VERSION ""

NS_ :

BS_:

BU_: IDC Delete_FDCA Delete_APA Delete_CMRR_FL Delete_CMRR_FR CMRR_RL CMRR_RR MRR CGW

BO_ 659 APA_6: 64 IDC
 SG_ APASlot_1_source : 2|3@0+ (1,0) [0|3] "" CGW
 SG_ APASlot__1_Direction : 4|2@0+ (1,0) [0|2] "" CGW
 SG_ APASlot_2_source : 7|3@0+ (1,0) [0|3] "" CGW
 SG_ APASlot_3_source : 10|3@0+ (1,0) [0|3] "" CGW
 SG_ APASlot__2_Direction : 12|2@0+ (1,0) [0|2] "" CGW
 SG_ APASlot_4_source : 15|3@0+ (1,0) [0|3] "" CGW
 SG_ APASlot_5_source : 18|3@0+ (1,0) [0|3] "" CGW
 SG_ APASlot__3_Direction : 20|2@0+ (1,0) [0|2] "" CGW
 SG_ APASlot_6_source : 23|3@0+ (1,0) [0|3] "" CGW
 SG_ APASlot_7_source : 26|3@0+ (1,0) [0|3] "" CGW
 SG_ APASlot__4_Direction : 28|2@0+ (1,0) [0|2] "" CGW
 SG_ APASlot_8_source : 31|3@0+ (1,0) [0|3] "" CGW
 SG_ APASlot_9_source : 34|3@0+ (1,0) [0|3] "" CGW
 SG_ APASlot__5_Direction : 36|2@0+ (1,0) [0|2] "" CGW
 SG_ APASlot_10_source : 39|3@0+ (1,0) [0|3] "" CGW
 SG_ APASlot_11_source : 42|3@0+ (1,0) [0|3] "" CGW
 SG_ APASlot__6_Direction : 44|2@0+ (1,0) [0|2] "" CGW
 SG_ APASlot_12_source : 47|3@0+ (1,0) [0|3] "" CGW
 SG_ APASlot__7_Direction : 49|2@0+ (1,0) [0|2] "" CGW
 SG_ APASlot__8_Direction : 51|2@0+ (1,0) [0|2] "" CGW
 SG_ APASlot__9_Direction : 53|2@0+ (1,0) [0|2] "" CGW
 SG_ APASlot__10_Direction : 55|2@0+ (1,0) [0|2] "" CGW
 SG_ APASlot__11_Direction : 57|2@0+ (1,0) [0|2] "" CGW
 SG_ APASlot__12_Direction : 59|2@0+ (1,0) [0|2] "" CGW
 SG_ APASlot__13_Direction : 61|2@0+ (1,0) [0|2] "" CGW
 SG_ APASlot__14_Direction : 63|2@0+ (1,0) [0|2] "" CGW
 SG_ APASlot__1_Type : 65|2@0+ (1,0) [0|3] "" CGW
 SG_ APASlot__2_Type : 67|2@0+ (1,0) [0|3] "" CGW
 SG_ APASlot__3_Type : 69|2@0+ (1,0) [0|3] "" CGW
 SG_ APASlot__4_Type : 71|2@0+ (1,0) [0|3] "" CGW
 SG_ APASlot__5_Type : 73|2@0+ (1,0) [0|3] "" CGW
 SG_ APASlot__6_Type : 75|2@0+ (1,0) [0|3] "" CGW
 SG_ APASlot__7_Type : 77|2@0+ (1,0) [0|3] "" CGW
 SG_ APASlot__8_Type : 79|2@0+ (1,0) [0|3] "" CGW
 SG_ APASlot__9_Type : 81|2@0+ (1,0) [0|3] "" CGW
 SG_ APASlot__10_Type : 83|2@0+ (1,0) [0|3] "" CGW
 SG_ APASlot__11_Type : 85|2@0+ (1,0) [0|3] "" CGW
 SG_ APASlot__12_Type : 87|2@0+ (1,0) [0|3] "" CGW
 SG_ SlotTarg_ID : 95|8@0+ (1,0) [1|255] "" CGW
 SG_ Slot1_ID : 103|8@0+ (1,0) [1|255] "" CGW
 SG_ Slot2_ID : 111|8@0+ (1,0) [1|255] "" CGW
 SG_ Slot3_ID : 119|8@0+ (1,0) [1|255] "" CGW
 SG_ Slot4_ID : 127|8@0+ (1,0) [1|255] "" CGW
 SG_ Slot5_ID : 135|8@0+ (1,0) [1|255] "" CGW
 SG_ Slot6_ID : 143|8@0+ (1,0) [1|255] "" CGW
 SG_ Slot7_ID : 151|8@0+ (1,0) [1|255] "" CGW
 SG_ Slot8_ID : 159|8@0+ (1,0) [1|255] "" CGW
 SG_ Slot9_ID : 167|8@0+ (1,0) [1|255] "" CGW
 SG_ Slot10_ID : 175|8@0+ (1,0) [1|255] "" CGW
 SG_ Slot11_ID : 183|8@0+ (1,0) [1|255] "" CGW
 SG_ Slot12_ID : 191|8@0+ (1,0) [1|255] "" CGW
 SG_ SlotTargACoorX : 199|8@0+ (12,-2000) [-2000|1060] "cm" CGW
 SG_ SlotTargACoorY : 207|8@0+ (16,-2000) [-2000|2080] "cm" CGW
 SG_ SlotTargBCoorX : 215|8@0+ (12,-2000) [-2000|1060] "cm" CGW
 SG_ SlotTargBCoorY : 223|8@0+ (16,-2000) [-2000|2080] "cm" CGW
 SG_ SlotTargCCoorX : 231|8@0+ (12,-2000) [-2000|1060] "cm" CGW
 SG_ SlotTargCCoorY : 239|8@0+ (16,-2000) [-2000|2080] "cm" CGW
 SG_ SlotTargDCoorX : 247|8@0+ (12,-2000) [-2000|1060] "cm" CGW
 SG_ SlotTargDCoorY : 255|8@0+ (16,-2000) [-2000|2080] "cm" CGW
 SG_ Slot1ACoorX : 263|8@0+ (12,-2000) [-2000|1060] "cm" CGW
 SG_ Slot1ACoorY : 271|8@0+ (16,-2000) [-2000|2080] "cm" CGW
 SG_ Slot1BCoorX : 279|8@0+ (12,-2000) [-2000|1060] "cm" CGW
 SG_ Slot1BCoorY : 287|8@0+ (16,-2000) [-2000|2080] "cm" CGW
 SG_ Slot1CCoorX : 295|8@0+ (12,-2000) [-2000|1060] "cm" CGW
 SG_ Slot1CCoorY : 303|8@0+ (16,-2000) [-2000|2080] "cm" CGW
 SG_ Slot1DCoorX : 311|8@0+ (12,-2000) [-2000|1060] "cm" CGW
 SG_ Slot1DCoorY : 319|8@0+ (16,-2000) [-2000|2080] "cm" CGW
 SG_ Slot2ACoorX : 327|8@0+ (12,-2000) [-2000|1060] "cm" CGW
 SG_ Slot2ACoorY : 335|8@0+ (16,-2000) [-2000|2080] "cm" CGW
 SG_ Slot2BCoorX : 343|8@0+ (12,-2000) [-2000|1060] "cm" CGW
 SG_ Slot2BCoorY : 351|8@0+ (16,-2000) [-2000|2080] "cm" CGW
 SG_ Slot2CCoorX : 359|8@0+ (12,-2000) [-2000|1060] "cm" CGW
 SG_ Slot2CCoorY : 367|8@0+ (16,-2000) [-2000|2080] "cm" CGW
 SG_ Slot2DCoorX : 375|8@0+ (12,-2000) [-2000|1060] "cm" CGW
 SG_ Slot2DCoorY : 383|8@0+ (16,-2000) [-2000|2080] "cm" CGW
 SG_ Slot3ACoorX : 391|8@0+ (12,-2000) [-2000|1060] "cm" CGW
 SG_ Slot3ACoorY : 399|8@0+ (16,-2000) [-2000|2080] "cm" CGW
 SG_ Slot3BCoorX : 407|8@0+ (12,-2000) [-2000|1060] "cm" CGW
 SG_ Slot3BCoorY : 415|8@0+ (16,-2000) [-2000|2080] "cm" CGW
 SG_ Slot3CCoorX : 423|8@0+ (12,-2000) [-2000|1060] "cm" CGW
 SG_ Slot3CCoorY : 431|8@0+ (16,-2000) [-2000|2080] "cm" CGW
 SG_ Slot3DCoorX : 439|8@0+ (12,-2000) [-2000|1060] "cm" CGW
 SG_ Slot3DCoorY : 447|8@0+ (16,-2000) [-2000|2080] "cm" CGW
 SG_ Slot4ACoorX : 455|8@0+ (12,-2000) [-2000|1060] "cm" CGW
 SG_ Slot4ACoorY : 463|8@0+ (16,-2000) [-2000|2080] "cm" CGW
 SG_ Slot4BCoorX : 471|8@0+ (12,-2000) [-2000|1060] "cm" CGW
 SG_ Slot4BCoorY : 479|8@0+ (16,-2000) [-2000|2080] "cm" CGW
 SG_ Slot4CCoorX : 487|8@0+ (12,-2000) [-2000|1060] "cm" CGW
 SG_ Slot4CCoorY : 495|8@0+ (16,-2000) [-2000|2080] "cm" CGW
 SG_ Slot4DCoorX : 503|8@0+ (12,-2000) [-2000|1060] "cm" CGW
 SG_ Slot4DCoorY : 511|8@0+ (16,-2000) [-2000|2080] "cm" CGW

BO_ 660 APA_7: 64 IDC
 SG_ Slot5ACoorX : 7|8@0+ (12,-2000) [-2000|1060] "cm" CGW
 SG_ Slot5ACoorY : 15|8@0+ (16,-2000) [-2000|2080] "cm" CGW
 SG_ Slot5BCoorX : 23|8@0+ (12,-2000) [-2000|1060] "cm" CGW
 SG_ Slot5BCoorY : 31|8@0+ (16,-2000) [-2000|2080] "cm" CGW
 SG_ Slot5CCoorX : 39|8@0+ (12,-2000) [-2000|1060] "cm" CGW
 SG_ Slot5CCoorY : 47|8@0+ (16,-2000) [-2000|2080] "cm" CGW
 SG_ Slot5DCoorX : 55|8@0+ (12,-2000) [-2000|1060] "cm" CGW
 SG_ Slot5DCoorY : 63|8@0+ (16,-2000) [-2000|2080] "cm" CGW
 SG_ Slot6ACoorX : 71|8@0+ (12,-2000) [-2000|1060] "cm" CGW
 SG_ Slot6ACoorY : 79|8@0+ (16,-2000) [-2000|2080] "cm" CGW
 SG_ Slot6BCoorX : 87|8@0+ (12,-2000) [-2000|1060] "cm" CGW
 SG_ Slot6BCoorY : 95|8@0+ (16,-2000) [-2000|2080] "cm" CGW
 SG_ Slot6CCoorX : 103|8@0+ (12,-2000) [-2000|1060] "cm" CGW
 SG_ Slot6CCoorY : 111|8@0+ (16,-2000) [-2000|2080] "cm" CGW
 SG_ Slot6DCoorX : 119|8@0+ (12,-2000) [-2000|1060] "cm" CGW
 SG_ Slot6DCoorY : 127|8@0+ (16,-2000) [-2000|2080] "cm" CGW
 SG_ Slot7ACoorX : 135|8@0+ (12,-2000) [-2000|1060] "cm" CGW
 SG_ Slot7ACoorY : 143|8@0+ (16,-2000) [-2000|2080] "cm" CGW
 SG_ Slot7BCoorX : 151|8@0+ (12,-2000) [-2000|1060] "cm" CGW
 SG_ Slot7BCoorY : 159|8@0+ (16,-2000) [-2000|2080] "cm" CGW
 SG_ Slot7CCoorX : 167|8@0+ (12,-2000) [-2000|1060] "cm" CGW
 SG_ Slot7CCoorY : 175|8@0+ (16,-2000) [-2000|2080] "cm" CGW
 SG_ Slot7DCoorX : 183|8@0+ (12,-2000) [-2000|1060] "cm" CGW
 SG_ Slot7DCoorY : 191|8@0+ (16,-2000) [-2000|2080] "cm" CGW
 SG_ Slot8ACoorX : 199|8@0+ (12,-2000) [-2000|1060] "cm" CGW
 SG_ Slot8ACoorY : 207|8@0+ (16,-2000) [-2000|2080] "cm" CGW
 SG_ Slot8BCoorX : 215|8@0+ (12,-2000) [-2000|1060] "cm" CGW
 SG_ Slot8BCoorY : 223|8@0+ (16,-2000) [-2000|2080] "cm" CGW
 SG_ Slot8CCoorX : 231|8@0+ (12,-2000) [-2000|1060] "cm" CGW
 SG_ Slot8CCoorY : 239|8@0+ (16,-2000) [-2000|2080] "cm" CGW
 SG_ Slot8DCoorX : 247|8@0+ (12,-2000) [-2000|1060] "cm" CGW
 SG_ Slot8DCoorY : 255|8@0+ (16,-2000) [-2000|2080] "cm" CGW
 SG_ Slot9ACoorX : 263|8@0+ (12,-2000) [-2000|1060] "cm" CGW
 SG_ Slot9ACoorY : 271|8@0+ (16,-2000) [-2000|2080] "cm" CGW
 SG_ Slot9BCoorX : 279|8@0+ (12,-2000) [-2000|1060] "cm" CGW
 SG_ Slot9BCoorY : 287|8@0+ (16,-2000) [-2000|2080] "cm" CGW
 SG_ Slot9CCoorX : 295|8@0+ (12,-2000) [-2000|1060] "cm" CGW
 SG_ Slot9CCoorY : 303|8@0+ (16,-2000) [-2000|2080] "cm" CGW
 SG_ Slot9DCoorX : 311|8@0+ (12,-2000) [-2000|1060] "cm" CGW
 SG_ Slot9DCoorY : 319|8@0+ (16,-2000) [-2000|2080] "cm" CGW
 SG_ Slot10ACoorX : 327|8@0+ (12,-2000) [-2000|1060] "cm" CGW
 SG_ Slot10ACoorY : 335|8@0+ (16,-2000) [-2000|2080] "cm" CGW
 SG_ Slot10BCoorX : 343|8@0+ (12,-2000) [-2000|1060] "cm" CGW
 SG_ Slot10BCoorY : 351|8@0+ (16,-2000) [-2000|2080] "cm" CGW
 SG_ Slot10CCoorX : 359|8@0+ (12,-2000) [-2000|1060] "cm" CGW
 SG_ Slot10CCoorY : 367|8@0+ (16,-2000) [-2000|2080] "cm" CGW
 SG_ Slot10DCoorX : 375|8@0+ (12,-2000) [-2000|1060] "cm" CGW
 SG_ Slot10DCoorY : 383|8@0+ (16,-2000) [-2000|2080] "cm" CGW
 SG_ Slot11ACoorX : 391|8@0+ (12,-2000) [-2000|1060] "cm" CGW
 SG_ Slot11ACoorY : 399|8@0+ (16,-2000) [-2000|2080] "cm" CGW
 SG_ Slot11BCoorX : 407|8@0+ (12,-2000) [-2000|1060] "cm" CGW
 SG_ Slot11BCoorY : 415|8@0+ (16,-2000) [-2000|2080] "cm" CGW
 SG_ Slot11CCoorX : 423|8@0+ (12,-2000) [-2000|1060] "cm" CGW
 SG_ Slot11CCoorY : 431|8@0+ (16,-2000) [-2000|2080] "cm" CGW
 SG_ Slot11DCoorX : 439|8@0+ (12,-2000) [-2000|1060] "cm" CGW
 SG_ Slot11DCoorY : 447|8@0+ (16,-2000) [-2000|2080] "cm" CGW
 SG_ Slot12ACoorX : 455|8@0+ (12,-2000) [-2000|1060] "cm" CGW
 SG_ Slot12ACoorY : 463|8@0+ (16,-2000) [-2000|2080] "cm" CGW
 SG_ Slot12BCoorX : 471|8@0+ (12,-2000) [-2000|1060] "cm" CGW
 SG_ Slot12BCoorY : 479|8@0+ (16,-2000) [-2000|2080] "cm" CGW
 SG_ Slot12CCoorX : 487|8@0+ (12,-2000) [-2000|1060] "cm" CGW
 SG_ Slot12CCoorY : 495|8@0+ (16,-2000) [-2000|2080] "cm" CGW
 SG_ Slot12DCoorX : 503|8@0+ (12,-2000) [-2000|1060] "cm" CGW
 SG_ Slot12DCoorY : 511|8@0+ (16,-2000) [-2000|2080] "cm" CGW

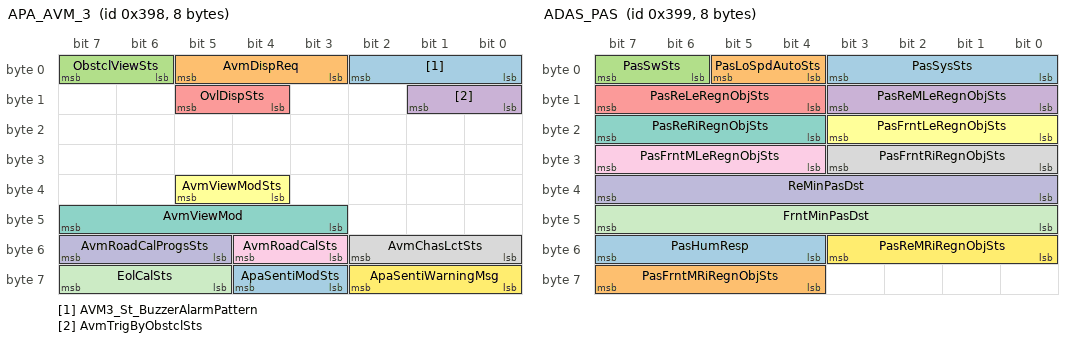
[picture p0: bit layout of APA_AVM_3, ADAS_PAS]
BO_ 920 APA_AVM_3: 8 IDC
 SG_ AVM3_St_BuzzerAlarmPattern : 2|3@0+ (1,0) [0|7] "" CGW
 SG_ AvmDispReq : 5|3@0+ (1,0) [0|7] "" CGW
 SG_ ObstclViewSts : 7|2@0+ (1,0) [0|3] "" CGW
 SG_ AvmTrigByObstclSts : 9|2@0+ (1,0) [0|3] "" CGW
 SG_ OvlDispSts : 13|2@0+ (1,0) [0|3] "" CGW
 SG_ AvmViewModSts : 37|2@0+ (1,0) [0|3] "" CGW
 SG_ AvmViewMod : 47|5@0+ (1,0) [0|31] "" CGW
 SG_ AvmChasLctSts : 50|3@0+ (1,0) [0|7] "" CGW
 SG_ AvmRoadCalSts : 52|2@0+ (1,0) [0|3] "" CGW
 SG_ AvmRoadCalProgsSts : 55|3@0+ (1,0) [0|7] "" CGW
 SG_ EolCalSts : 63|3@0+ (1,0) [0|7] "" CGW
 SG_ ApaSentiWarningMsg : 58|3@0+ (1,0) [0|7] "" CGW
 SG_ ApaSentiModSts : 60|2@0+ (1,0) [0|3] "" CGW

BO_ 921 ADAS_PAS: 8 IDC
 SG_ PasSysSts : 3|4@0+ (1,0) [0|7] "" CGW
 SG_ PasLoSpdAutoSts : 5|2@0+ (1,0) [0|3] "" CGW
 SG_ PasSwSts : 7|2@0+ (1,0) [0|3] "" CGW
 SG_ PasReMLeRegnObjSts : 11|4@0+ (1,0) [0|15] "" CGW
 SG_ PasReLeRegnObjSts : 15|4@0+ (1,0) [0|15] "" CGW
 SG_ PasFrntLeRegnObjSts : 19|4@0+ (1,0) [0|15] "" CGW
 SG_ PasReRiRegnObjSts : 23|4@0+ (1,0) [0|15] "" CGW
 SG_ PasFrntRiRegnObjSts : 27|4@0+ (1,0) [0|15] "" CGW
 SG_ PasFrntMLeRegnObjSts : 31|4@0+ (1,0) [0|15] "" CGW
 SG_ ReMinPasDst : 39|8@0+ (1,0) [0|255] "cm" CGW
 SG_ FrntMinPasDst : 47|8@0+ (1,0) [0|255] "cm" CGW
 SG_ PasReMRiRegnObjSts : 51|4@0+ (1,0) [0|15] "" CGW
 SG_ PasHumResp : 55|4@0+ (1,0) [0|15] "" CGW
 SG_ PasFrntMRiRegnObjSts : 63|4@0+ (1,0) [0|15] "" CGW

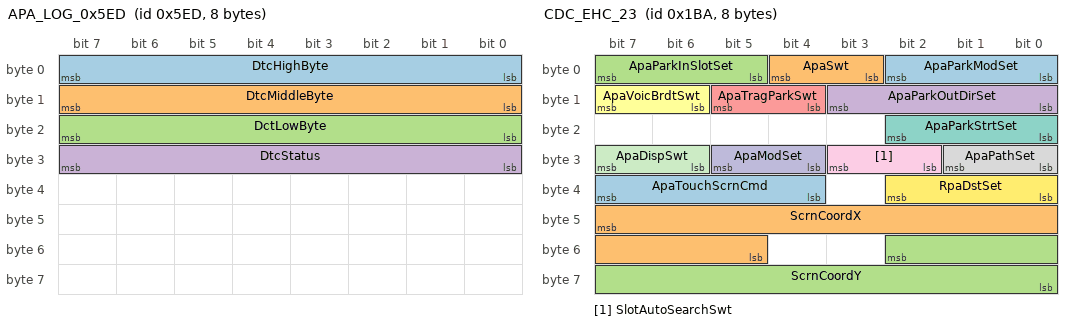
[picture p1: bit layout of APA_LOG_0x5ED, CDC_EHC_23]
BO_ 1517 APA_LOG_0x5ED: 8 IDC
 SG_ DtcHighByte : 7|8@0+ (1,0) [0|255] "" CGW
 SG_ DtcMiddleByte : 15|8@0+ (1,0) [0|255] "" Vector__XXX
 SG_ DctLowByte : 23|8@0+ (1,0) [0|255] "" Vector__XXX
 SG_ DtcStatus : 31|8@0+ (1,0) [0|255] "" Vector__XXX

BO_ 442 CDC_EHC_23: 8 CGW
 SG_ ApaParkModSet : 2|3@0+ (1,0) [0|7] "" IDC,Delete_APA
 SG_ ApaSwt : 4|2@0+ (1,0) [0|3] "" IDC,Delete_APA
 SG_ ApaParkInSlotSet : 7|3@0+ (1,0) [0|7] "" IDC,Delete_APA
 SG_ ApaParkOutDirSet : 11|4@0+ (1,0) [0|15] "" IDC,Delete_APA
 SG_ ApaTragParkSwt : 13|2@0+ (1,0) [0|3] "" IDC,Delete_APA
 SG_ ApaVoicBrdtSwt : 15|2@0+ (1,0) [0|3] "" IDC,Delete_APA
 SG_ ApaParkStrtSet : 18|3@0+ (1,0) [0|7] "" IDC,Delete_APA
 SG_ ApaPathSet : 25|2@0+ (1,0) [0|3] "" IDC,Delete_APA
 SG_ SlotAutoSearchSwt : 27|2@0+ (1,0) [0|3] "" IDC,Delete_APA
 SG_ ApaModSet : 29|2@0+ (1,0) [0|3] "" IDC,Delete_APA
 SG_ ApaDispSwt : 31|2@0+ (1,0) [0|3] "" IDC,Delete_APA
 SG_ RpaDstSet : 34|3@0+ (1,0) [0|7] "" IDC,Delete_APA
 SG_ ApaTouchScrnCmd : 39|4@0+ (1,0) [0|15] "" IDC,Delete_APA
 SG_ ScrnCoordX : 47|11@0+ (1,0) [0|1919] "" IDC,Delete_APA
 SG_ ScrnCoordY : 50|11@0+ (1,0) [0|1079] "" IDC,Delete_APA

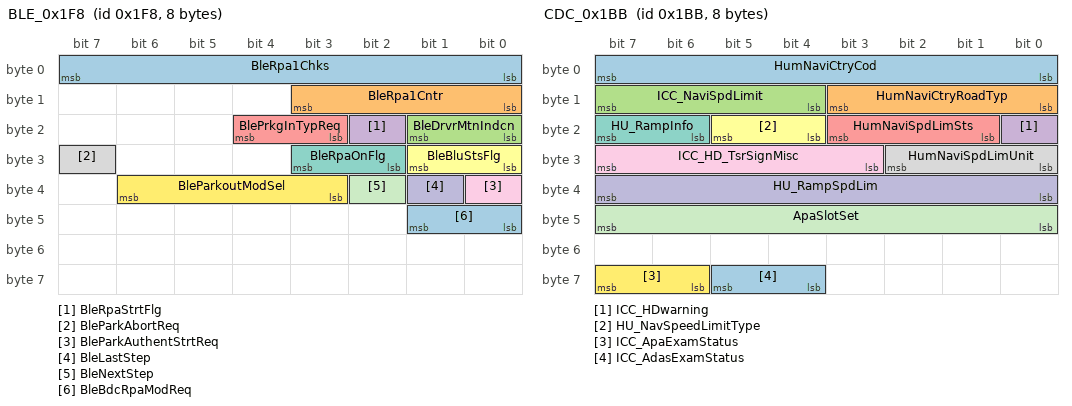
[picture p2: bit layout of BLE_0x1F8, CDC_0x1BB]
BO_ 504 BLE_0x1F8: 8 CGW
 SG_ BleRpa1Chks : 7|8@0+ (1,0) [0|255] "" IDC,Delete_APA
 SG_ BleRpa1Cntr : 11|4@0+ (1,0) [0|14] "" IDC,Delete_APA
 SG_ BleDrvrMtnIndcn : 17|2@0+ (1,0) [0|3] "" IDC,Delete_APA
 SG_ BleRpaStrtFlg : 18|1@0+ (1,0) [0|1] "" IDC,Delete_APA
 SG_ BlePrkgInTypReq : 20|2@0+ (1,0) [0|3] "" IDC,Delete_APA
 SG_ BleBluStsFlg : 25|2@0+ (1,0) [0|3] "" IDC,Delete_APA
 SG_ BleRpaOnFlg : 27|2@0+ (1,0) [0|3] "" IDC,Delete_APA
 SG_ BleParkAbortReq : 31|1@0+ (1,0) [0|1] "" IDC,Delete_APA
 SG_ BleParkAuthentStrtReq : 32|1@0+ (1,0) [0|1] "" IDC,Delete_APA
 SG_ BleLastStep : 33|1@0+ (1,0) [0|1] "" IDC,Delete_APA
 SG_ BleNextStep : 34|1@0+ (1,0) [0|1] "" IDC,Delete_APA
 SG_ BleParkoutModSel : 38|4@0+ (1,0) [0|15] "" IDC,Delete_APA
 SG_ BleBdcRpaModReq : 41|2@0+ (1,0) [0|3] "" IDC,Delete_APA

BO_ 822 BLE_0x336: 8 CGW
 SG_ BleStrtEng : 1|1@0+ (1,0) [0|1] "" IDC,Delete_APA
 SG_ BleBtSts : 60|2@0+ (1,0) [0|3] "" IDC,Delete_APA

BO_ 823 BLE_0x337: 8 CGW
 SG_ BleSysSts : 7|1@0+ (1,0) [0|1] "" IDC,Delete_APA

BO_ 443 CDC_0x1BB: 8 CGW
 SG_ HumNaviCtryCod : 7|8@0+ (1,0) [0|255] "" IDC,Delete_FDCA
 SG_ HumNaviCtryRoadTyp : 11|4@0+ (1,0) [0|15] "" IDC,Delete_FDCA
 SG_ ICC_NaviSpdLimit : 15|4@0+ (1,0) [0|15] "KPH" IDC,Delete_FDCA
 SG_ ICC_HDwarning : 16|1@0+ (1,0) [0|1] "" IDC,Delete_FDCA
 SG_ HumNaviSpdLimSts : 19|3@0+ (1,0) [0|7] "" IDC,Delete_FDCA
 SG_ HU_NavSpeedLimitType : 21|2@0+ (1,0) [0|3] "" IDC,Delete_FDCA
 SG_ HU_RampInfo : 23|2@0+ (1,0) [0|3] "" IDC,Delete_FDCA
 SG_ HumNaviSpdLimUnit : 26|3@0+ (1,0) [0|7] "" IDC,Delete_FDCA
 SG_ ICC_HD_TsrSignMisc : 31|5@0+ (1,0) [0|31] "" IDC,Delete_FDCA
 SG_ HU_RampSpdLim : 39|8@0+ (1,0) [0|255] "" IDC,Delete_FDCA
 SG_ ApaSlotSet : 47|8@0+ (1,0) [0|255] "" IDC,Delete_FDCA,Delete_APA
 SG_ ICC_ApaExamStatus : 63|2@0+ (1,0) [0|3] "" IDC
 SG_ ICC_AdasExamStatus : 61|2@0+ (1,0) [0|3] "" IDC

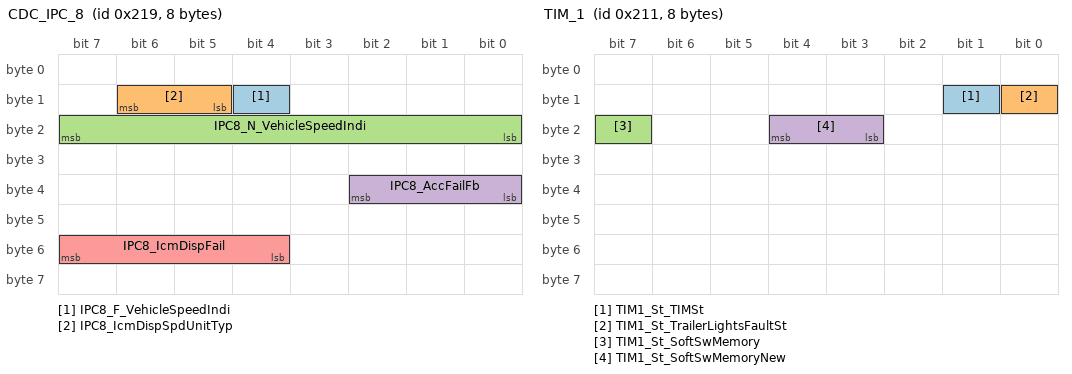
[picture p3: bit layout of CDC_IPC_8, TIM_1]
BO_ 537 CDC_IPC_8: 8 CGW
 SG_ IPC8_F_VehicleSpeedIndi : 12|1@0+ (1,0) [0|1] "" IDC
 SG_ IPC8_IcmDispSpdUnitTyp : 14|2@0+ (1,0) [0|3] "" IDC,Delete_FDCA
 SG_ IPC8_N_VehicleSpeedIndi : 23|8@0+ (1,0) [0|255] "km/h" IDC,Delete_APA
 SG_ IPC8_AccFailFb : 34|3@0+ (1,0) [0|7] "" IDC,Delete_FDCA
 SG_ IPC8_IcmDispFail : 55|4@0+ (1,0) [0|15] "" IDC,Delete_FDCA

BO_ 858 BDC_BCM_12: 8 CGW
 SG_ BCM12_St_VehicleMode : 23|3@0+ (1,0) [0|7] "" IDC,Delete_FDCA,Delete_APA

BO_ 529 TIM_1: 8 CGW
 SG_ TIM1_St_TIMSt : 9|1@0+ (1,0) [0|1] "" IDC,Delete_FDCA,Delete_APA,Delete_CMRR_FL,Delete_CMRR_FR,CMRR_RL,CMRR_RR,MRR
 SG_ TIM1_St_TrailerLightsFaultSt : 8|1@0+ (1,0) [0|1] "" IDC,Delete_FDCA,Delete_APA,Delete_CMRR_FL,Delete_CMRR_FR,CMRR_RL,CMRR_RR,MRR
 SG_ TIM1_St_SoftSwMemory : 23|1@0+ (1,0) [0|1] "" IDC,Delete_FDCA,Delete_APA,Delete_CMRR_FL,Delete_CMRR_FR,CMRR_RL,CMRR_RR,MRR
 SG_ TIM1_St_SoftSwMemoryNew : 20|2@0+ (1,0) [0|3] "" IDC,CMRR_RL,CMRR_RR,MRR

BO_ 225 CDC_EHC_24: 8 CGW
 SG_ EHC12_St_AVMSaleCalibration : 18|2@0+ (1,0) [0|3] "" IDC,Delete_APA
 SG_ EHC24_ParkingPlaceConfirm : 19|1@0+ (1,0) [0|1] "" IDC,Delete_APA
 SG_ AvmViewSet : 31|5@0+ (1,0) [0|31] "" IDC,Delete_APA
 SG_ AvmViewModSet : 33|2@0+ (1,0) [0|3] "" IDC,Delete_APA
 SG_ OvlyDispSwt : 35|2@0+ (1,0) [0|3] "" IDC,Delete_APA
 SG_ ObstclViewSwt : 37|2@0+ (1,0) [0|3] "" IDC,Delete_APA
 SG_ AvmTrigByObstclSwt : 47|2@0+ (1,0) [0|3] "" IDC,Delete_APA
 SG_ AvmSwt : 45|2@0+ (1,0) [0|3] "" IDC,Delete_APA
 SG_ PasSwt : 43|2@0+ (1,0) [0|3] "" IDC,Delete_APA
 SG_ EHC24_ExitButton : 41|1@0+ (1,0) [0|1] "" IDC,Delete_APA
 SG_ EHC12_Set_RestoreSetting : 40|1@0+ (1,0) [0|1] "" IDC,Delete_APA
 SG_ AvmVehLctSet : 50|3@0+ (1,0) [0|7] "" IDC,Delete_APA
 SG_ EHC24_AVM_WormMode_Set : 51|1@0+ (1,0) [0|1] "" IDC,Delete_APA
 SG_ EHCV24_AVM_RockMode_Set : 52|1@0+ (1,0) [0|1] "" IDC,Delete_APA
 SG_ AvmChasLctSet : 55|3@0+ (1,0) [0|7] "" IDC,Delete_APA
 SG_ AvmRoadCalSwt : 58|2@0+ (1,0) [0|3] "" IDC,Delete_APA
 SG_ EHC12_St_SoftwareUpdate : 59|1@0+ (1,0) [0|1] "" IDC,Delete_APA
 SG_ EHC12_St_AVMRoadCalibration : 61|2@0+ (1,0) [0|3] "" IDC,Delete_APA
 SG_ EHC12_St_AVMFactoryCalibration : 63|2@0+ (1,0) [0|3] "" IDC,Delete_APA

BO_ 237 CDC_EHC_22: 8 CGW
 SG_ EHC22_NOA_ALCRequest_confirm : 7|2@0+ (1,0) [0|3] "" IDC,Delete_FDCA
 SG_ EHC22_NOA_ALC_TYPE : 5|2@0+ (1,0) [0|3] "" IDC,Delete_FDCA
 SG_ EHC22_NOA_ALC_soundnotification : 3|2@0+ (1,0) [0|3] "" IDC,Delete_FDCA
 SG_ EHC22_HWA_EnbSw : 1|2@0+ (1,0) [0|3] "" IDC,Delete_FDCA
 SG_ EHC22_TJA_ICA_EnbSw : 15|2@0+ (1,0) [0|3] "" IDC,Delete_FDCA
 SG_ EHC22_IntelligentCornering_EnbSw : 13|2@0+ (1,0) [0|3] "" IDC,Delete_FDCA
 SG_ EHC22_ESS_EnbSw : 11|2@0+ (1,0) [0|3] "" IDC,Delete_FDCA
 SG_ EHC22_LKA_EnbSw : 9|2@0+ (1,0) [0|3] "" IDC,Delete_FDCA
 SG_ EHC22_LDW_EnbSw : 23|2@0+ (1,0) [0|3] "" IDC,Delete_FDCA
 SG_ EHC22_BSD_LCA_EnbSw : 21|2@0+ (1,0) [0|3] "" IDC,Delete_FDCA,Delete_CMRR_FL,Delete_CMRR_FR,CMRR_RL,CMRR_RR,MRR
 SG_ EHC22_DOW_EnbSw : 19|2@0+ (1,0) [0|3] "" IDC,Delete_FDCA,Delete_CMRR_FL,Delete_CMRR_FR,CMRR_RL,CMRR_RR,MRR
 SG_ EHC22_ELK_EnbSw : 17|2@0+ (1,0) [0|3] "" IDC,Delete_FDCA
 SG_ EHC22_AVM_EnbSw : 31|2@0+ (1,0) [0|3] "" IDC,Delete_FDCA
 SG_ EHC22_HMA_EnbSw : 29|2@0+ (1,0) [0|3] "" IDC,Delete_FDCA
 SG_ EHC22_BAV_EnbSw : 27|2@0+ (1,0) [0|3] "" IDC,Delete_FDCA
 SG_ EHC22_LCK_EnbSw : 25|2@0+ (1,0) [0|3] "" IDC,Delete_FDCA
 SG_ EHC22_ASLSw : 33|2@0+ (1,0) [0|3] "" IDC,Delete_FDCA
 SG_ EHC22_Set_FcwSwt : 35|2@0+ (1,0) [0|3] "" IDC,Delete_FDCA
 SG_ EHC22_Set_FCTA : 37|2@0+ (1,0) [0|1] "" IDC,Delete_FDCA,Delete_CMRR_FL,Delete_CMRR_FR,CMRR_RL,CMRR_RR,MRR
 SG_ EHC22_Set_FCTB : 39|2@0+ (1,0) [0|1] "" IDC,Delete_FDCA,Delete_CMRR_FL,Delete_CMRR_FR,CMRR_RL,CMRR_RR,MRR
 SG_ EHC22_Set_LDWLKALCKSen : 41|2@0+ (1,0) [0|3] "" IDC,Delete_FDCA
 SG_ EHC22_Sw_LDWLKALCK : 43|2@0+ (1,0) [0|3] "" IDC,Delete_FDCA
 SG_ EHC22_St_LDWLKALCKSet : 46|3@0+ (1,0) [0|7] "" IDC,Delete_FDCA
 SG_ EHC22_NOAFct_EnbSw : 50|2@0+ (1,0) [0|3] "" IDC,Delete_FDCA
 SG_ EHC22_SDA_EnbSw : 53|2@0+ (1,0) [0|3] "" IDC,Delete_FDCA
 SG_ EHC22_Set_JA : 55|2@0+ (1,0) [0|3] "" IDC,Delete_FDCA,Delete_CMRR_FL,Delete_CMRR_FR,CMRR_RL,CMRR_RR,MRR
 SG_ EHC22_CDCShowoffset : 57|2@0+ (1,0) [0|3] "" IDC,Delete_FDCA
 SG_ EHC22_Set_ELKSen : 59|2@0+ (1,0) [0|3] "" IDC,Delete_FDCA

BO_ 661 APA_8: 64 IDC
 SG_ HPA_ObjLatDst1 : 7|8@0+ (0.1,-12.75) [-12.75|12.75] "m" CGW
 SG_ HPA_ObjLgtDst1 : 15|8@0+ (0.2,-25.5) [-25.5|25.5] "m" CGW
 SG_ HPA_ObjTyp1 : 23|4@0+ (1,0) [0|15] "" CGW
 SG_ HPA_ObjMovmtDir1 : 19|2@0+ (1,0) [0|3] "" CGW
 SG_ HPA_ObjPosnAgl1 : 17|10@0+ (0.01,-3.14) [-3.14|3.14] "rad" CGW
 SG_ HPA_ObjLatDst2 : 39|8@0+ (0.1,-12.75) [-12.75|12.75] "m" CGW
 SG_ HPA_ObjLgtDst2 : 47|8@0+ (0.2,-25.5) [-25.5|25.5] "m" CGW
 SG_ HPA_ObjTyp2 : 55|4@0+ (1,0) [0|15] "" CGW
 SG_ HPA_ObjMovmtDir2 : 51|2@0+ (1,0) [0|3] "" CGW
 SG_ HPA_ObjPosnAgl2 : 49|10@0+ (0.01,-3.14) [-3.14|3.14] "rad" CGW
 SG_ HPA_ObjLatDst3 : 71|8@0+ (0.1,-12.75) [-12.75|12.75] "m" CGW
 SG_ HPA_ObjLgtDst3 : 79|8@0+ (0.2,-25.5) [-25.5|25.5] "m" CGW
 SG_ HPA_ObjTyp3 : 87|4@0+ (1,0) [0|15] "" CGW
 SG_ HPA_ObjMovmtDir3 : 83|2@0+ (1,0) [0|3] "" CGW
 SG_ HPA_ObjPosnAgl3 : 81|10@0+ (0.01,-3.14) [-3.14|3.14] "rad" CGW
 SG_ HPA_ObjLatDst4 : 103|8@0+ (0.1,-12.75) [-12.75|12.75] "m" CGW
 SG_ HPA_ObjLgtDst4 : 111|8@0+ (0.2,-25.5) [-25.5|25.5] "m" CGW
 SG_ HPA_ObjTyp4 : 119|4@0+ (1,0) [0|15] "" CGW
 SG_ HPA_ObjMovmtDir4 : 115|2@0+ (1,0) [0|3] "" CGW
 SG_ HPA_ObjPosnAgl4 : 113|10@0+ (0.01,-3.14) [-3.14|3.14] "rad" CGW
 SG_ HPA_ObjLatDst5 : 135|8@0+ (0.1,-12.75) [-12.75|12.75] "m" CGW
 SG_ HPA_ObjLgtDst5 : 143|8@0+ (0.2,-25.5) [-25.5|25.5] "m" CGW
 SG_ HPA_ObjTyp5 : 151|4@0+ (1,0) [0|15] "" CGW
 SG_ HPA_ObjMovmtDir5 : 147|2@0+ (1,0) [0|3] "" CGW
 SG_ HPA_ObjPosnAgl5 : 145|10@0+ (0.01,-3.14) [-3.14|3.14] "rad" CGW
 SG_ HPA_ObjLatDst6 : 167|8@0+ (0.1,-12.75) [-12.75|12.75] "m" CGW
 SG_ HPA_ObjLgtDst6 : 175|8@0+ (0.2,-25.5) [-25.5|25.5] "m" CGW
 SG_ HPA_ObjTyp6 : 183|4@0+ (1,0) [0|15] "" CGW
 SG_ HPA_ObjMovmtDir6 : 179|2@0+ (1,0) [0|3] "" CGW
 SG_ HPA_ObjPosnAgl6 : 177|10@0+ (0.01,-3.14) [-3.14|3.14] "rad" CGW
 SG_ HPA_ObjLatDst7 : 199|8@0+ (0.1,-12.75) [-12.75|12.75] "m" CGW
 SG_ HPA_ObjLgtDst7 : 207|8@0+ (0.2,-25.5) [-25.5|25.5] "m" CGW
 SG_ HPA_ObjTyp7 : 215|4@0+ (1,0) [0|15] "" CGW
 SG_ HPA_ObjMovmtDir7 : 211|2@0+ (1,0) [0|3] "" CGW
 SG_ HPA_ObjPosnAgl7 : 209|10@0+ (0.01,-3.14) [-3.14|3.14] "rad" CGW
 SG_ HPA_ObjLatDst8 : 231|8@0+ (0.1,-12.75) [-12.75|12.75] "m" CGW
 SG_ HPA_ObjLgtDst8 : 239|8@0+ (0.2,-25.5) [-25.5|25.5] "m" CGW
 SG_ HPA_ObjTyp8 : 247|4@0+ (1,0) [0|15] "" CGW
 SG_ HPA_ObjMovmtDir8 : 243|2@0+ (1,0) [0|3] "" CGW
 SG_ HPA_ObjPosnAgl8 : 241|10@0+ (0.01,-3.14) [-3.14|3.14] "rad" CGW
 SG_ HPA_ObjLatDst9 : 263|8@0+ (0.1,-12.75) [-12.75|12.75] "m" CGW
 SG_ HPA_ObjLgtDst9 : 271|8@0+ (0.2,-25.5) [-25.5|25.5] "m" CGW
 SG_ HPA_ObjTyp9 : 279|4@0+ (1,0) [0|15] "" CGW
 SG_ HPA_ObjMovmtDir9 : 275|2@0+ (1,0) [0|3] "" CGW
 SG_ HPA_ObjPosnAgl9 : 273|10@0+ (0.01,-3.14) [-3.14|3.14] "rad" CGW
 SG_ HPA_ObjLatDst10 : 295|8@0+ (0.1,-12.75) [-12.75|12.75] "m" CGW
 SG_ HPA_ObjLgtDst10 : 303|8@0+ (0.2,-25.5) [-25.5|25.5] "m" CGW
 SG_ HPA_ObjTyp10 : 311|4@0+ (1,0) [0|15] "" CGW
 SG_ HPA_ObjMovmtDir10 : 307|2@0+ (1,0) [0|3] "" CGW
 SG_ HPA_ObjPosnAgl10 : 305|10@0+ (0.01,-3.14) [-3.14|3.14] "rad" CGW
 SG_ HPA_ObjLatDst11 : 327|8@0+ (0.1,-12.75) [-12.75|12.75] "m" CGW
 SG_ HPA_ObjLgtDst11 : 335|8@0+ (0.2,-25.5) [-25.5|25.5] "m" CGW
 SG_ HPA_ObjTyp11 : 343|4@0+ (1,0) [0|15] "" CGW
 SG_ HPA_ObjMovmtDir11 : 339|2@0+ (1,0) [0|3] "" CGW
 SG_ HPA_ObjPosnAgl11 : 337|10@0+ (0.01,-3.14) [-3.14|3.14] "rad" CGW
 SG_ HPA_ObjLatDst12 : 359|8@0+ (0.1,-12.75) [-12.75|12.75] "m" CGW
 SG_ HPA_ObjLgtDst12 : 367|8@0+ (0.2,-25.5) [-25.5|25.5] "m" CGW
 SG_ HPA_ObjTyp12 : 375|4@0+ (1,0) [0|15] "" CGW
 SG_ HPA_ObjMovmtDir12 : 371|2@0+ (1,0) [0|3] "" CGW
 SG_ HPA_ObjPosnAgl12 : 369|10@0+ (0.01,-3.14) [-3.14|3.14] "rad" CGW
 SG_ PasMinObjSts : 391|8@0+ (1,0) [0|255] "cm" CGW
 SG_ ApaSlot1_Sts : 394|3@0+ (1,0) [0|7] "" CGW
 SG_ ApaSlot2_Sts : 399|3@0+ (1,0) [0|7] "" CGW
 SG_ ApaSlot3_Sts : 402|3@0+ (1,0) [0|7] "" CGW
 SG_ ApaSlot4_Sts : 407|3@0+ (1,0) [0|7] "" CGW
 SG_ ApaSlot5_Sts : 410|3@0+ (1,0) [0|7] "" CGW
 SG_ ApaSlot6_Sts : 415|3@0+ (1,0) [0|7] "" CGW
 SG_ ApaSlot7_Sts : 418|3@0+ (1,0) [0|7] "" CGW
 SG_ ApaSlot8_Sts : 423|3@0+ (1,0) [0|7] "" CGW
 SG_ ApaSlot9_Sts : 426|3@0+ (1,0) [0|7] "" CGW
 SG_ ApaSlot10_Sts : 431|3@0+ (1,0) [0|7] "" CGW
 SG_ ApaSlot11_Sts : 434|3@0+ (1,0) [0|7] "" CGW
 SG_ ApaSlot12_Sts : 439|3@0+ (1,0) [0|7] "" CGW

BO_ 1408 BDC_CAPE_2: 8 CGW
 SG_ CAPE2_St_KeyIN : 15|8@0+ (1,0) [0|255] "" IDC,Delete_APA

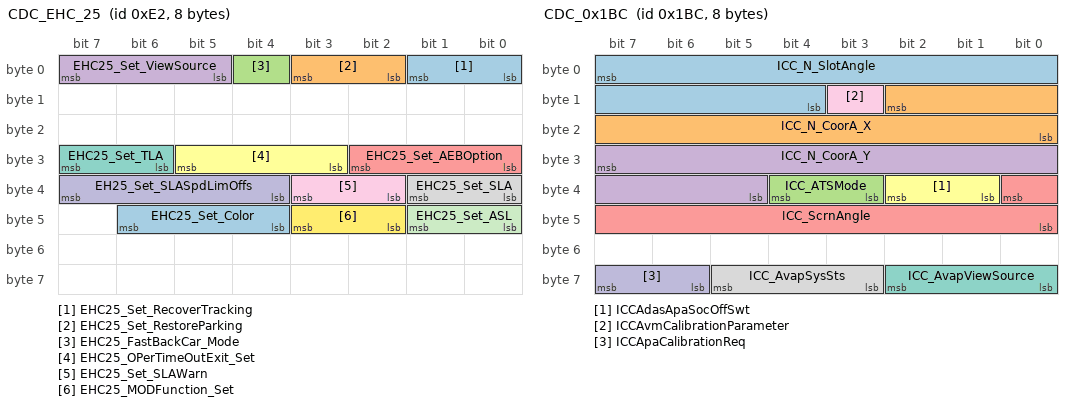
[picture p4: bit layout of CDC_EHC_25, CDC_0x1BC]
BO_ 226 CDC_EHC_25: 8 CGW
 SG_ EHC25_Set_RecoverTracking : 1|2@0+ (1,0) [0|3] "" IDC,Delete_APA
 SG_ EHC25_Set_RestoreParking : 3|2@0+ (1,0) [0|3] "" IDC,Delete_APA
 SG_ EHC25_FastBackCar_Mode : 4|1@0+ (1,0) [0|1] "bit" IDC,Delete_APA
 SG_ EHC25_Set_ViewSource : 7|3@0+ (1,0) [0|3] "" IDC,Delete_APA
 SG_ EHC25_Set_AEBOption : 26|3@0+ (1,0) [0|7] "" IDC,Delete_FDCA
 SG_ EHC25_OPerTimeOutExit_Set : 29|3@0+ (1,0) [0|7] "" IDC,Delete_APA
 SG_ EHC25_Set_TLA : 31|2@0+ (1,0) [0|3] "" IDC,Delete_FDCA
 SG_ EHC25_Set_SLA : 33|2@0+ (1,0) [0|3] "" IDC,Delete_FDCA
 SG_ EHC25_Set_SLAWarn : 35|2@0+ (1,0) [0|3] "" IDC,Delete_FDCA
 SG_ EH25_Set_SLASpdLimOffs : 39|4@0+ (1,0) [0|7] "KPH" IDC,Delete_FDCA
 SG_ EHC25_Set_ASL : 41|2@0+ (1,0) [0|3] "" IDC,Delete_FDCA
 SG_ EHC25_MODFunction_Set : 43|2@0+ (1,0) [0|3] "" IDC,Delete_APA
 SG_ EHC25_Set_Color : 46|3@0+ (1,0) [0|7] "" IDC,Delete_APA

BO_ 444 CDC_0x1BC: 8 CGW
 SG_ ICC_N_SlotAngle : 7|12@0+ (0.1,-180) [-180|180] "degree" IDC,Delete_APA
 SG_ ICC_N_CoorA_X : 10|11@0+ (1,0) [0|1920] "pixel" IDC,Delete_APA
 SG_ ICC_ATSMode : 36|2@0+ (1,0) [0|3] "" IDC,Delete_APA
 SG_ ICC_N_CoorA_Y : 31|11@0+ (1,0) [0|1080] "pixel" IDC,Delete_APA
 SG_ ICC_ScrnAngle : 32|9@0+ (1,0) [0|511] "" IDC,Delete_APA
 SG_ ICCAdasApaSocOffSwt : 34|2@0+ (1,0) [0|3] "" IDC
 SG_ ICC_AvapViewSource : 58|3@0+ (1,0) [0|7] "" IDC
 SG_ ICC_AvapSysSts : 61|3@0+ (1,0) [0|7] "" IDC
 SG_ ICCAvmCalibrationParameter : 11|1@0+ (1,0) [0|1] "" IDC
 SG_ ICCApaCalibrationReq : 63|2@0+ (1,0) [0|3] "" IDC

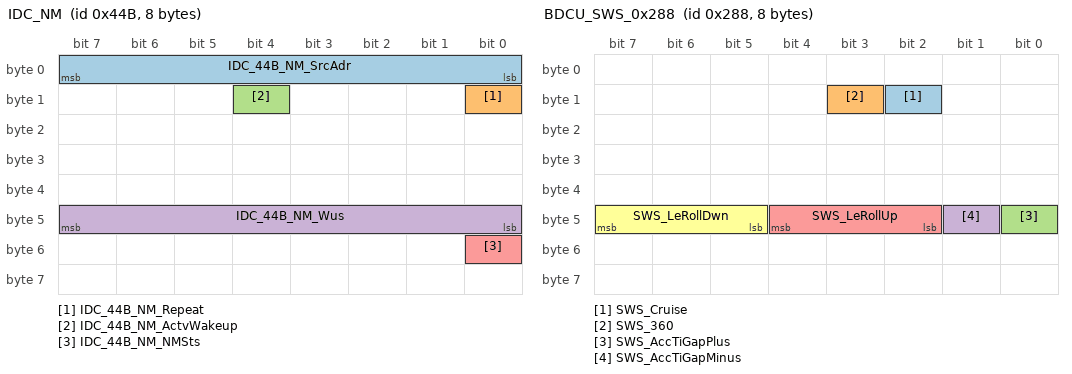
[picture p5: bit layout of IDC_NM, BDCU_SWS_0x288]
BO_ 1099 IDC_NM: 8 IDC
 SG_ IDC_44B_NM_SrcAdr : 7|8@0+ (1,0) [0|127] "" Vector__XXX
 SG_ IDC_44B_NM_Repeat : 8|1@0+ (1,0) [0|1] "" Vector__XXX
 SG_ IDC_44B_NM_ActvWakeup : 12|1@0+ (1,0) [0|1] "" Vector__XXX
 SG_ IDC_44B_NM_Wus : 47|8@0+ (1,0) [0|255] "" Vector__XXX
 SG_ IDC_44B_NM_NMSts : 48|1@0+ (1,0) [0|1] "" Vector__XXX

BO_ 1804 DLC_IDC_Req: 64 CGW

BO_ 1932 IDC_DLC_Res: 64 IDC

BO_ 648 BDCU_SWS_0x288: 8 CGW
 SG_ SWS_Cruise : 10|1@0+ (1,0) [0|1] "" IDC
 SG_ SWS_360 : 11|1@0+ (1,0) [0|1] "" IDC
 SG_ SWS_AccTiGapPlus : 40|1@0+ (1,0) [0|1] "" IDC
 SG_ SWS_AccTiGapMinus : 41|1@0+ (1,0) [0|1] "" IDC
 SG_ SWS_LeRollUp : 44|3@0+ (1,0) [0|7] "" IDC
 SG_ SWS_LeRollDwn : 47|3@0+ (1,0) [0|7] "" IDC

BO_ 309 ADC_APA_0x135: 24 IDC
 SG_ ADC_APA1Chks : 7|8@0+ (1,0) [0|255] "" CGW
 SG_ ADC_APA1Cntr : 11|4@0+ (1,0) [0|14] "" CGW
 SG_ APA_FuncMode : 18|3@0+ (1,0) [0|7] "" CGW
 SG_ APA_TqReqFlg : 19|1@0+ (1,0) [0|1] "" CGW
 SG_ APA_LgtMtnCtrReq : 21|2@0+ (1,0) [0|3] "" CGW
 SG_ APA_TqReqVld : 22|1@0+ (1,0) [0|1] "" CGW
 SG_ APA_RdyReqVld : 23|1@0+ (1,0) [0|1] "" CGW
 SG_ APA_TqReq : 31|16@0+ (1,-32768) [-32768|32767] "Nm" CGW
 SG_ APA_RdyReq : 41|2@0+ (1,0) [0|3] "" CGW
 SG_ APA_GearCtrlEnable : 43|2@0+ (1,0) [0|3] "" CGW
 SG_ APA_TarGearReq : 46|3@0+ (1,0) [0|7] "" CGW
 SG_ APA_TarGearReqVld : 47|1@0+ (1,0) [0|1] "" CGW
 SG_ APA_AxReqEnable : 54|1@0+ (1,0) [0|1] "" CGW
 SG_ APA_AxReqVld : 55|1@0+ (1,0) [0|1] "" CGW
 SG_ APA_AxReq : 53|14@0+ (0.001,-10) [-10|6] "m/s2" CGW
 SG_ ADC_APA2Chks : 71|8@0+ (1,0) [0|255] "" CGW
 SG_ ADC_APA2Cntr : 75|4@0+ (1,0) [0|14] "" CGW
 SG_ APA_SysFailSts : 80|1@0+ (1,0) [0|1] "" CGW
 SG_ APA_DrvOffReq : 81|1@0+ (1,0) [0|1] "" CGW
 SG_ APA_VehStandstillReq : 82|1@0+ (1,0) [0|1] "" CGW
 SG_ APA_CtrlEPBAux : 83|1@0+ (1,0) [0|1] "" CGW
 SG_ APA_ControlEPB : 85|2@0+ (1,0) [0|3] "" CGW
 SG_ APA_MEBTarAReq : 86|1@0+ (1,0) [0|1] "" CGW
 SG_ APA_MEBTarAVld : 87|1@0+ (1,0) [0|1] "" CGW
 SG_ APA_MEBTarA : 95|16@0+ (0.0004882,-16) [-16|15.994187] "m/s2" CGW
 SG_ APA_PreFillReq : 104|1@0+ (1,0) [0|1] "" CGW
 SG_ APA_FuncMode_EPS : 107|3@0+ (1,0) [0|7] "" CGW
 SG_ APA_BrkReqType : 109|2@0+ (1,0) [0|3] "" CGW
 SG_ APA_StrWhlAgReqActv : 111|2@0+ (1,0) [0|3] "" CGW
 SG_ APA_DstToStop : 119|16@0+ (1,0) [0|65535] "cm" CGW
 SG_ ADC_APA3Chks : 135|8@0+ (1,0) [0|255] "" CGW
 SG_ ADC_APA3Cntr : 139|4@0+ (1,0) [0|14] "" CGW
 SG_ APA_StrWhlAgReq : 151|16@0+ (0.0625,-780) [-780|780] "" CGW
 SG_ APA_StrWhlAgReqVld : 161|2@0+ (1,0) [0|3] "" CGW
 SG_ APA_ControlEPBVld : 162|1@0+ (1,0) [0|1] "" CGW

BO_ 310 ADC_ADAS_0x136: 32 IDC
 SG_ ADC_ADAS1Chks : 7|8@0+ (1,0) [0|255] "" CGW
 SG_ ADC_ADAS1Cntr : 11|4@0+ (1,0) [0|14] "" CGW
 SG_ ADAS_LgtMtnCtrReq : 17|2@0+ (1,0) [0|3] "" CGW
 SG_ ADAS_LgtReqMode : 19|2@0+ (1,0) [0|3] "" CGW
 SG_ ADAS_TarTqReqEna : 20|1@0+ (1,0) [0|1] "" CGW
 SG_ ADAS_TarTqReqVld : 21|1@0+ (1,0) [0|1] "" CGW
 SG_ ADAS_AMAPRequest : 22|1@0+ (1,0) [0|1] "" CGW
 SG_ ADAS_AMAPRequestvld : 23|1@0+ (1,0) [0|1] "" CGW
 SG_ ADAS_TarTqReq : 31|16@0+ (1,-32768) [-32768|32767] "Nm" CGW
 SG_ ADAS_GearCtrEnable : 41|2@0+ (1,0) [0|3] "" CGW
 SG_ ADAS_TarGearReqVld : 42|1@0+ (1,0) [0|1] "" CGW
 SG_ ADAS_SysFailSts : 43|1@0+ (1,0) [0|1] "" CGW
 SG_ ADAS_TarGearReq : 46|3@0+ (1,0) [0|7] "" CGW
 SG_ ADAS_TarAxReqEna : 47|1@0+ (1,0) [0|1] "" CGW
 SG_ ADAS_TarAxReqVld : 54|1@0+ (1,0) [0|1] "" CGW
 SG_ ADAS_DrvOffReq : 55|1@0+ (1,0) [0|1] "" CGW
 SG_ ADAS_TarAxReq : 53|14@0+ (0.001,-10) [-10|6] "m/s2" CGW
 SG_ ADC_ADAS2Chks : 71|8@0+ (1,0) [0|255] "" CGW
 SG_ ADC_ADAS2Cntr : 75|4@0+ (1,0) [0|14] "" CGW
 SG_ ADAS_DecelToStopReq : 87|1@0+ (1,0) [0|1] "" CGW
 SG_ ADAS_TarAxUpperjerkLim : 86|7@0+ (0.1,0) [0|12.7] "m/s3" CGW
 SG_ ADAS_TarAxLowerjerkLim : 94|7@0+ (0.1,-12.7) [-12.7|0] "m/s3" CGW
 SG_ ADAS_Req_Prefill : 95|1@0+ (1,0) [0|1] "" CGW
 SG_ ADAS_Req_ABA : 96|1@0+ (1,0) [0|1] "" CGW
 SG_ ADAS_Lvl_ABA : 98|2@0+ (1,0) [0|3] "" CGW
 SG_ ADAS_Req_AWB : 99|1@0+ (1,0) [0|1] "" CGW
 SG_ ADAS_Lvl_AWB : 102|3@0+ (1,0) [0|7] "" CGW
 SG_ ADAS_TarAReq_AEB : 103|1@0+ (1,0) [0|1] "" CGW
 SG_ ADAS_Decel_AEB : 111|16@0+ (0.0004882,-16) [-16|15.994187] "m/s2" CGW
 SG_ ADAS_DecelTyp_AEB : 123|4@0+ (1,0) [0|15] "" CGW
 SG_ ADAS_DecelVld_AEB : 124|1@0+ (1,0) [0|1] "" CGW
 SG_ ADAS_Req_EPB : 126|2@0+ (1,0) [0|3] "" CGW
 SG_ ADAS_LatMtnCtrlSts : 127|1@0+ (1,0) [0|1] "" CGW
 SG_ ADC_ADAS3Chks : 135|8@0+ (1,0) [0|255] "" CGW
 SG_ ADC_ADAS3Cntr : 139|4@0+ (1,0) [0|14] "" CGW
 SG_ ADAS_LatFuncMode : 145|2@0+ (1,0) [0|3] "" CGW
 SG_ ADAS_PinionAgReqVld : 147|2@0+ (1,0) [0|3] "" CGW
 SG_ ADAS_PinionAgReq : 159|16@0+ (0.0625,-780) [-780|780] "°" CGW
 SG_ ADAS_SteerAgDrvk : 174|7@0+ (0.015,0) [0|0.015] "比例" CGW
 SG_ ADAS_ExtMaxRPCTrq : 178|11@0+ (0.01,-10.24) [-10.24|10.23] "Nm" CGW
 SG_ ADC_ADAS4Chks : 199|8@0+ (1,0) [0|255] "" CGW
 SG_ ADC_ADAS4Cntr : 203|4@0+ (1,0) [0|14] "" CGW
 SG_ ADAS_ExtMinRPCTrq : 210|11@0+ (0.01,-10.24) [-10.24|10.23] "Nm" CGW
 SG_ ADAS_Req_EPBVld : 211|1@0+ (1,0) [0|1] "" CGW
 SG_ ADS_DrvTarTq_J6 : 247|16@0+ (1,-32768) [-32768|32767] "Nm" CGW
 SG_ ADS_SteerAgCtrlEnaReq_J6 : 15|2@0+ (1,0) [0|3] "" CGW

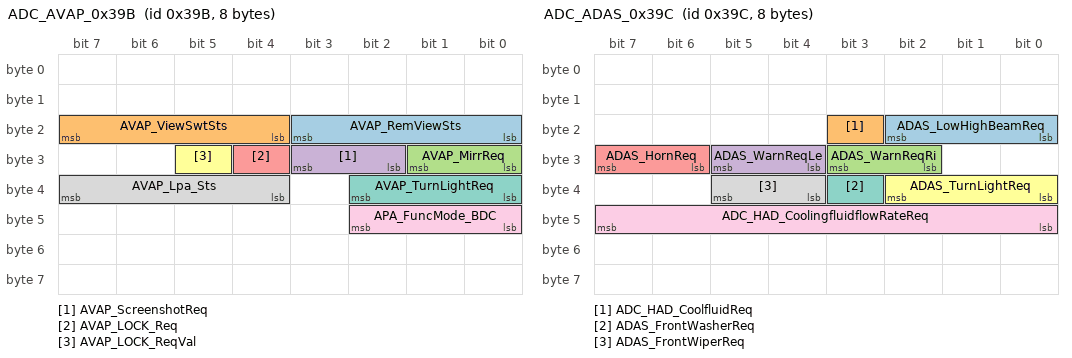
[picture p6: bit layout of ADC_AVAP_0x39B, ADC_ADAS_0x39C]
BO_ 923 ADC_AVAP_0x39B: 8 IDC
 SG_ AVAP_RemViewSts : 19|4@0+ (1,0) [0|15] "" CGW
 SG_ AVAP_ViewSwtSts : 23|4@0+ (1,0) [0|15] "" CGW
 SG_ AVAP_MirrReq : 25|2@0+ (1,0) [0|3] "" CGW
 SG_ AVAP_ScreenshotReq : 27|2@0+ (1,0) [0|3] "" CGW
 SG_ AVAP_LOCK_Req : 28|1@0+ (1,0) [0|1] "" CGW
 SG_ AVAP_LOCK_ReqVal : 29|1@0+ (1,0) [0|1] "" CGW
 SG_ AVAP_TurnLightReq : 34|3@0+ (1,0) [0|7] "" CGW
 SG_ AVAP_Lpa_Sts : 39|4@0+ (1,0) [0|15] "" CGW
 SG_ APA_FuncMode_BDC : 42|3@0+ (1,0) [0|7] "" CGW

BO_ 924 ADC_ADAS_0x39C: 8 IDC
 SG_ ADAS_LowHighBeamReq : 18|3@0+ (1,0) [0|7] "" CGW
 SG_ ADC_HAD_CoolfluidReq : 19|1@0+ (1,0) [0|1] "" CGW
 SG_ ADAS_WarnReqRi : 27|2@0+ (1,0) [0|3] "" CGW
 SG_ ADAS_WarnReqLe : 29|2@0+ (1,0) [0|3] "" CGW
 SG_ ADAS_HornReq : 31|2@0+ (1,0) [0|1] "" CGW
 SG_ ADAS_TurnLightReq : 34|3@0+ (1,0) [0|7] "" CGW
 SG_ ADAS_FrontWasherReq : 35|1@0+ (1,0) [0|1] "" CGW
 SG_ ADAS_FrontWiperReq : 37|2@0+ (1,0) [0|3] "" CGW
 SG_ ADC_HAD_CoolingfluidflowRateReq : 47|8@0+ (1,0) [0|15] "" CGW

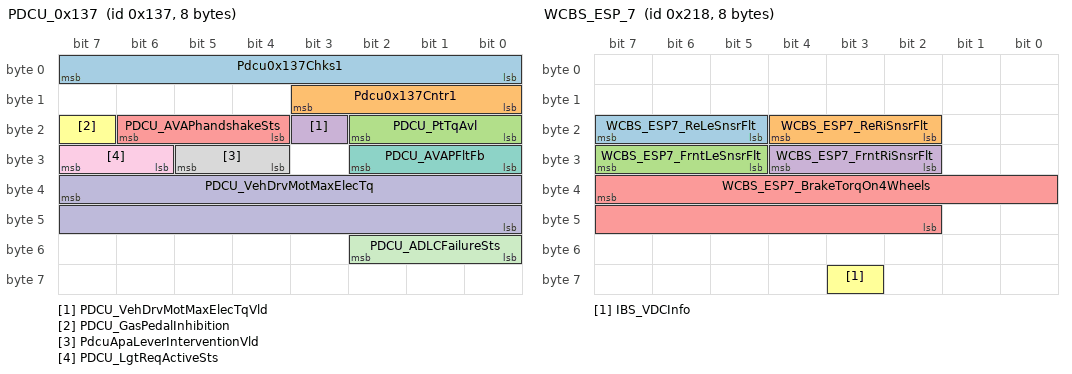
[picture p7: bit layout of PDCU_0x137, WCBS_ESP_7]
BO_ 311 PDCU_0x137: 8 CGW
 SG_ Pdcu0x137Chks1 : 7|8@0+ (1,0) [0|255] "" IDC
 SG_ Pdcu0x137Cntr1 : 11|4@0+ (1,0) [0|14] "" IDC
 SG_ PDCU_PtTqAvl : 18|3@0+ (1,0) [0|7] "" IDC
 SG_ PDCU_VehDrvMotMaxElecTqVld : 19|1@0+ (1,0) [0|1] "" IDC
 SG_ PDCU_AVAPhandshakeSts : 22|3@0+ (1,0) [0|7] "" IDC
 SG_ PDCU_GasPedalInhibition : 23|1@0+ (1,0) [0|1] "" IDC
 SG_ PDCU_AVAPFltFb : 26|3@0+ (1,0) [0|7] "" IDC
 SG_ PdcuApaLeverInterventionVld : 29|2@0+ (1,0) [0|3] "" IDC
 SG_ PDCU_LgtReqActiveSts : 31|2@0+ (1,0) [0|3] "" IDC
 SG_ PDCU_VehDrvMotMaxElecTq : 39|16@0+ (1,-32768) [-32768|32767] "Nm" IDC
 SG_ PDCU_ADLCFailureSts : 50|3@0+ (1,0) [0|7] "" IDC

BO_ 833 WCBS_EV: 8 CGW
 SG_ WCBS_N_EBRTrqACT : 55|13@0+ (1,0) [0|6000] "Nm" IDC

BO_ 536 WCBS_ESP_7: 8 CGW
 SG_ WCBS_ESP7_ReLeSnsrFlt : 23|3@0+ (1,0) [0|7] "" IDC
 SG_ WCBS_ESP7_ReRiSnsrFlt : 20|3@0+ (1,0) [0|7] "" IDC
 SG_ WCBS_ESP7_FrntLeSnsrFlt : 31|3@0+ (1,0) [0|7] "" IDC
 SG_ WCBS_ESP7_FrntRiSnsrFlt : 28|3@0+ (1,0) [0|7] "" IDC
 SG_ WCBS_ESP7_BrakeTorqOn4Wheels : 39|14@0+ (2,0) [0|15000] "Nm" IDC
 SG_ IBS_VDCInfo : 59|1@0+ (1,0) [0|1] "" IDC

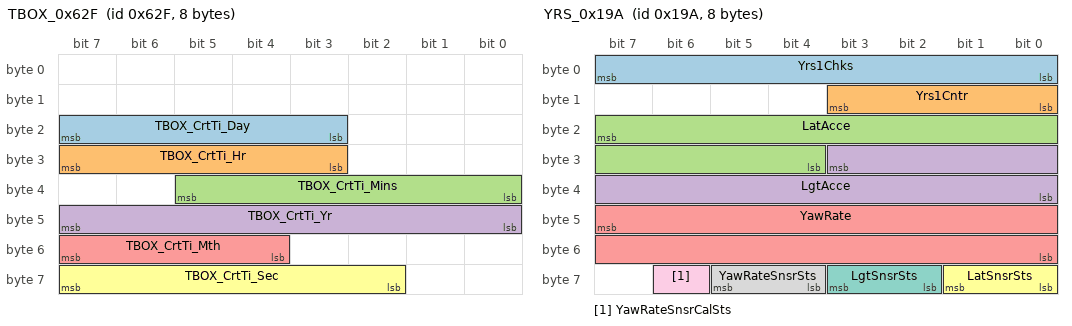
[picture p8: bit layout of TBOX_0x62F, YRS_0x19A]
BO_ 1583 TBOX_0x62F: 8 CGW
 SG_ TBOX_CrtTi_Day : 23|5@0+ (1,1) [1|31] "day" IDC
 SG_ TBOX_CrtTi_Hr : 31|5@0+ (1,0) [0|23] "hour" IDC
 SG_ TBOX_CrtTi_Mins : 37|6@0+ (1,0) [0|59] "mintue" IDC
 SG_ TBOX_CrtTi_Yr : 47|8@0+ (1,2015) [2015|2270] "year" IDC
 SG_ TBOX_CrtTi_Mth : 55|4@0+ (1,1) [1|12] "month" IDC
 SG_ TBOX_CrtTi_Sec : 63|6@0+ (1,0) [0|59] "second" IDC

BO_ 315 EPS_0x13B: 16 CGW
 SG_ EPS_SteerTorqueByADASReq : 23|11@0+ (0.01,-10.24) [-10.24|10.23] "Nm" IDC
 SG_ EPS_SteerTorqueVldByADASReq : 15|1@0+ (1,0) [0|1] "" IDC
 SG_ EPS_SteerSnsrSts : 14|1@0+ (1,0) [0|1] "" IDC
 SG_ EPS_DrvrSteerTqDir : 13|1@0+ (1,0) [0|1] "" IDC
 SG_ EPS_SteerDrvrOvrd_J6 : 12|1@0+ (1,0) [0|1] "" IDC

BO_ 410 YRS_0x19A: 8 CGW
 SG_ Yrs1Chks : 7|8@0+ (1,0) [0|255] "" IDC
 SG_ Yrs1Cntr : 11|4@0+ (1,0) [0|14] "" IDC
 SG_ LatAcce : 23|12@0+ (0.001,-2) [-2|2] "g" IDC
 SG_ LgtAcce : 27|12@0+ (0.001,-2) [-2|2] "g" IDC
 SG_ YawRate : 47|16@0+ (0.01,-180) [-180|180] "°/s" IDC
 SG_ LatSnsrSts : 57|2@0+ (1,0) [0|3] "" IDC
 SG_ LgtSnsrSts : 59|2@0+ (1,0) [0|3] "" IDC
 SG_ YawRateSnsrSts : 61|2@0+ (1,0) [0|3] "" IDC
 SG_ YawRateSnsrCalSts : 62|1@0+ (1,0) [0|1] "" IDC

BO_ 908 IDC_0x38C: 64 IDC
 SG_ IDC0x38C1Chks : 7|8@0+ (1,0) [0|255] "" CGW
 SG_ IDC0x38C1Cntr : 11|4@0+ (1,0) [0|14] "" CGW
 SG_ LeftFrontUssSts : 17|2@0+ (1,0) [0|3] "" CGW
 SG_ FrontLeftUssSts : 19|2@0+ (1,0) [0|3] "" CGW
 SG_ FrontLeftCenterUssSts : 21|2@0+ (1,0) [0|3] "" CGW
 SG_ FrontRightCenterUssSts : 23|2@0+ (1,0) [0|3] "" CGW
 SG_ FrontRightUssSts : 25|2@0+ (1,0) [0|3] "" CGW
 SG_ RightFrontUssSts : 27|2@0+ (1,0) [0|3] "" CGW
 SG_ LeftBackUssSts : 29|2@0+ (1,0) [0|3] "" CGW
 SG_ BackLeftUssSts : 31|2@0+ (1,0) [0|3] "" CGW
 SG_ BackLeftCenterUssSts : 33|2@0+ (1,0) [0|3] "" CGW
 SG_ BackRightCenterUssSts : 35|2@0+ (1,0) [0|3] "" CGW
 SG_ BackRightUssSts : 37|2@0+ (1,0) [0|3] "" CGW
 SG_ RightBacktUssSts : 39|2@0+ (1,0) [0|3] "" CGW
 SG_ IDC0x38C2Chks : 71|8@0+ (1,0) [0|255] "" CGW
 SG_ IDC0x38C2Cntr : 75|4@0+ (1,0) [0|14] "" CGW
 SG_ PAS_FL_Distance : 87|3@0+ (1,0) [0|7] "" CGW
 SG_ PAS_FML_Distance : 84|3@0+ (1,0) [0|7] "" CGW
 SG_ PAS_FMR_Distance : 81|3@0+ (1,0) [0|7] "" CGW
 SG_ PAS_FR_Distance : 94|3@0+ (1,0) [0|7] "" CGW
 SG_ SDW_LSF1_Distance : 91|3@0+ (1,0) [0|7] "" CGW
 SG_ SDW_LSF2_Distance : 88|3@0+ (1,0) [0|7] "" CGW
 SG_ SDW_LSR2_Distance : 101|3@0+ (1,0) [0|7] "" CGW
 SG_ SDW_LSR1_Distance : 98|3@0+ (1,0) [0|7] "" CGW
 SG_ SDW_RSF1_Distance : 111|3@0+ (1,0) [0|7] "" CGW
 SG_ SDW_RSF2_Distance : 108|3@0+ (1,0) [0|7] "" CGW
 SG_ SDW_RSR2_Distance : 105|3@0+ (1,0) [0|7] "" CGW
 SG_ SDW_RSR1_Distance : 118|3@0+ (1,0) [0|7] "" CGW
 SG_ PAS_RL_Distance : 115|3@0+ (1,0) [0|7] "" CGW
 SG_ PAS_RML_Distance : 112|3@0+ (1,0) [0|7] "" CGW
 SG_ PAS_RMR_Distance : 125|3@0+ (1,0) [0|7] "" CGW
 SG_ PAS_RR_Distance : 122|3@0+ (1,0) [0|7] "" CGW
 SG_ IDC0x38C3Chks : 135|8@0+ (1,0) [0|255] "" CGW
 SG_ IDC0x38C3Cntr : 139|4@0+ (1,0) [0|14] "" CGW
 SG_ ApaCalibrationParameter : 143|1@0+ (1,0) [0|1] "" CGW
 SG_ ApaFactoryCalibrationSts : 151|2@0+ (1,0) [0|3] "" CGW
 SG_ ApaFactoryCalibFailureRsn : 159|8@0+ (1,0) [0|255] "" CGW
 SG_ ApaAfterSalesCalibrationSts : 142|2@0+ (1,0) [0|3] "" CGW
 SG_ ApaAfterSalesCalibStsProgress : 175|7@0+ (1,0) [0|100] "%" CGW
 SG_ ApaAfterSalesCalibFailureRsn : 167|8@0+ (1,0) [0|255] "" CGW

BO_TX_BU_ 659 : IDC,Delete_APA;

BO_TX_BU_ 660 : IDC,Delete_APA;

BO_TX_BU_ 920 : IDC,Delete_APA;

BO_TX_BU_ 921 : IDC,Delete_APA;

BO_TX_BU_ 1517 : IDC,Delete_APA;

BO_TX_BU_ 661 : IDC,Delete_APA;
CM_ BO_ 659 "与车机交互有关";
CM_ BO_ 920 "AVM相关，转到TCANFD是1000ms";
CM_ BO_ 921 "与车机交互有关";
CM_ BO_ 442 "转到TCANFD是1000ms";
CM_ BO_ 822 "蓝牙控制及远程启动";
CM_ BO_ 823 "蓝牙车辆模式及系统状态";
CM_ BO_ 225 "借用41,转到TCANFD是1000ms";
CM_ BO_ 237 "采用41";
CM_ BO_ 1099 "AUTOSAR NM（CAN2.0格式）";
CM_ BO_ 1804 "矩阵中诊断报文的DLC仅用于适配DBC文件的生成，ECU实际开发采用的DLC长度应满足UDS技术要求";
CM_ BO_ 1932 "矩阵中诊断报文的DLC仅用于适配DBC文件的生成，ECU实际开发采用的DLC长度应满足UDS技术要求";
CM_ BO_ 648 "B60VS-F03新增ID";
CM_ BO_ 309 "B81VS的J6B借用B41VS的J6M";
CM_ BO_ 310 "B81VS的J6B借用B41VS的J6M";
CM_ BO_ 923 "B81VS的J6B借用B41VS的J6M";
CM_ BO_ 924 "B81VS的J6B借用B41VS的J6M";
CM_ BO_ 311 "B81VS的J6B借用B41VS的J6M";
CM_ BO_ 536 "内含5个F03的华为智驾信号";
CM_ BO_ 315 "B81VS新增ID";
CM_ BO_ 410 "B60VS-F03新增ID";
CM_ BO_ 908 "B81VS新增ID，J6B-APA";
CM_ SG_ 659 APASlot_1_source "车位来源";
CM_ SG_ 659 APASlot__1_Direction "车位方向";
CM_ SG_ 659 APASlot_2_source "车位来源";
CM_ SG_ 659 APASlot_3_source "车位来源";
CM_ SG_ 659 APASlot__2_Direction "车位方向";
CM_ SG_ 659 APASlot_4_source "车位来源";
CM_ SG_ 659 APASlot_5_source "车位来源";
CM_ SG_ 659 APASlot__3_Direction "车位方向";
CM_ SG_ 659 APASlot_6_source "车位来源";
CM_ SG_ 659 APASlot_7_source "车位来源";
CM_ SG_ 659 APASlot__4_Direction "车位方向";
CM_ SG_ 659 APASlot_8_source "车位来源";
CM_ SG_ 659 APASlot_9_source "车位来源";
CM_ SG_ 659 APASlot__5_Direction "车位方向";
CM_ SG_ 659 APASlot_10_source "车位来源";
CM_ SG_ 659 APASlot_11_source "车位来源";
CM_ SG_ 659 APASlot__6_Direction "车位方向";
CM_ SG_ 659 APASlot_12_source "车位来源";
CM_ SG_ 659 APASlot__7_Direction "车位方向";
CM_ SG_ 659 APASlot__8_Direction "车位方向";
CM_ SG_ 659 APASlot__9_Direction "车位方向";
CM_ SG_ 659 APASlot__10_Direction "车位方向";
CM_ SG_ 659 APASlot__11_Direction "车位方向";
CM_ SG_ 659 APASlot__12_Direction "车位方向";
CM_ SG_ 659 APASlot__13_Direction "车位方向";
CM_ SG_ 659 APASlot__14_Direction "车位方向";
CM_ SG_ 659 APASlot__1_Type "车位类型";
CM_ SG_ 659 APASlot__2_Type "车位类型";
CM_ SG_ 659 APASlot__3_Type "车位类型";
CM_ SG_ 659 APASlot__4_Type "车位类型";
CM_ SG_ 659 APASlot__5_Type "车位类型";
CM_ SG_ 659 APASlot__6_Type "车位类型";
CM_ SG_ 659 APASlot__7_Type "车位类型";
CM_ SG_ 659 APASlot__8_Type "车位类型";
CM_ SG_ 659 APASlot__9_Type "车位类型";
CM_ SG_ 659 APASlot__10_Type "车位类型";
CM_ SG_ 659 APASlot__11_Type "车位类型";
CM_ SG_ 659 APASlot__12_Type "车位类型";
CM_ SG_ 659 SlotTarg_ID "目标车位ID（1-255）";
CM_ SG_ 659 Slot1_ID "车位1的车位ID（1-255）";
CM_ SG_ 659 Slot2_ID "车位2的车位ID（1-255）";
CM_ SG_ 659 Slot3_ID "车位3的车位ID（1-255）";
CM_ SG_ 659 Slot4_ID "车位4的车位ID（1-255）";
CM_ SG_ 659 Slot5_ID "车位5的车位ID（1-255）";
CM_ SG_ 659 Slot6_ID "车位6的车位ID（1-255）";
CM_ SG_ 659 Slot7_ID "车位7的车位ID（1-255）";
CM_ SG_ 659 Slot8_ID "车位8的车位ID（1-255）";
CM_ SG_ 659 Slot9_ID "车位9的车位ID（1-255）";
CM_ SG_ 659 Slot10_ID "车位10的车位ID（1-255）";
CM_ SG_ 659 Slot11_ID "车位11的车位ID（1-255）";
CM_ SG_ 659 Slot12_ID "车位12的车位ID（1-255）";
CM_ SG_ 920 AVM3_St_BuzzerAlarmPattern "蜂鸣器报警方式";
CM_ SG_ 920 AvmDispReq "Indicate the current display requirement of AVM";
CM_ SG_ 920 ObstclViewSts "Obstacle view set request signal.障碍物显示开关的反馈状态。";
CM_ SG_ 920 AvmTrigByObstclSts "'AVM trigger by PAS Obstacle' set request signal雷达障碍物触发全景显示的设置状态反馈";
CM_ SG_ 920 OvlDispSts "Indicate the status of overlay。";
CM_ SG_ 920 AvmViewModSts "The AVM 2D/3D view sts。";
CM_ SG_ 920 AvmViewMod "The view state of AVM mode.通过车机坐标识别。";
CM_ SG_ 920 AvmChasLctSts "AVM 底盘透明设置Lucent反馈";
CM_ SG_ 920 AvmRoadCalSts "全景道路标定信号Avm Road Calibration Switch反馈状态";
CM_ SG_ 920 AvmRoadCalProgsSts "全景道路标定过程反馈Avm Road Calibration progress status";
CM_ SG_ 920 EolCalSts "Indicate the status of calibration.";
CM_ SG_ 920 ApaSentiWarningMsg "APA哨兵监控状态";
CM_ SG_ 920 ApaSentiModSts "APA哨兵模式状态";
CM_ SG_ 921 PasSysSts "Parking Assistantce  System Status控制器系统状态，包含主控制器，前雷达传感器，后雷达传感器，若存在主控制器与传感器同时故障的情况，均发0x1：Pas System Error";
CM_ SG_ 921 PasLoSpdAutoSts "Reserved. PAS low speed auto off/on SW status";
CM_ SG_ 921 PasSwSts "Indicate the PAS SW status";
CM_ SG_ 921 PasReMLeRegnObjSts "Parking Assistantce Rear Middle Left Region Object Status";
CM_ SG_ 921 PasReLeRegnObjSts "Parking Assistantce Rear Left Region Object Status";
CM_ SG_ 921 PasFrntLeRegnObjSts "Parking Assistantce Front Left Region Object Status";
CM_ SG_ 921 PasReRiRegnObjSts "Parking Assistantce Rear Right Region Object Status";
CM_ SG_ 921 PasFrntRiRegnObjSts "Parking Assistantce Front Right Region Object Status";
CM_ SG_ 921 PasFrntMLeRegnObjSts "Parking Assistantce Front Middle Left Region Object Status";
CM_ SG_ 921 ReMinPasDst "The mimimum distance measured between all rear sensors. Could be use for ICM Tone stimulation";
CM_ SG_ 921 FrntMinPasDst " The mimimum distance measured between all front sensors. Could be used for ICM Tone stimulation";
CM_ SG_ 921 PasReMRiRegnObjSts "Parking Assistantce Rear Middle Right Region Object Status";
CM_ SG_ 921 PasHumResp "The response of pas from HUM setting about front radar.";
CM_ SG_ 921 PasFrntMRiRegnObjSts "Reserved. Parking Assistantce Front Middle Right Region Object Status";
CM_ SG_ 1517 DtcHighByte "DTC高字节";
CM_ SG_ 1517 DtcMiddleByte "DTC中字节";
CM_ SG_ 1517 DctLowByte "DTC低字节";
CM_ SG_ 1517 DtcStatus "DTC状态";
CM_ SG_ 661 HPA_ObjLatDst1 "障碍物1的横向距离";
CM_ SG_ 661 HPA_ObjLgtDst1 "障碍物1的纵向距离";
CM_ SG_ 661 HPA_ObjTyp1 "记忆泊车中障碍物车辆类型";
CM_ SG_ 661 HPA_ObjMovmtDir1 "障碍物1方向";
CM_ SG_ 661 HPA_ObjPosnAgl1 "障碍物1的角度";
CM_ SG_ 661 HPA_ObjLatDst2 "障碍物2的横向距离";
CM_ SG_ 661 HPA_ObjLgtDst2 "障碍物2的纵向距离";
CM_ SG_ 661 HPA_ObjTyp2 "记忆泊车中障碍物车辆类型";
CM_ SG_ 661 HPA_ObjMovmtDir2 "障碍物2方向";
CM_ SG_ 661 HPA_ObjPosnAgl2 "障碍物2的角度";
CM_ SG_ 661 HPA_ObjLatDst3 "障碍物3的横向距离";
CM_ SG_ 661 HPA_ObjLgtDst3 "障碍物3的纵向距离";
CM_ SG_ 661 HPA_ObjTyp3 "记忆泊车中障碍物车辆类型";
CM_ SG_ 661 HPA_ObjMovmtDir3 "障碍物3方向";
CM_ SG_ 661 HPA_ObjPosnAgl3 "障碍物3的角度";
CM_ SG_ 661 HPA_ObjLatDst4 "障碍物4的横向距离";
CM_ SG_ 661 HPA_ObjLgtDst4 "障碍物4的纵向距离";
CM_ SG_ 661 HPA_ObjTyp4 "记忆泊车中障碍物车辆类型";
CM_ SG_ 661 HPA_ObjMovmtDir4 "障碍物4方向";
CM_ SG_ 661 HPA_ObjPosnAgl4 "障碍物4的角度";
CM_ SG_ 661 HPA_ObjLatDst5 "障碍物5的横向距离";
CM_ SG_ 661 HPA_ObjLgtDst5 "障碍物5的纵向距离";
CM_ SG_ 661 HPA_ObjTyp5 "记忆泊车中障碍物车辆类型";
CM_ SG_ 661 HPA_ObjMovmtDir5 "障碍物5方向";
CM_ SG_ 661 HPA_ObjPosnAgl5 "障碍物5的角度";
CM_ SG_ 661 HPA_ObjLatDst6 "障碍物6的横向距离";
CM_ SG_ 661 HPA_ObjLgtDst6 "障碍物6的纵向距离";
CM_ SG_ 661 HPA_ObjTyp6 "记忆泊车中障碍物车辆类型";
CM_ SG_ 661 HPA_ObjMovmtDir6 "障碍物6方向";
CM_ SG_ 661 HPA_ObjPosnAgl6 "障碍物6的角度";
CM_ SG_ 661 HPA_ObjLatDst7 "障碍物7的横向距离";
CM_ SG_ 661 HPA_ObjLgtDst7 "障碍物7的纵向距离";
CM_ SG_ 661 HPA_ObjTyp7 "记忆泊车中障碍物车辆类型";
CM_ SG_ 661 HPA_ObjMovmtDir7 "障碍物7方向";
CM_ SG_ 661 HPA_ObjPosnAgl7 "障碍物7的角度";
CM_ SG_ 661 HPA_ObjLatDst8 "障碍物8的横向距离";
CM_ SG_ 661 HPA_ObjLgtDst8 "障碍物8的纵向距离";
CM_ SG_ 661 HPA_ObjTyp8 "记忆泊车中障碍物车辆类型";
CM_ SG_ 661 HPA_ObjMovmtDir8 "障碍物8方向";
CM_ SG_ 661 HPA_ObjPosnAgl8 "障碍物8的角度";
CM_ SG_ 661 HPA_ObjLatDst9 "障碍物9的横向距离";
CM_ SG_ 661 HPA_ObjLgtDst9 "障碍物9的纵向距离";
CM_ SG_ 661 HPA_ObjTyp9 "记忆泊车中障碍物车辆类型";
CM_ SG_ 661 HPA_ObjMovmtDir9 "障碍物9方向";
CM_ SG_ 661 HPA_ObjPosnAgl9 "障碍物9的角度";
CM_ SG_ 661 HPA_ObjLatDst10 "障碍物10的横向距离";
CM_ SG_ 661 HPA_ObjLgtDst10 "障碍物10的纵向距离";
CM_ SG_ 661 HPA_ObjTyp10 "记忆泊车中障碍物车辆类型";
CM_ SG_ 661 HPA_ObjMovmtDir10 "障碍物10方向";
CM_ SG_ 661 HPA_ObjPosnAgl10 "障碍物10的角度";
CM_ SG_ 661 HPA_ObjLatDst11 "障碍物11的横向距离";
CM_ SG_ 661 HPA_ObjLgtDst11 "障碍物11的纵向距离";
CM_ SG_ 661 HPA_ObjTyp11 "记忆泊车中障碍物车辆类型";
CM_ SG_ 661 HPA_ObjMovmtDir11 "障碍物11方向";
CM_ SG_ 661 HPA_ObjPosnAgl11 "障碍物11的角度";
CM_ SG_ 661 HPA_ObjLatDst12 "障碍物12的横向距离";
CM_ SG_ 661 HPA_ObjLgtDst12 "障碍物12的纵向距离";
CM_ SG_ 661 HPA_ObjTyp12 "记忆泊车中障碍物车辆类型";
CM_ SG_ 661 HPA_ObjMovmtDir12 "障碍物12方向";
CM_ SG_ 661 HPA_ObjPosnAgl12 "障碍物12的角度";
CM_ SG_ 661 PasMinObjSts "障碍物距离显示";
CM_ SG_ 661 ApaSlot1_Sts "车位1可用状态";
CM_ SG_ 661 ApaSlot2_Sts "车位2可用状态";
CM_ SG_ 661 ApaSlot3_Sts "车位3可用状态";
CM_ SG_ 661 ApaSlot4_Sts "车位4可用状态";
CM_ SG_ 661 ApaSlot5_Sts "车位5可用状态";
CM_ SG_ 661 ApaSlot6_Sts "车位6可用状态";
CM_ SG_ 661 ApaSlot7_Sts "车位7可用状态";
CM_ SG_ 661 ApaSlot8_Sts "车位8可用状态";
CM_ SG_ 661 ApaSlot9_Sts "车位9可用状态";
CM_ SG_ 661 ApaSlot10_Sts "车位10可用状态";
CM_ SG_ 661 ApaSlot11_Sts "车位11可用状态";
CM_ SG_ 661 ApaSlot12_Sts "车位12可用状态";
CM_ SG_ 1099 IDC_44B_NM_SrcAdr "IDC NM Source ADDRESS";
CM_ SG_ 1099 IDC_44B_NM_Repeat "IDC NM Repeat";
CM_ SG_ 1099 IDC_44B_NM_ActvWakeup "IDC NM Active Wakeup";
CM_ SG_ 1099 IDC_44B_NM_Wus "Wake Up Source";
CM_ SG_ 1099 IDC_44B_NM_NMSts "Nework Management State";
CM_ SG_ 309 ADC_APA1Chks "CRC checksum. DataID and the following 7 bytes are included in CRC checksum calculation. Refer to E2E Spec.（Profile：1A；DataID：0x00E8）";
CM_ SG_ 309 ADC_APA1Cntr "Rolling counter. Refer to E2E Spec..";
CM_ SG_ 309 APA_FuncMode "APA工作模式";
CM_ SG_ 309 APA_TqReqFlg "APA扭矩请求标志位";
CM_ SG_ 309 APA_LgtMtnCtrReq "APA工作状态";
CM_ SG_ 309 APA_TqReqVld "APA扭矩请求有效位";
CM_ SG_ 309 APA_RdyReqVld "泊车Ready相关请求有效位";
CM_ SG_ 309 APA_TqReq "APA扭矩请求(轮端扭矩)";
CM_ SG_ 309 APA_RdyReq "泊车Ready相关请求";
CM_ SG_ 309 APA_GearCtrlEnable "目标档位请求使能信号";
CM_ SG_ 309 APA_TarGearReq "目标档位";
CM_ SG_ 309 APA_TarGearReqVld "目标档位请求有效";
CM_ SG_ 309 APA_AxReqEnable "APA请求的减速度值（-） 使能";
CM_ SG_ 309 APA_AxReqVld "APA请求的减速度值（-） 是否有效";
CM_ SG_ 309 APA_AxReq "APA请求的减速度（-）";
CM_ SG_ 309 ADC_APA2Chks "CRC checksum. DataID and the following 7 bytes are included in CRC checksum calculation. Refer to E2E Spec.（Profile：1A；DataID：0x00E9）";
CM_ SG_ 309 ADC_APA2Cntr "Rolling counter. Refer to E2E Spec..";
CM_ SG_ 309 APA_SysFailSts "APA系统故障";
CM_ SG_ 309 APA_DrvOffReq "APA起步请求使能";
CM_ SG_ 309 APA_VehStandstillReq "APA停车需求信号";
CM_ SG_ 309 APA_CtrlEPBAux "RPA请求释放EPB的安全信号";
CM_ SG_ 309 APA_ControlEPB "APA请求控制EPB";
CM_ SG_ 309 APA_MEBTarAReq "MEB功能请求";
CM_ SG_ 309 APA_MEBTarAVld "MEB请求减速度有效位";
CM_ SG_ 309 APA_MEBTarA "MEB请求的减速度";
CM_ SG_ 309 APA_PreFillReq "泊车Prefill请求";
CM_ SG_ 309 APA_FuncMode_EPS "APA功能模式";
CM_ SG_ 309 APA_BrkReqType "APA制动模式";
CM_ SG_ 309 APA_StrWhlAgReqActv "APA 功能请求控制方向盘";
CM_ SG_ 309 APA_DstToStop "剩余刹停距离";
CM_ SG_ 309 ADC_APA3Chks "CRC checksum. DataID and the following 7 bytes are included in CRC checksum calculation. Refer to E2E Spec.（Profile：1A；DataID：0x00EA）";
CM_ SG_ 309 ADC_APA3Cntr "Rolling counter. Refer to E2E Spec..";
CM_ SG_ 309 APA_StrWhlAgReq "APA功能请求目标转角";
CM_ SG_ 309 APA_StrWhlAgReqVld "APA功能请求目标转角有效性";
CM_ SG_ 309 APA_ControlEPBVld "APA控制EPB有效位";
CM_ SG_ 310 ADC_ADAS1Chks "CRC checksum. DataID and the following 7 bytes are included in CRC checksum calculation. Refer to E2E Spec.（Profile：1A；DataID：0x00EB）";
CM_ SG_ 310 ADC_ADAS1Cntr "Rolling counter. Refer to E2E Spec..";
CM_ SG_ 310 ADAS_LgtMtnCtrReq "ADAS工作状态";
CM_ SG_ 310 ADAS_LgtReqMode "ADAS工作模式";
CM_ SG_ 310 ADAS_TarTqReqEna "ADAS目标扭矩请求使能";
CM_ SG_ 310 ADAS_TarTqReqVld "ADAS目标扭矩请求有效位";
CM_ SG_ 310 ADAS_AMAPRequest "加速踏板抑制请求信号";
CM_ SG_ 310 ADAS_AMAPRequestvld "加速踏板抑制请求有效信号";
CM_ SG_ 310 ADAS_TarTqReq "ADAS目标扭矩请求(轮端扭矩)";
CM_ SG_ 310 ADAS_GearCtrEnable "目标档位请求使能信号";
CM_ SG_ 310 ADAS_TarGearReqVld "目标档位请求有效";
CM_ SG_ 310 ADAS_SysFailSts "ADAS系统故障状态";
CM_ SG_ 310 ADAS_TarGearReq "目标档位";
CM_ SG_ 310 ADAS_TarAxReqEna "ADAS目标加/减速度请求使能";
CM_ SG_ 310 ADAS_TarAxReqVld "ADAS目标加/减速请求有效";
CM_ SG_ 310 ADAS_DrvOffReq "ADAS起步请求";
CM_ SG_ 310 ADAS_TarAxReq "ADAS目标加/减速度请求";
CM_ SG_ 310 ADC_ADAS2Chks "CRC checksum. DataID and the following 7 bytes are included in CRC checksum calculation. Refer to E2E Spec.（Profile：1A；DataID：0x00EC）";
CM_ SG_ 310 ADC_ADAS2Cntr "Rolling counter. Refer to E2E Spec..";
CM_ SG_ 310 ADAS_DecelToStopReq "ADAS减速至停止请求";
CM_ SG_ 310 ADAS_TarAxUpperjerkLim "加速度变化率上限";
CM_ SG_ 310 ADAS_TarAxLowerjerkLim "加速度变化率下限";
CM_ SG_ 310 ADAS_Req_Prefill "Prefill请求";
CM_ SG_ 310 ADAS_Req_ABA "ABA请求";
CM_ SG_ 310 ADAS_Lvl_ABA "ABA等级";
CM_ SG_ 310 ADAS_Req_AWB "AWB请求";
CM_ SG_ 310 ADAS_Lvl_AWB "AWB分级";
CM_ SG_ 310 ADAS_TarAReq_AEB "AEB制动请求";
CM_ SG_ 310 ADAS_Decel_AEB "AEB减速度";
CM_ SG_ 310 ADAS_DecelTyp_AEB "AEB激活类别";
CM_ SG_ 310 ADAS_DecelVld_AEB "AEB减速度有效位";
CM_ SG_ 310 ADAS_Req_EPB "EPB请求拉起";
CM_ SG_ 310 ADAS_LatMtnCtrlSts "ADAS横向控制请求位";
CM_ SG_ 310 ADC_ADAS3Chks "CRC checksum. DataID and the following 7 bytes are included in CRC checksum calculation. Refer to E2E Spec.（Profile：1A；DataID：0x00ED）";
CM_ SG_ 310 ADC_ADAS3Cntr "Rolling counter. Refer to E2E Spec..";
CM_ SG_ 310 ADAS_LatFuncMode "ADAS横向功能";
CM_ SG_ 310 ADAS_PinionAgReqVld "ADAS方向盘转角有效性";
CM_ SG_ 310 ADAS_PinionAgReq "ADAS方向盘转角请求";
CM_ SG_ 310 ADAS_SteerAgDrvk "驾驶员干预系数";
CM_ SG_ 310 ADAS_ExtMaxRPCTrq "EPS可执行的最大扭矩限值";
CM_ SG_ 310 ADC_ADAS4Chks "CRC checksum. DataID and the following 7 bytes are included in CRC checksum calculation. Refer to E2E Spec.（Profile：1A；DataID：0x00EE）";
CM_ SG_ 310 ADC_ADAS4Cntr "Rolling counter. Refer to E2E Spec..";
CM_ SG_ 310 ADAS_ExtMinRPCTrq "EPS 可执行的最小扭矩限值";
CM_ SG_ 310 ADAS_Req_EPBVld "ADAS请求拉起EPB动作的有效位";
CM_ SG_ 310 ADS_DrvTarTq_J6 "驱动目标扭矩";
CM_ SG_ 310 ADS_SteerAgCtrlEnaReq_J6 "转向转角控制使能";
CM_ SG_ 923 AVAP_RemViewSts "远程查看功能状态信息(AVAP反馈)";
CM_ SG_ 923 AVAP_ViewSwtSts "视角切换状态反馈";
CM_ SG_ 923 AVAP_MirrReq "请求后视镜折叠展开";
CM_ SG_ 923 AVAP_ScreenshotReq "请求LVDS传输视频流截图";
CM_ SG_ 923 AVAP_LOCK_Req "EPA完成后，ADCU发送下电闭锁升窗指令";
CM_ SG_ 923 AVAP_LOCK_ReqVal "EPA完成后，ADCU发送下电闭锁升窗指令信号有效性";
CM_ SG_ 923 AVAP_TurnLightReq "转向灯请求";
CM_ SG_ 923 AVAP_Lpa_Sts "LPA功能状态";
CM_ SG_ 923 APA_FuncMode_BDC "APA工作模式";
CM_ SG_ 924 ADAS_LowHighBeamReq "智能远近光灯请求";
CM_ SG_ 924 ADC_HAD_CoolfluidReq "HAD冷液需求";
CM_ SG_ 924 ADAS_WarnReqRi "右侧外后视镜灯报警请求";
CM_ SG_ 924 ADAS_WarnReqLe "左侧外后视镜灯报警请求";
CM_ SG_ 924 ADAS_HornReq "喇叭声音请求";
CM_ SG_ 924 ADAS_TurnLightReq "转向灯请求";
CM_ SG_ 924 ADAS_FrontWasherReq "前风挡玻璃清洗请求";
CM_ SG_ 924 ADAS_FrontWiperReq "前雨刮工作请求";
CM_ SG_ 924 ADC_HAD_CoolingfluidflowRateReq "HAD冷却液流速请求";
CM_ SG_ 908 IDC0x38C1Chks "CRC checksum. DataID and the following 7 bytes are included in CRC checksum calculation. Refer to E2E Spec.（Profile：1A；DataID：0x0042）";
CM_ SG_ 908 IDC0x38C1Cntr "Rolling counter. Refer to E2E Spec.";
CM_ SG_ 908 LeftFrontUssSts "左前USS工作状态";
CM_ SG_ 908 FrontLeftUssSts "前左USS工作状态";
CM_ SG_ 908 FrontLeftCenterUssSts "前左中USS工作状态";
CM_ SG_ 908 FrontRightCenterUssSts "前右中USS工作状态";
CM_ SG_ 908 FrontRightUssSts "前右USS工作状态";
CM_ SG_ 908 RightFrontUssSts "右前USS工作状态";
CM_ SG_ 908 LeftBackUssSts "左后USS工作状态";
CM_ SG_ 908 BackLeftUssSts "后左USS工作状态";
CM_ SG_ 908 BackLeftCenterUssSts "后左中USS工作状态";
CM_ SG_ 908 BackRightCenterUssSts "后右中USS工作状态";
CM_ SG_ 908 BackRightUssSts "后右USS工作状态";
CM_ SG_ 908 RightBacktUssSts "右后USS工作状态";
CM_ SG_ 908 IDC0x38C2Chks "CRC checksum. DataID and the following 7 bytes are included in CRC checksum calculation. Refer to E2E Spec.（Profile：1A；DataID：0x0043）";
CM_ SG_ 908 IDC0x38C2Cntr "Rolling counter. Refer to E2E Spec.";
CM_ SG_ 908 PAS_FL_Distance "倒车雷达墙前左区报警距离";
CM_ SG_ 908 PAS_FML_Distance "倒车雷达墙前中左区报警距离";
CM_ SG_ 908 PAS_FMR_Distance "倒车雷达墙前中右区报警距离";
CM_ SG_ 908 PAS_FR_Distance "倒车雷达墙前右区报警距离";
CM_ SG_ 908 SDW_LSF1_Distance "侧边距离报警左侧前1区报警距离";
CM_ SG_ 908 SDW_LSF2_Distance "侧边距离报警左侧前2区报警距离";
CM_ SG_ 908 SDW_LSR2_Distance "侧边距离报警左侧后2区报警距离";
CM_ SG_ 908 SDW_LSR1_Distance "侧边距离报警左侧后1区报警距离";
CM_ SG_ 908 SDW_RSF1_Distance "侧边距离报警右侧前1区报警距离";
CM_ SG_ 908 SDW_RSF2_Distance "侧边距离报警右侧前2区报警距离";
CM_ SG_ 908 SDW_RSR2_Distance "侧边距离报警右侧后2区报警距离";
CM_ SG_ 908 SDW_RSR1_Distance "侧边距离报警右侧后1区报警距离";
CM_ SG_ 908 PAS_RL_Distance "倒车雷达墙后左区报警距离";
CM_ SG_ 908 PAS_RML_Distance "倒车雷达墙后中左区报警距离";
CM_ SG_ 908 PAS_RMR_Distance "倒车雷达墙后中右区报警距离";
CM_ SG_ 908 PAS_RR_Distance "倒车雷达墙后右报警距离";
CM_ SG_ 908 IDC0x38C3Chks "CRC checksum. DataID and the following 7 bytes are included in CRC checksum calculation. Refer to E2E Spec.（Profile：1A；DataID：0x0044）";
CM_ SG_ 908 IDC0x38C3Cntr "Rolling counter. Refer to E2E Spec.";
CM_ SG_ 908 ApaCalibrationParameter "泊车标定参数";
CM_ SG_ 908 ApaFactoryCalibrationSts "工厂泊车标定结果反馈";
CM_ SG_ 908 ApaFactoryCalibFailureRsn "工厂泊车标定失败原因反馈";
CM_ SG_ 908 ApaAfterSalesCalibrationSts "售后泊车标定结果反馈";
CM_ SG_ 908 ApaAfterSalesCalibStsProgress "售后泊车标定进度";
CM_ SG_ 908 ApaAfterSalesCalibFailureRsn "售后泊车标定失败原因反馈";
CM_ SG_ 442 ApaParkModSet "APA 泊车方式选择";
CM_ SG_ 442 ApaSwt "APA ON/OFF set request signal";
CM_ SG_ 442 ApaParkInSlotSet "APA泊入车位类型设置，用于自选车位";
CM_ SG_ 442 ApaParkOutDirSet "APA泊出方向";
CM_ SG_ 442 ApaTragParkSwt "APA tracking parking";
CM_ SG_ 442 ApaVoicBrdtSwt "APA voice broadcast switch";
CM_ SG_ 442 ApaParkStrtSet "APA泊车开始方式，自动/遥控";
CM_ SG_ 442 ApaPathSet "APA泊车路径选择，车头/车尾";
CM_ SG_ 442 SlotAutoSearchSwt "自动搜索车位功能开关";
CM_ SG_ 442 ApaModSet "APA模式设置";
CM_ SG_ 442 ApaDispSwt "APA display request signal. APA界面退出开关。";
CM_ SG_ 442 RpaDstSet "遥控泊车距离设定";
CM_ SG_ 442 ApaTouchScrnCmd "Touch screen command signal.";
CM_ SG_ 442 ScrnCoordX "Screen coord X 屏幕坐标x";
CM_ SG_ 442 ScrnCoordY "Screen coord Y 屏幕坐标y";
CM_ SG_ 504 BleRpa1Chks "CRC checksum. DataID and the following 7 bytes are included in CRC checksum calculation. Refer to E2E Spec.（Profile：1A；DataID：0x0009）";
CM_ SG_ 504 BleRpa1Cntr "Rolling counter. Refer to E2E Spec..";
CM_ SG_ 504 BleDrvrMtnIndcn "BLE  driver motion indication标志位：表征驾驶员是否一直动作";
CM_ SG_ 504 BleRpaStrtFlg "BLE  RPA states flag标志位，表征用户确认启动遥控泊车功能";
CM_ SG_ 504 BlePrkgInTypReq "BLE  parking In type request标志位，表征用户选择的泊入车位类型（预留，未使用）";
CM_ SG_ 504 BleBluStsFlg "BLE  bluetooth states flag标志位，表征蓝牙与T-BOX连接状态（预留，未使用）";
CM_ SG_ 504 BleRpaOnFlg "BLE  RPA ON flag手机APP进入遥控泊车界面标志位";
CM_ SG_ 504 BleParkAbortReq "BLE  park out abort request远程请求退出界面";
CM_ SG_ 504 BleParkAuthentStrtReq "BLE  park out authentication start request遥控泊车握手请求";
CM_ SG_ 504 BleLastStep "BLE  last step是否已点上一步";
CM_ SG_ 504 BleNextStep "BLE  next step是否已点下一步";
CM_ SG_ 504 BleParkoutModSel "BLE  parking out mode select标志位，表征用户选择的车位泊出方向";
CM_ SG_ 504 BleBdcRpaModReq "BLE  BDC RPA mode request请求BDC切换泊车模式";
CM_ SG_ 822 BleStrtEng "Bluetooth start engineSend this command 6 times to BDC for remote starting";
CM_ SG_ 822 BleBtSts "Bluetooth connected Status";
CM_ SG_ 823 BleSysSts "BLE System statusBLE系统状态";
CM_ SG_ 443 HumNaviCtryCod "Current country.See sheet CountryCodeNote: It's just necessary to list the countries of target market.";
CM_ SG_ 443 HumNaviCtryRoadTyp "Current road type.";
CM_ SG_ 443 ICC_NaviSpdLimit "导航限速信息";
CM_ SG_ 443 ICC_HDwarning "导航状态反馈";
CM_ SG_ 443 HumNaviSpdLimSts "Speed limit status";
CM_ SG_ 443 HU_NavSpeedLimitType "限速类型";
CM_ SG_ 443 HU_RampInfo "匝道信息";
CM_ SG_ 443 HumNaviSpdLimUnit "Speed limit unit";
CM_ SG_ 443 ICC_HD_TsrSignMisc "导航发送的交通标志信号";
CM_ SG_ 443 HU_RampSpdLim "匝道上的限速信息";
CM_ SG_ 443 ApaSlotSet "APA泊车车位选择";
CM_ SG_ 443 ICC_ApaExamStatus "辅助驾驶APA学习考试结果";
CM_ SG_ 443 ICC_AdasExamStatus "辅助驾驶ADAS学习考试结果";
CM_ SG_ 537 IPC8_F_VehicleSpeedIndi " The Valid of Vehicle Speed indication from IPC";
CM_ SG_ 537 IPC8_IcmDispSpdUnitTyp "ICM Display Speed Uinit Type.The unit of speed displayed in Dashboard";
CM_ SG_ 537 IPC8_N_VehicleSpeedIndi " Vehicle Speed indication from IPC";
CM_ SG_ 537 IPC8_AccFailFb "ACC Fail FeedbackError in the ACC message detected by the ICM, like timeout or alivecounter error.The error should distinguish reversible and irreversible errors.";
CM_ SG_ 537 IPC8_IcmDispFail "ICM Display Fail Error in the display or display control unit.";
CM_ SG_ 858 BCM12_St_VehicleMode "车辆模式 Vehicle Mode for 电源管理功能";
CM_ SG_ 529 TIM1_St_TIMSt "The status of trailer connection.拖车资质是否连接上";
CM_ SG_ 529 TIM1_St_TrailerLightsFaultSt "The fault status of trailer lights.";
CM_ SG_ 529 TIM1_St_SoftSwMemory "TIM saves ICC Soft Switch State（保留）TIM记忆拖挂模式软开关状态";
CM_ SG_ 529 TIM1_St_SoftSwMemoryNew "TIM saves ICC Soft Switch State (新增)TIM记忆拖挂模式软开关状态";
CM_ SG_ 225 EHC12_St_AVMSaleCalibration "calibration after sale 售后标定";
CM_ SG_ 225 EHC24_ParkingPlaceConfirm "self-selected parking slot confirm 自选车位确认";
CM_ SG_ 225 AvmViewSet "AVM view set request signal 切换全景视图命令，";
CM_ SG_ 225 AvmViewModSet "The AVM 2D/3D view set request signal.2D/3D模式切换";
CM_ SG_ 225 OvlyDispSwt "Overlay display set request signal. ";
CM_ SG_ 225 ObstclViewSwt "Obstacle view set request signal.障碍物显示开关.雷达显示开关。";
CM_ SG_ 225 AvmTrigByObstclSwt "'AVM trigger by PAObstacle' set request signal雷达障碍物触发全景显示用作智能开启开关（包含障碍物自动开启和转向灯自动开启全景以及雷达低速自动开启功能）。";
CM_ SG_ 225 AvmSwt "AVM off/on set request signal.";
CM_ SG_ 225 PasSwt "PAS off/on set request signal";
CM_ SG_ 225 EHC24_ExitButton "用户点击退出时，发送此信号。车辆应该先暂停，等待用户用户是否决定退出";
CM_ SG_ 225 EHC12_Set_RestoreSetting "恢复出厂设置";
CM_ SG_ 225 AvmVehLctSet "AVM 车身透明设置Lucent";
CM_ SG_ 225 AvmChasLctSet "AVM 底盘透明设置Lucent";
CM_ SG_ 225 AvmRoadCalSwt "AVM 道路标定信号Avm Road Calibration Switch";
CM_ SG_ 225 EHC12_St_SoftwareUpdate "Software updating软件升级";
CM_ SG_ 225 EHC12_St_AVMRoadCalibration "road calibration 道路标定";
CM_ SG_ 225 EHC12_St_AVMFactoryCalibration "calibration off line in factory下线标定";
CM_ SG_ 237 EHC22_NOA_ALCRequest_confirm "NOA换道确认选项";
CM_ SG_ 237 EHC22_NOA_ALC_TYPE "noa换道风格选则";
CM_ SG_ 237 EHC22_NOA_ALC_soundnotification "NOA换道声音提示选项";
CM_ SG_ 237 EHC22_HWA_EnbSw "HWA开关";
CM_ SG_ 237 EHC22_TJA_ICA_EnbSw "TJA/ICA开关";
CM_ SG_ 237 EHC22_IntelligentCornering_EnbSw "智能过弯开关";
CM_ SG_ 237 EHC22_ESS_EnbSw "ESS开关";
CM_ SG_ 237 EHC22_LKA_EnbSw "LKA开关";
CM_ SG_ 237 EHC22_LDW_EnbSw "LDW开关";
CM_ SG_ 237 EHC22_BSD_LCA_EnbSw "BSD_LCA开关";
CM_ SG_ 237 EHC22_DOW_EnbSw "DOW开关";
CM_ SG_ 237 EHC22_ELK_EnbSw "ELK开关";
CM_ SG_ 237 EHC22_AVM_EnbSw "AVM开关";
CM_ SG_ 237 EHC22_HMA_EnbSw "HMA开关";
CM_ SG_ 237 EHC22_BAV_EnbSw "拨杆盲区显示开关";
CM_ SG_ 237 EHC22_LCK_EnbSw "LCK开关";
CM_ SG_ 237 EHC22_ASLSw "ASL开关";
CM_ SG_ 237 EHC22_Set_FcwSwt "FCW开关设置";
CM_ SG_ 237 EHC22_Set_FCTA "FCTA前横穿预警";
CM_ SG_ 237 EHC22_Set_FCTB "FCTB前横穿制动";
CM_ SG_ 237 EHC22_Set_LDWLKALCKSen "LDW/LKA/LCK功能灵敏度设置信号";
CM_ SG_ 237 EHC22_Sw_LDWLKALCK "LDW/LKA/LCK系统上层软开关信号";
CM_ SG_ 237 EHC22_St_LDWLKALCKSet "辅助类型选择开关信号";
CM_ SG_ 237 EHC22_NOAFct_EnbSw "NOA function switch enable";
CM_ SG_ 237 EHC22_SDA_EnbSw "车机智慧躲闪辅助开关信号";
CM_ SG_ 237 EHC22_Set_JA "JA";
CM_ SG_ 237 EHC22_CDCShowoffset "'X'按钮信号";
CM_ SG_ 237 EHC22_Set_ELKSen "ELK功能灵敏度设置信号";
CM_ SG_ 1408 CAPE2_St_KeyIN "Key detected in vehicle，This signal is defined in the message CAPE_02; it show how many keys in vehicle, and which keys locates in:ESCL used key detected signal for column unlockBCM used key detected signal to lock the doors.(only No UID found,1000 0000) if  UID1 and UID2  inside of vehicle, it will be indicated 0011.It will indicate which UIDs are closed in vehicle when any door open transit to all door close. this status shall be store in EEROM. indicate the UIDs in vehicle 0000 0000 = Default value0000 XXX1 = UID 1 is found.0000 XX1X = UID 2 is found0000 X1XX = UID 3 is found  0000 1XXX = UID 4 is found1000 0000=No UID found";
CM_ SG_ 226 EHC25_Set_RecoverTracking "恢复循迹Recover_Tracking";
CM_ SG_ 226 EHC25_Set_RestoreParking "恢复泊车Restore_Parking";
CM_ SG_ 226 EHC25_FastBackCar_Mode "APA back car modeAPA倒车模式切换。快速倒车是指车机在还没有完全启动处于播放画面时候，收到R档信号，要切换成后视影像的画面";
CM_ SG_ 226 EHC25_Set_ViewSource "Current View Source，当前源";
CM_ SG_ 226 EHC25_Set_AEBOption "AEB OPTION stsAEB TTC灵敏度设定";
CM_ SG_ 226 EHC25_OPerTimeOutExit_Set "超时操作退出设置信号";
CM_ SG_ 226 EHC25_Set_TLA "TLA交通灯识别开关";
CM_ SG_ 226 EHC25_Set_SLA "SLA 速度限制提醒开关";
CM_ SG_ 226 EHC25_Set_SLAWarn "SLA 超速报警开关";
CM_ SG_ 226 EH25_Set_SLASpdLimOffs "SLA超速报警偏差值";
CM_ SG_ 226 EHC25_Set_ASL "ASL智能辅助限速开关";
CM_ SG_ 226 EHC25_MODFunction_Set "MOD功能开关信号";
CM_ SG_ 226 EHC25_Set_Color "车身颜色设置";
CM_ SG_ 444 ICC_N_SlotAngle "Slot Angle 车位角度";
CM_ SG_ 444 ICC_N_CoorA_X "slot point A Coordination X, 车位点A";
CM_ SG_ 444 ICC_ATSMode "ATS岩石模式进入请求信号";
CM_ SG_ 444 ICC_N_CoorA_Y "slot point A Coordination Y, 车位点A";
CM_ SG_ 444 ICC_ScrnAngle "自选车位：车头朝向与车辆行驶方向夹角";
CM_ SG_ 444 ICCAdasApaSocOffSwt "智驾节能模式开关";
CM_ SG_ 444 ICC_AvapViewSource "车机界面状态";
CM_ SG_ 444 ICC_AvapSysSts "全景状态反馈";
CM_ SG_ 444 ICCAvmCalibrationParameter "全景标定参数";
CM_ SG_ 444 ICCApaCalibrationReq "标定触发信号";
CM_ SG_ 648 SWS_Cruise "6_巡航激活与退出";
CM_ SG_ 648 SWS_360 "5_360全景";
CM_ SG_ 648 SWS_AccTiGapPlus "4_车距+";
CM_ SG_ 648 SWS_AccTiGapMinus "3_车距-";
CM_ SG_ 648 SWS_LeRollUp "1_车速+";
CM_ SG_ 648 SWS_LeRollDwn "2_车速-";
CM_ SG_ 311 Pdcu0x137Chks1 "CRC checksum. DataID and the following 7 bytes are included in CRC checksum calculation. Refer to E2E Spec.（Profile：1A，DataID=0x0041）";
CM_ SG_ 311 Pdcu0x137Cntr1 "Rolling counter. Refer to E2E Spec.（Counter：0x0~0xE）";
CM_ SG_ 311 PDCU_PtTqAvl "VCU动力系统可用状态";
CM_ SG_ 311 PDCU_VehDrvMotMaxElecTqVld "最大可用扭矩有效位";
CM_ SG_ 311 PDCU_AVAPhandshakeSts "VCU握手状态";
CM_ SG_ 311 PDCU_GasPedalInhibition "加速踏板抑制信号";
CM_ SG_ 311 PDCU_AVAPFltFb "VCU/HDCU主动退出握手原因";
CM_ SG_ 311 PdcuApaLeverInterventionVld "驾驶员干预档位状态有效位";
CM_ SG_ 311 PDCU_LgtReqActiveSts "VCU握手状态";
CM_ SG_ 311 PDCU_VehDrvMotMaxElecTq "整车允许驱动电机最大电动转矩(总和)(轮端扭矩)";
CM_ SG_ 311 PDCU_ADLCFailureSts "VCU/PDCU主动退出握手原因";
CM_ SG_ 833 WCBS_N_EBRTrqACT "ESC实际执行的外部制动力";
CM_ SG_ 536 WCBS_ESP7_ReLeSnsrFlt "Rear left sensor fault. The failure status of rear left wheel speed sensor.左后轮速传感器故障信息";
CM_ SG_ 536 WCBS_ESP7_ReRiSnsrFlt "Rear right sensor fault. The failure status of rear right wheel speed sensor.右后轮速传感器故障信息";
CM_ SG_ 536 WCBS_ESP7_FrntLeSnsrFlt "Front left sensor fault. The failure status of front left wheel speed sensor.左前轮速传感器故障信息";
CM_ SG_ 536 WCBS_ESP7_FrntRiSnsrFlt "Front right sensor fault. The failure status of front right wheel speed sensor.右前轮速传感器故障信息";
CM_ SG_ 536 WCBS_ESP7_BrakeTorqOn4Wheels "轮端总的液压制动力矩(EPB除外)按照实际情况发出，不关注车型配置。This signal is the total hydraulic brake torque on 4 weels(except EPB etc.). If current brake torque is over 15000Nm, it will always send the max value 15000Nm. The signal is always sent according to current brake torque, not consider vehicle variant.";
CM_ SG_ 536 IBS_VDCInfo "VDC激活信息";
CM_ SG_ 1583 TBOX_CrtTi_Day "当前时间_日";
CM_ SG_ 1583 TBOX_CrtTi_Hr "当前时间_小时";
CM_ SG_ 1583 TBOX_CrtTi_Mins "当前时间_分钟";
CM_ SG_ 1583 TBOX_CrtTi_Yr "当前时间_年";
CM_ SG_ 1583 TBOX_CrtTi_Mth "当前时间_月";
CM_ SG_ 1583 TBOX_CrtTi_Sec "当前时间_秒";
CM_ SG_ 315 EPS_SteerTorqueByADASReq "EPS执行ADAS方向盘手力矩";
CM_ SG_ 315 EPS_SteerTorqueVldByADASReq "EPS执行ADAS方向盘手力矩有效位";
CM_ SG_ 315 EPS_SteerSnsrSts "转角传感器状态";
CM_ SG_ 315 EPS_DrvrSteerTqDir "驾驶员转向力矩方向";
CM_ SG_ 315 EPS_SteerDrvrOvrd_J6 "驾驶员转向干预状态";
CM_ SG_ 410 Yrs1Chks "CRC checksum. DataID and the following 7 bytes are included in CRC checksum calculation. Refer to E2E Spec.(Profile:1A,DataID:0x001F)";
CM_ SG_ 410 Yrs1Cntr "Rolling counter. Refer to E2E Spec.";
CM_ SG_ 410 LatAcce "Lateral Acceleration横向加速度(左侧为正,右侧为负)";
CM_ SG_ 410 LgtAcce "Longitudinal Acceleration纵向加速度(向前为负,向后为正)";
CM_ SG_ 410 YawRate "Yaw Rate偏航率(逆时针为正,顺时针为负)";
CM_ SG_ 410 LatSnsrSts "Lateral Sensor Status横向传感器的状态";
CM_ SG_ 410 LgtSnsrSts "Longitudinal Sensor Status纵向传感器的状态";
CM_ SG_ 410 YawRateSnsrSts "Yaw Rate Sensor Status偏航率传感器的状态";
CM_ SG_ 410 YawRateSnsrCalSts "Yaw Rate Sensor Calibration Status偏航率传感器的标定状态（整个横摆角数据来源为一个传感器，该传感器有3个channel，来分别输出横向，纵向，以及偏航率，3个channel分别有自身的故障判定功能，该标定信号为整个传感器的标定状态）";

BA_DEF_ BO_  "NmMessage" ENUM "No","Yes";
BA_DEF_ BO_  "DiagState" ENUM  "No","Yes";
BA_DEF_ BO_  "DiagResponse" ENUM  "No","Yes";
BA_DEF_ BO_  "GenMsgSendType" ENUM  "cyclic","NoMsgSendType","IfActive","Event","CA","CE";
BA_DEF_ BO_  "GenMsgCycleTime" INT 0 0;
BA_DEF_ SG_  "GenSigSendType" ENUM  "cyclic","OnChange","OnWrite","IfActive","OnChangeWithRepetition","OnWriteWithRepetition","IfActiveWithRepetition","CA","CE","Event";
BA_DEF_ SG_  "GenSigStartValue" INT 0 0;
BA_DEF_ BO_  "GenMsgCycleTimeFast" INT 0 0;
BA_DEF_ BO_  "GenMsgNrOfRepetition" INT 0 0;
BA_DEF_ BO_  "CANFD_BRS" ENUM  "0","1";
BA_DEF_ BO_  "VFrameFormat" ENUM  "StandardCAN","ExtendedCAN","reserved","reserved","reserved","reserved","reserved","reserved","reserved","reserved","reserved","reserved","reserved","reserved","StandardCAN_FD","ExtendedCAN_FD";
BA_DEF_ BO_  "GenMsgILSupport" ENUM  "No","Yes";
BA_DEF_ SG_ "sigDespEng" STRING;
BA_DEF_ SG_ "sigSecLevel" STRING;
BA_DEF_ SG_ "sigConfig" STRING;
BA_DEF_ SG_ "sigExplanation" STRING;

BA_DEF_DEF_  "NmMessage" "No";
BA_DEF_DEF_  "DiagState" "No";
BA_DEF_DEF_  "DiagResponse" "No";
BA_DEF_DEF_  "GenMsgSendType" "cyclic";
BA_DEF_DEF_  "GenMsgCycleTime" 0;
BA_DEF_DEF_  "GenSigSendType" "cyclic";
BA_DEF_DEF_  "GenSigStartValue" 0;
BA_DEF_DEF_  "GenMsgCycleTimeFast" 0;
BA_DEF_DEF_  "GenMsgNrOfRepetition" 0;
BA_DEF_DEF_  "CANFD_BRS" "1";
BA_DEF_DEF_  "VFrameFormat" "StandardCAN";
BA_DEF_DEF_  "GenMsgILSupport" "Yes";
BA_DEF_DEF_ "sigDespEng" "" ;
BA_DEF_DEF_ "sigSecLevel" "QM" ;
BA_DEF_DEF_ "sigConfig" "" ;
BA_DEF_DEF_ "sigExplanation" "" ;
BA_ "GenMsgCycleTime" BO_ 659 100;
BA_ "VFrameFormat" BO_ 659 14;
BA_ "sigSecLevel"  SG_ 659 APASlot_1_source "";
BA_ "sigSecLevel"  SG_ 659 APASlot__1_Direction "";
BA_ "sigSecLevel"  SG_ 659 APASlot_2_source "";
BA_ "sigSecLevel"  SG_ 659 APASlot_3_source "";
BA_ "sigSecLevel"  SG_ 659 APASlot__2_Direction "";
BA_ "sigSecLevel"  SG_ 659 APASlot_4_source "";
BA_ "sigSecLevel"  SG_ 659 APASlot_5_source "";
BA_ "sigSecLevel"  SG_ 659 APASlot__3_Direction "";
BA_ "sigSecLevel"  SG_ 659 APASlot_6_source "";
BA_ "sigSecLevel"  SG_ 659 APASlot_7_source "";
BA_ "sigSecLevel"  SG_ 659 APASlot__4_Direction "";
BA_ "sigSecLevel"  SG_ 659 APASlot_8_source "";
BA_ "sigSecLevel"  SG_ 659 APASlot_9_source "";
BA_ "sigSecLevel"  SG_ 659 APASlot__5_Direction "";
BA_ "sigSecLevel"  SG_ 659 APASlot_10_source "";
BA_ "sigSecLevel"  SG_ 659 APASlot_11_source "";
BA_ "sigSecLevel"  SG_ 659 APASlot__6_Direction "";
BA_ "sigSecLevel"  SG_ 659 APASlot_12_source "";
BA_ "sigSecLevel"  SG_ 659 APASlot__7_Direction "";
BA_ "sigSecLevel"  SG_ 659 APASlot__8_Direction "";
BA_ "sigSecLevel"  SG_ 659 APASlot__9_Direction "";
BA_ "sigSecLevel"  SG_ 659 APASlot__10_Direction "";
BA_ "sigSecLevel"  SG_ 659 APASlot__11_Direction "";
BA_ "sigSecLevel"  SG_ 659 APASlot__12_Direction "";
BA_ "sigSecLevel"  SG_ 659 APASlot__13_Direction "";
BA_ "sigSecLevel"  SG_ 659 APASlot__14_Direction "";
BA_ "sigSecLevel"  SG_ 659 APASlot__1_Type "";
BA_ "sigSecLevel"  SG_ 659 APASlot__2_Type "";
BA_ "sigSecLevel"  SG_ 659 APASlot__3_Type "";
BA_ "sigSecLevel"  SG_ 659 APASlot__4_Type "";
BA_ "sigSecLevel"  SG_ 659 APASlot__5_Type "";
BA_ "sigSecLevel"  SG_ 659 APASlot__6_Type "";
BA_ "sigSecLevel"  SG_ 659 APASlot__7_Type "";
BA_ "sigSecLevel"  SG_ 659 APASlot__8_Type "";
BA_ "sigSecLevel"  SG_ 659 APASlot__9_Type "";
BA_ "sigSecLevel"  SG_ 659 APASlot__10_Type "";
BA_ "sigSecLevel"  SG_ 659 APASlot__11_Type "";
BA_ "sigSecLevel"  SG_ 659 APASlot__12_Type "";
BA_ "sigSecLevel"  SG_ 659 SlotTarg_ID "";
BA_ "sigSecLevel"  SG_ 659 Slot1_ID "";
BA_ "sigSecLevel"  SG_ 659 Slot2_ID "";
BA_ "sigSecLevel"  SG_ 659 Slot3_ID "";
BA_ "sigSecLevel"  SG_ 659 Slot4_ID "";
BA_ "sigSecLevel"  SG_ 659 Slot5_ID "";
BA_ "sigSecLevel"  SG_ 659 Slot6_ID "";
BA_ "sigSecLevel"  SG_ 659 Slot7_ID "";
BA_ "sigSecLevel"  SG_ 659 Slot8_ID "";
BA_ "sigSecLevel"  SG_ 659 Slot9_ID "";
BA_ "sigSecLevel"  SG_ 659 Slot10_ID "";
BA_ "sigSecLevel"  SG_ 659 Slot11_ID "";
BA_ "sigSecLevel"  SG_ 659 Slot12_ID "";
BA_ "GenSigStartValue" SG_ 659 SlotTargACoorX 255;
BA_ "sigSecLevel"  SG_ 659 SlotTargACoorX "";
BA_ "GenSigStartValue" SG_ 659 SlotTargACoorY 255;
BA_ "sigSecLevel"  SG_ 659 SlotTargACoorY "";
BA_ "GenSigStartValue" SG_ 659 SlotTargBCoorX 255;
BA_ "sigSecLevel"  SG_ 659 SlotTargBCoorX "";
BA_ "GenSigStartValue" SG_ 659 SlotTargBCoorY 255;
BA_ "sigSecLevel"  SG_ 659 SlotTargBCoorY "";
BA_ "GenSigStartValue" SG_ 659 SlotTargCCoorX 255;
BA_ "sigSecLevel"  SG_ 659 SlotTargCCoorX "";
BA_ "GenSigStartValue" SG_ 659 SlotTargCCoorY 255;
BA_ "sigSecLevel"  SG_ 659 SlotTargCCoorY "";
BA_ "GenSigStartValue" SG_ 659 SlotTargDCoorX 255;
BA_ "sigSecLevel"  SG_ 659 SlotTargDCoorX "";
BA_ "GenSigStartValue" SG_ 659 SlotTargDCoorY 255;
BA_ "sigSecLevel"  SG_ 659 SlotTargDCoorY "";
BA_ "GenSigStartValue" SG_ 659 Slot1ACoorX 255;
BA_ "sigSecLevel"  SG_ 659 Slot1ACoorX "";
BA_ "GenSigStartValue" SG_ 659 Slot1ACoorY 255;
BA_ "sigSecLevel"  SG_ 659 Slot1ACoorY "";
BA_ "GenSigStartValue" SG_ 659 Slot1BCoorX 255;
BA_ "sigSecLevel"  SG_ 659 Slot1BCoorX "";
BA_ "GenSigStartValue" SG_ 659 Slot1BCoorY 255;
BA_ "sigSecLevel"  SG_ 659 Slot1BCoorY "";
BA_ "GenSigStartValue" SG_ 659 Slot1CCoorX 255;
BA_ "sigSecLevel"  SG_ 659 Slot1CCoorX "";
BA_ "GenSigStartValue" SG_ 659 Slot1CCoorY 255;
BA_ "sigSecLevel"  SG_ 659 Slot1CCoorY "";
BA_ "GenSigStartValue" SG_ 659 Slot1DCoorX 255;
BA_ "sigSecLevel"  SG_ 659 Slot1DCoorX "";
BA_ "GenSigStartValue" SG_ 659 Slot1DCoorY 255;
BA_ "sigSecLevel"  SG_ 659 Slot1DCoorY "";
BA_ "GenSigStartValue" SG_ 659 Slot2ACoorX 255;
BA_ "sigSecLevel"  SG_ 659 Slot2ACoorX "";
BA_ "GenSigStartValue" SG_ 659 Slot2ACoorY 255;
BA_ "sigSecLevel"  SG_ 659 Slot2ACoorY "";
BA_ "GenSigStartValue" SG_ 659 Slot2BCoorX 255;
BA_ "sigSecLevel"  SG_ 659 Slot2BCoorX "";
BA_ "GenSigStartValue" SG_ 659 Slot2BCoorY 255;
BA_ "sigSecLevel"  SG_ 659 Slot2BCoorY "";
BA_ "GenSigStartValue" SG_ 659 Slot2CCoorX 255;
BA_ "sigSecLevel"  SG_ 659 Slot2CCoorX "";
BA_ "GenSigStartValue" SG_ 659 Slot2CCoorY 255;
BA_ "sigSecLevel"  SG_ 659 Slot2CCoorY "";
BA_ "GenSigStartValue" SG_ 659 Slot2DCoorX 255;
BA_ "sigSecLevel"  SG_ 659 Slot2DCoorX "";
BA_ "GenSigStartValue" SG_ 659 Slot2DCoorY 255;
BA_ "sigSecLevel"  SG_ 659 Slot2DCoorY "";
BA_ "GenSigStartValue" SG_ 659 Slot3ACoorX 255;
BA_ "sigSecLevel"  SG_ 659 Slot3ACoorX "";
BA_ "GenSigStartValue" SG_ 659 Slot3ACoorY 255;
BA_ "sigSecLevel"  SG_ 659 Slot3ACoorY "";
BA_ "GenSigStartValue" SG_ 659 Slot3BCoorX 255;
BA_ "sigSecLevel"  SG_ 659 Slot3BCoorX "";
BA_ "GenSigStartValue" SG_ 659 Slot3BCoorY 255;
BA_ "sigSecLevel"  SG_ 659 Slot3BCoorY "";
BA_ "GenSigStartValue" SG_ 659 Slot3CCoorX 255;
BA_ "sigSecLevel"  SG_ 659 Slot3CCoorX "";
BA_ "GenSigStartValue" SG_ 659 Slot3CCoorY 255;
BA_ "sigSecLevel"  SG_ 659 Slot3CCoorY "";
BA_ "GenSigStartValue" SG_ 659 Slot3DCoorX 255;
BA_ "sigSecLevel"  SG_ 659 Slot3DCoorX "";
BA_ "GenSigStartValue" SG_ 659 Slot3DCoorY 255;
BA_ "sigSecLevel"  SG_ 659 Slot3DCoorY "";
BA_ "GenSigStartValue" SG_ 659 Slot4ACoorX 255;
BA_ "sigSecLevel"  SG_ 659 Slot4ACoorX "";
BA_ "GenSigStartValue" SG_ 659 Slot4ACoorY 255;
BA_ "sigSecLevel"  SG_ 659 Slot4ACoorY "";
BA_ "GenSigStartValue" SG_ 659 Slot4BCoorX 255;
BA_ "sigSecLevel"  SG_ 659 Slot4BCoorX "";
BA_ "GenSigStartValue" SG_ 659 Slot4BCoorY 255;
BA_ "sigSecLevel"  SG_ 659 Slot4BCoorY "";
BA_ "GenSigStartValue" SG_ 659 Slot4CCoorX 255;
BA_ "sigSecLevel"  SG_ 659 Slot4CCoorX "";
BA_ "GenSigStartValue" SG_ 659 Slot4CCoorY 255;
BA_ "sigSecLevel"  SG_ 659 Slot4CCoorY "";
BA_ "GenSigStartValue" SG_ 659 Slot4DCoorX 255;
BA_ "sigSecLevel"  SG_ 659 Slot4DCoorX "";
BA_ "GenSigStartValue" SG_ 659 Slot4DCoorY 255;
BA_ "sigSecLevel"  SG_ 659 Slot4DCoorY "";
BA_ "GenMsgCycleTime" BO_ 660 100;
BA_ "VFrameFormat" BO_ 660 14;
BA_ "GenSigStartValue" SG_ 660 Slot5ACoorX 255;
BA_ "sigSecLevel"  SG_ 660 Slot5ACoorX "";
BA_ "GenSigStartValue" SG_ 660 Slot5ACoorY 255;
BA_ "sigSecLevel"  SG_ 660 Slot5ACoorY "";
BA_ "GenSigStartValue" SG_ 660 Slot5BCoorX 255;
BA_ "sigSecLevel"  SG_ 660 Slot5BCoorX "";
BA_ "GenSigStartValue" SG_ 660 Slot5BCoorY 255;
BA_ "sigSecLevel"  SG_ 660 Slot5BCoorY "";
BA_ "GenSigStartValue" SG_ 660 Slot5CCoorX 255;
BA_ "sigSecLevel"  SG_ 660 Slot5CCoorX "";
BA_ "GenSigStartValue" SG_ 660 Slot5CCoorY 255;
BA_ "sigSecLevel"  SG_ 660 Slot5CCoorY "";
BA_ "GenSigStartValue" SG_ 660 Slot5DCoorX 255;
BA_ "sigSecLevel"  SG_ 660 Slot5DCoorX "";
BA_ "GenSigStartValue" SG_ 660 Slot5DCoorY 255;
BA_ "sigSecLevel"  SG_ 660 Slot5DCoorY "";
BA_ "GenSigStartValue" SG_ 660 Slot6ACoorX 255;
BA_ "sigSecLevel"  SG_ 660 Slot6ACoorX "";
BA_ "GenSigStartValue" SG_ 660 Slot6ACoorY 255;
BA_ "sigSecLevel"  SG_ 660 Slot6ACoorY "";
BA_ "GenSigStartValue" SG_ 660 Slot6BCoorX 255;
BA_ "sigSecLevel"  SG_ 660 Slot6BCoorX "";
BA_ "GenSigStartValue" SG_ 660 Slot6BCoorY 255;
BA_ "sigSecLevel"  SG_ 660 Slot6BCoorY "";
BA_ "GenSigStartValue" SG_ 660 Slot6CCoorX 255;
BA_ "sigSecLevel"  SG_ 660 Slot6CCoorX "";
BA_ "GenSigStartValue" SG_ 660 Slot6CCoorY 255;
BA_ "sigSecLevel"  SG_ 660 Slot6CCoorY "";
BA_ "GenSigStartValue" SG_ 660 Slot6DCoorX 255;
BA_ "sigSecLevel"  SG_ 660 Slot6DCoorX "";
BA_ "GenSigStartValue" SG_ 660 Slot6DCoorY 255;
BA_ "sigSecLevel"  SG_ 660 Slot6DCoorY "";
BA_ "GenSigStartValue" SG_ 660 Slot7ACoorX 255;
BA_ "sigSecLevel"  SG_ 660 Slot7ACoorX "";
BA_ "GenSigStartValue" SG_ 660 Slot7ACoorY 255;
BA_ "sigSecLevel"  SG_ 660 Slot7ACoorY "";
BA_ "GenSigStartValue" SG_ 660 Slot7BCoorX 255;
BA_ "sigSecLevel"  SG_ 660 Slot7BCoorX "";
BA_ "GenSigStartValue" SG_ 660 Slot7BCoorY 255;
BA_ "sigSecLevel"  SG_ 660 Slot7BCoorY "";
BA_ "GenSigStartValue" SG_ 660 Slot7CCoorX 255;
BA_ "sigSecLevel"  SG_ 660 Slot7CCoorX "";
BA_ "GenSigStartValue" SG_ 660 Slot7CCoorY 255;
BA_ "sigSecLevel"  SG_ 660 Slot7CCoorY "";
BA_ "GenSigStartValue" SG_ 660 Slot7DCoorX 255;
BA_ "sigSecLevel"  SG_ 660 Slot7DCoorX "";
BA_ "GenSigStartValue" SG_ 660 Slot7DCoorY 255;
BA_ "sigSecLevel"  SG_ 660 Slot7DCoorY "";
BA_ "GenSigStartValue" SG_ 660 Slot8ACoorX 255;
BA_ "sigSecLevel"  SG_ 660 Slot8ACoorX "";
BA_ "GenSigStartValue" SG_ 660 Slot8ACoorY 255;
BA_ "sigSecLevel"  SG_ 660 Slot8ACoorY "";
BA_ "GenSigStartValue" SG_ 660 Slot8BCoorX 255;
BA_ "sigSecLevel"  SG_ 660 Slot8BCoorX "";
BA_ "GenSigStartValue" SG_ 660 Slot8BCoorY 255;
BA_ "sigSecLevel"  SG_ 660 Slot8BCoorY "";
BA_ "GenSigStartValue" SG_ 660 Slot8CCoorX 255;
BA_ "sigSecLevel"  SG_ 660 Slot8CCoorX "";
BA_ "GenSigStartValue" SG_ 660 Slot8CCoorY 255;
BA_ "sigSecLevel"  SG_ 660 Slot8CCoorY "";
BA_ "GenSigStartValue" SG_ 660 Slot8DCoorX 255;
BA_ "sigSecLevel"  SG_ 660 Slot8DCoorX "";
BA_ "GenSigStartValue" SG_ 660 Slot8DCoorY 255;
BA_ "sigSecLevel"  SG_ 660 Slot8DCoorY "";
BA_ "GenSigStartValue" SG_ 660 Slot9ACoorX 255;
BA_ "sigSecLevel"  SG_ 660 Slot9ACoorX "";
BA_ "GenSigStartValue" SG_ 660 Slot9ACoorY 255;
BA_ "sigSecLevel"  SG_ 660 Slot9ACoorY "";
BA_ "GenSigStartValue" SG_ 660 Slot9BCoorX 255;
BA_ "sigSecLevel"  SG_ 660 Slot9BCoorX "";
BA_ "GenSigStartValue" SG_ 660 Slot9BCoorY 255;
BA_ "sigSecLevel"  SG_ 660 Slot9BCoorY "";
BA_ "GenSigStartValue" SG_ 660 Slot9CCoorX 255;
BA_ "sigSecLevel"  SG_ 660 Slot9CCoorX "";
BA_ "GenSigStartValue" SG_ 660 Slot9CCoorY 255;
BA_ "sigSecLevel"  SG_ 660 Slot9CCoorY "";
BA_ "GenSigStartValue" SG_ 660 Slot9DCoorX 255;
BA_ "sigSecLevel"  SG_ 660 Slot9DCoorX "";
BA_ "GenSigStartValue" SG_ 660 Slot9DCoorY 255;
BA_ "sigSecLevel"  SG_ 660 Slot9DCoorY "";
BA_ "GenSigStartValue" SG_ 660 Slot10ACoorX 255;
BA_ "sigSecLevel"  SG_ 660 Slot10ACoorX "";
BA_ "GenSigStartValue" SG_ 660 Slot10ACoorY 255;
BA_ "sigSecLevel"  SG_ 660 Slot10ACoorY "";
BA_ "GenSigStartValue" SG_ 660 Slot10BCoorX 255;
BA_ "sigSecLevel"  SG_ 660 Slot10BCoorX "";
BA_ "GenSigStartValue" SG_ 660 Slot10BCoorY 255;
BA_ "sigSecLevel"  SG_ 660 Slot10BCoorY "";
BA_ "GenSigStartValue" SG_ 660 Slot10CCoorX 255;
BA_ "sigSecLevel"  SG_ 660 Slot10CCoorX "";
BA_ "GenSigStartValue" SG_ 660 Slot10CCoorY 255;
BA_ "sigSecLevel"  SG_ 660 Slot10CCoorY "";
BA_ "GenSigStartValue" SG_ 660 Slot10DCoorX 255;
BA_ "sigSecLevel"  SG_ 660 Slot10DCoorX "";
BA_ "GenSigStartValue" SG_ 660 Slot10DCoorY 255;
BA_ "sigSecLevel"  SG_ 660 Slot10DCoorY "";
BA_ "GenSigStartValue" SG_ 660 Slot11ACoorX 255;
BA_ "sigSecLevel"  SG_ 660 Slot11ACoorX "";
BA_ "GenSigStartValue" SG_ 660 Slot11ACoorY 255;
BA_ "sigSecLevel"  SG_ 660 Slot11ACoorY "";
BA_ "GenSigStartValue" SG_ 660 Slot11BCoorX 255;
BA_ "sigSecLevel"  SG_ 660 Slot11BCoorX "";
BA_ "GenSigStartValue" SG_ 660 Slot11BCoorY 255;
BA_ "sigSecLevel"  SG_ 660 Slot11BCoorY "";
BA_ "GenSigStartValue" SG_ 660 Slot11CCoorX 255;
BA_ "sigSecLevel"  SG_ 660 Slot11CCoorX "";
BA_ "GenSigStartValue" SG_ 660 Slot11CCoorY 255;
BA_ "sigSecLevel"  SG_ 660 Slot11CCoorY "";
BA_ "GenSigStartValue" SG_ 660 Slot11DCoorX 255;
BA_ "sigSecLevel"  SG_ 660 Slot11DCoorX "";
BA_ "GenSigStartValue" SG_ 660 Slot11DCoorY 255;
BA_ "sigSecLevel"  SG_ 660 Slot11DCoorY "";
BA_ "GenSigStartValue" SG_ 660 Slot12ACoorX 255;
BA_ "sigSecLevel"  SG_ 660 Slot12ACoorX "";
BA_ "GenSigStartValue" SG_ 660 Slot12ACoorY 255;
BA_ "sigSecLevel"  SG_ 660 Slot12ACoorY "";
BA_ "GenSigStartValue" SG_ 660 Slot12BCoorX 255;
BA_ "sigSecLevel"  SG_ 660 Slot12BCoorX "";
BA_ "GenSigStartValue" SG_ 660 Slot12BCoorY 255;
BA_ "sigSecLevel"  SG_ 660 Slot12BCoorY "";
BA_ "GenSigStartValue" SG_ 660 Slot12CCoorX 255;
BA_ "sigSecLevel"  SG_ 660 Slot12CCoorX "";
BA_ "GenSigStartValue" SG_ 660 Slot12CCoorY 255;
BA_ "sigSecLevel"  SG_ 660 Slot12CCoorY "";
BA_ "GenSigStartValue" SG_ 660 Slot12DCoorX 255;
BA_ "sigSecLevel"  SG_ 660 Slot12DCoorX "";
BA_ "GenSigStartValue" SG_ 660 Slot12DCoorY 255;
BA_ "sigSecLevel"  SG_ 660 Slot12DCoorY "";
BA_ "GenMsgCycleTime" BO_ 920 100;
BA_ "VFrameFormat" BO_ 920 14;
BA_ "sigSecLevel"  SG_ 920 AVM3_St_BuzzerAlarmPattern "";
BA_ "sigExplanation"  SG_ 920 AVM3_St_BuzzerAlarmPattern "cdc";
BA_ "sigSecLevel"  SG_ 920 AvmDispReq "";
BA_ "sigConfig"  SG_ 920 AvmDispReq "tsp";
BA_ "sigSecLevel"  SG_ 920 ObstclViewSts "";
BA_ "sigSecLevel"  SG_ 920 AvmTrigByObstclSts "";
BA_ "sigSecLevel"  SG_ 920 OvlDispSts "";
BA_ "sigSecLevel"  SG_ 920 AvmViewModSts "";
BA_ "sigSecLevel"  SG_ 920 AvmViewMod "";
BA_ "sigSecLevel"  SG_ 920 AvmChasLctSts "";
BA_ "sigSecLevel"  SG_ 920 AvmRoadCalSts "";
BA_ "sigSecLevel"  SG_ 920 AvmRoadCalProgsSts "";
BA_ "sigSecLevel"  SG_ 920 EolCalSts "";
BA_ "sigConfig"  SG_ 920 EolCalSts "tsp";
BA_ "sigSecLevel"  SG_ 920 ApaSentiWarningMsg "";
BA_ "sigConfig"  SG_ 920 ApaSentiWarningMsg "哨兵,TSP";
BA_ "sigSecLevel"  SG_ 920 ApaSentiModSts "";
BA_ "sigConfig"  SG_ 920 ApaSentiModSts "哨兵,TSP";
BA_ "GenMsgCycleTime" BO_ 921 100;
BA_ "VFrameFormat" BO_ 921 14;
BA_ "sigDespEng"  SG_ 921 PasSysSts "需要发出";
BA_ "sigSecLevel"  SG_ 921 PasSysSts "";
BA_ "sigExplanation"  SG_ 921 PasSysSts "tbox";
BA_ "sigSecLevel"  SG_ 921 PasLoSpdAutoSts "";
BA_ "sigDespEng"  SG_ 921 PasSwSts "需要发出";
BA_ "sigSecLevel"  SG_ 921 PasSwSts "";
BA_ "sigSecLevel"  SG_ 921 PasReMLeRegnObjSts "";
BA_ "sigSecLevel"  SG_ 921 PasReLeRegnObjSts "";
BA_ "sigSecLevel"  SG_ 921 PasFrntLeRegnObjSts "";
BA_ "sigSecLevel"  SG_ 921 PasReRiRegnObjSts "";
BA_ "sigSecLevel"  SG_ 921 PasFrntRiRegnObjSts "";
BA_ "sigSecLevel"  SG_ 921 PasFrntMLeRegnObjSts "";
BA_ "GenSigStartValue" SG_ 921 ReMinPasDst 255;
BA_ "sigSecLevel"  SG_ 921 ReMinPasDst "";
BA_ "GenSigStartValue" SG_ 921 FrntMinPasDst 255;
BA_ "sigSecLevel"  SG_ 921 FrntMinPasDst "";
BA_ "sigSecLevel"  SG_ 921 PasReMRiRegnObjSts "";
BA_ "sigSecLevel"  SG_ 921 PasHumResp "";
BA_ "sigSecLevel"  SG_ 921 PasFrntMRiRegnObjSts "";
BA_ "GenMsgCycleTime" BO_ 1517 2000;
BA_ "VFrameFormat" BO_ 1517 14;
BA_ "sigSecLevel"  SG_ 1517 DtcHighByte "";
BA_ "sigSecLevel"  SG_ 1517 DtcMiddleByte "";
BA_ "sigSecLevel"  SG_ 1517 DctLowByte "";
BA_ "sigSecLevel"  SG_ 1517 DtcStatus "";
BA_ "GenMsgCycleTime" BO_ 442 20;
BA_ "VFrameFormat" BO_ 442 14;
BA_ "sigSecLevel"  SG_ 442 ApaParkModSet "";
BA_ "sigSecLevel"  SG_ 442 ApaSwt "";
BA_ "sigConfig"  SG_ 442 ApaSwt "tsp";
BA_ "sigSecLevel"  SG_ 442 ApaParkInSlotSet "";
BA_ "sigSecLevel"  SG_ 442 ApaParkOutDirSet "";
BA_ "sigSecLevel"  SG_ 442 ApaTragParkSwt "";
BA_ "sigSecLevel"  SG_ 442 ApaVoicBrdtSwt "";
BA_ "sigSecLevel"  SG_ 442 ApaParkStrtSet "";
BA_ "sigSecLevel"  SG_ 442 ApaPathSet "";
BA_ "sigSecLevel"  SG_ 442 SlotAutoSearchSwt "";
BA_ "sigSecLevel"  SG_ 442 ApaModSet "";
BA_ "sigSecLevel"  SG_ 442 ApaDispSwt "";
BA_ "sigSecLevel"  SG_ 442 RpaDstSet "";
BA_ "sigSecLevel"  SG_ 442 ApaTouchScrnCmd "";
BA_ "sigSecLevel"  SG_ 442 ScrnCoordX "";
BA_ "sigSecLevel"  SG_ 442 ScrnCoordY "";
BA_ "GenMsgCycleTime" BO_ 504 20;
BA_ "VFrameFormat" BO_ 504 14;
BA_ "sigSecLevel"  SG_ 504 BleRpa1Chks "";
BA_ "sigSecLevel"  SG_ 504 BleRpa1Cntr "";
BA_ "sigSecLevel"  SG_ 504 BleDrvrMtnIndcn "";
BA_ "sigSecLevel"  SG_ 504 BleRpaStrtFlg "";
BA_ "sigSecLevel"  SG_ 504 BlePrkgInTypReq "";
BA_ "sigSecLevel"  SG_ 504 BleBluStsFlg "";
BA_ "sigSecLevel"  SG_ 504 BleRpaOnFlg "";
BA_ "sigSecLevel"  SG_ 504 BleParkAbortReq "";
BA_ "sigSecLevel"  SG_ 504 BleParkAuthentStrtReq "";
BA_ "sigSecLevel"  SG_ 504 BleLastStep "";
BA_ "sigSecLevel"  SG_ 504 BleNextStep "";
BA_ "sigSecLevel"  SG_ 504 BleParkoutModSel "";
BA_ "sigSecLevel"  SG_ 504 BleBdcRpaModReq "";
BA_ "GenMsgCycleTime" BO_ 822 100;
BA_ "VFrameFormat" BO_ 822 14;
BA_ "sigSecLevel"  SG_ 822 BleStrtEng "";
BA_ "sigSecLevel"  SG_ 822 BleBtSts "";
BA_ "GenMsgCycleTime" BO_ 823 100;
BA_ "VFrameFormat" BO_ 823 14;
BA_ "sigSecLevel"  SG_ 823 BleSysSts "";
BA_ "GenMsgCycleTime" BO_ 443 100;
BA_ "VFrameFormat" BO_ 443 14;
BA_ "sigSecLevel"  SG_ 443 HumNaviCtryCod "";
BA_ "sigExplanation"  SG_ 443 HumNaviCtryCod "fdca";
BA_ "sigSecLevel"  SG_ 443 HumNaviCtryRoadTyp "";
BA_ "sigExplanation"  SG_ 443 HumNaviCtryRoadTyp "fdca";
BA_ "sigSecLevel"  SG_ 443 ICC_NaviSpdLimit "";
BA_ "sigExplanation"  SG_ 443 ICC_NaviSpdLimit "fdca";
BA_ "sigSecLevel"  SG_ 443 ICC_HDwarning "";
BA_ "sigExplanation"  SG_ 443 ICC_HDwarning "fdca";
BA_ "sigSecLevel"  SG_ 443 HumNaviSpdLimSts "";
BA_ "sigExplanation"  SG_ 443 HumNaviSpdLimSts "fdca";
BA_ "sigSecLevel"  SG_ 443 HU_NavSpeedLimitType "";
BA_ "sigExplanation"  SG_ 443 HU_NavSpeedLimitType "fdca";
BA_ "sigSecLevel"  SG_ 443 HU_RampInfo "";
BA_ "sigExplanation"  SG_ 443 HU_RampInfo "fdca";
BA_ "sigSecLevel"  SG_ 443 HumNaviSpdLimUnit "";
BA_ "sigExplanation"  SG_ 443 HumNaviSpdLimUnit "fdca";
BA_ "sigSecLevel"  SG_ 443 ICC_HD_TsrSignMisc "";
BA_ "sigExplanation"  SG_ 443 ICC_HD_TsrSignMisc "fdca";
BA_ "sigSecLevel"  SG_ 443 HU_RampSpdLim "";
BA_ "sigExplanation"  SG_ 443 HU_RampSpdLim "fdca";
BA_ "sigSecLevel"  SG_ 443 ApaSlotSet "";
BA_ "sigExplanation"  SG_ 443 ApaSlotSet "fdca，apa";
BA_ "sigDespEng"  SG_ 443 ICC_ApaExamStatus "辅助驾驶学习考试是否通过";
BA_ "sigSecLevel"  SG_ 443 ICC_ApaExamStatus "";
BA_ "sigConfig"  SG_ 443 ICC_ApaExamStatus "B81";
BA_ "sigSecLevel"  SG_ 443 ICC_AdasExamStatus "";
BA_ "sigConfig"  SG_ 443 ICC_AdasExamStatus "B81";
BA_ "GenMsgCycleTime" BO_ 537 100;
BA_ "VFrameFormat" BO_ 537 14;
BA_ "sigSecLevel"  SG_ 537 IPC8_F_VehicleSpeedIndi "";
BA_ "sigDespEng"  SG_ 537 IPC8_IcmDispSpdUnitTyp "新增";
BA_ "sigSecLevel"  SG_ 537 IPC8_IcmDispSpdUnitTyp "";
BA_ "sigExplanation"  SG_ 537 IPC8_IcmDispSpdUnitTyp "fdca";
BA_ "sigSecLevel"  SG_ 537 IPC8_N_VehicleSpeedIndi "";
BA_ "sigExplanation"  SG_ 537 IPC8_N_VehicleSpeedIndi "APA";
BA_ "sigDespEng"  SG_ 537 IPC8_AccFailFb "新增";
BA_ "sigSecLevel"  SG_ 537 IPC8_AccFailFb "";
BA_ "sigExplanation"  SG_ 537 IPC8_AccFailFb "fdca";
BA_ "sigDespEng"  SG_ 537 IPC8_IcmDispFail "新增";
BA_ "sigSecLevel"  SG_ 537 IPC8_IcmDispFail "";
BA_ "sigExplanation"  SG_ 537 IPC8_IcmDispFail "fdca";
BA_ "GenMsgCycleTime" BO_ 858 100;
BA_ "VFrameFormat" BO_ 858 14;
BA_ "sigSecLevel"  SG_ 858 BCM12_St_VehicleMode "";
BA_ "sigConfig"  SG_ 858 BCM12_St_VehicleMode "车辆模式,TSP";
BA_ "sigExplanation"  SG_ 858 BCM12_St_VehicleMode "CGW，AC，PWC，APA，ADAS，PDCU, cdc,DSM, SWH，wcbs";
BA_ "GenMsgCycleTime" BO_ 529 100;
BA_ "VFrameFormat" BO_ 529 14;
BA_ "sigDespEng"  SG_ 529 TIM1_St_TIMSt "带电源的拖挂模式";
BA_ "sigSecLevel"  SG_ 529 TIM1_St_TIMSt "";
BA_ "sigExplanation"  SG_ 529 TIM1_St_TIMSt "BDC, CDC, APA, FDCA, CMWR，ADAS";
BA_ "sigSecLevel"  SG_ 529 TIM1_St_TrailerLightsFaultSt "";
BA_ "sigExplanation"  SG_ 529 TIM1_St_TrailerLightsFaultSt "BDC, CDC, APA, FDCA, CMWR, ADAS";
BA_ "sigDespEng"  SG_ 529 TIM1_St_SoftSwMemory "不带电源的拖挂模式";
BA_ "sigSecLevel"  SG_ 529 TIM1_St_SoftSwMemory "";
BA_ "sigExplanation"  SG_ 529 TIM1_St_SoftSwMemory "CDC，APA, FDCA, CMWR, ADAS";
BA_ "sigDespEng"  SG_ 529 TIM1_St_SoftSwMemoryNew "TIM saves ICC Soft Switch State and feedback ICC";
BA_ "sigSecLevel"  SG_ 529 TIM1_St_SoftSwMemoryNew "";
BA_ "sigConfig"  SG_ 529 TIM1_St_SoftSwMemoryNew "B81";
BA_ "sigExplanation"  SG_ 529 TIM1_St_SoftSwMemoryNew "icc，idc,cmrr,mrr";
BA_ "GenMsgCycleTime" BO_ 225 100;
BA_ "GenMsgCycleTimeFast" BO_ 225 20;
BA_ "GenMsgNrOfRepetition" BO_ 225 3;
BA_ "VFrameFormat" BO_ 225 14;
BA_ "GenSigSendType" SG_ 225 EHC12_St_AVMSaleCalibration 1;
BA_ "sigSecLevel"  SG_ 225 EHC12_St_AVMSaleCalibration "";
BA_ "GenSigSendType" SG_ 225 EHC24_ParkingPlaceConfirm 1;
BA_ "sigSecLevel"  SG_ 225 EHC24_ParkingPlaceConfirm "";
BA_ "GenSigSendType" SG_ 225 AvmViewSet 4;
BA_ "sigSecLevel"  SG_ 225 AvmViewSet "";
BA_ "GenSigSendType" SG_ 225 AvmViewModSet 4;
BA_ "sigSecLevel"  SG_ 225 AvmViewModSet "";
BA_ "GenSigSendType" SG_ 225 OvlyDispSwt 4;
BA_ "sigSecLevel"  SG_ 225 OvlyDispSwt "";
BA_ "GenSigSendType" SG_ 225 ObstclViewSwt 4;
BA_ "sigSecLevel"  SG_ 225 ObstclViewSwt "";
BA_ "GenSigSendType" SG_ 225 AvmTrigByObstclSwt 4;
BA_ "sigSecLevel"  SG_ 225 AvmTrigByObstclSwt "";
BA_ "GenSigSendType" SG_ 225 AvmSwt 4;
BA_ "sigSecLevel"  SG_ 225 AvmSwt "";
BA_ "sigConfig"  SG_ 225 AvmSwt "tsp";
BA_ "GenSigSendType" SG_ 225 PasSwt 4;
BA_ "sigSecLevel"  SG_ 225 PasSwt "";
BA_ "GenSigSendType" SG_ 225 EHC24_ExitButton 1;
BA_ "sigSecLevel"  SG_ 225 EHC24_ExitButton "";
BA_ "GenSigSendType" SG_ 225 EHC12_Set_RestoreSetting 1;
BA_ "sigSecLevel"  SG_ 225 EHC12_Set_RestoreSetting "";
BA_ "GenSigSendType" SG_ 225 AvmVehLctSet 4;
BA_ "sigSecLevel"  SG_ 225 AvmVehLctSet "";
BA_ "GenSigSendType" SG_ 225 EHC24_AVM_WormMode_Set 1;
BA_ "sigSecLevel"  SG_ 225 EHC24_AVM_WormMode_Set "";
BA_ "GenSigSendType" SG_ 225 EHCV24_AVM_RockMode_Set 1;
BA_ "sigSecLevel"  SG_ 225 EHCV24_AVM_RockMode_Set "";
BA_ "GenSigSendType" SG_ 225 AvmChasLctSet 4;
BA_ "sigSecLevel"  SG_ 225 AvmChasLctSet "";
BA_ "GenSigSendType" SG_ 225 AvmRoadCalSwt 4;
BA_ "sigSecLevel"  SG_ 225 AvmRoadCalSwt "";
BA_ "GenSigSendType" SG_ 225 EHC12_St_SoftwareUpdate 1;
BA_ "sigSecLevel"  SG_ 225 EHC12_St_SoftwareUpdate "";
BA_ "GenSigSendType" SG_ 225 EHC12_St_AVMRoadCalibration 1;
BA_ "sigSecLevel"  SG_ 225 EHC12_St_AVMRoadCalibration "";
BA_ "GenSigSendType" SG_ 225 EHC12_St_AVMFactoryCalibration 1;
BA_ "sigSecLevel"  SG_ 225 EHC12_St_AVMFactoryCalibration "";
BA_ "GenMsgSendType" BO_ 237 1;
BA_ "GenMsgCycleTimeFast" BO_ 237 20;
BA_ "GenMsgNrOfRepetition" BO_ 237 3;
BA_ "VFrameFormat" BO_ 237 14;
BA_ "GenSigSendType" SG_ 237 EHC22_NOA_ALCRequest_confirm 1;
BA_ "sigSecLevel"  SG_ 237 EHC22_NOA_ALCRequest_confirm "";
BA_ "GenSigSendType" SG_ 237 EHC22_NOA_ALC_TYPE 1;
BA_ "sigSecLevel"  SG_ 237 EHC22_NOA_ALC_TYPE "";
BA_ "GenSigSendType" SG_ 237 EHC22_NOA_ALC_soundnotification 1;
BA_ "sigSecLevel"  SG_ 237 EHC22_NOA_ALC_soundnotification "";
BA_ "GenSigSendType" SG_ 237 EHC22_HWA_EnbSw 1;
BA_ "sigSecLevel"  SG_ 237 EHC22_HWA_EnbSw "";
BA_ "GenSigSendType" SG_ 237 EHC22_TJA_ICA_EnbSw 1;
BA_ "sigSecLevel"  SG_ 237 EHC22_TJA_ICA_EnbSw "";
BA_ "GenSigSendType" SG_ 237 EHC22_IntelligentCornering_EnbSw 1;
BA_ "sigSecLevel"  SG_ 237 EHC22_IntelligentCornering_EnbSw "";
BA_ "GenSigSendType" SG_ 237 EHC22_ESS_EnbSw 1;
BA_ "sigSecLevel"  SG_ 237 EHC22_ESS_EnbSw "";
BA_ "GenSigSendType" SG_ 237 EHC22_LKA_EnbSw 1;
BA_ "sigSecLevel"  SG_ 237 EHC22_LKA_EnbSw "";
BA_ "GenSigSendType" SG_ 237 EHC22_LDW_EnbSw 1;
BA_ "sigSecLevel"  SG_ 237 EHC22_LDW_EnbSw "";
BA_ "GenSigSendType" SG_ 237 EHC22_BSD_LCA_EnbSw 1;
BA_ "sigSecLevel"  SG_ 237 EHC22_BSD_LCA_EnbSw "";
BA_ "GenSigSendType" SG_ 237 EHC22_DOW_EnbSw 1;
BA_ "sigSecLevel"  SG_ 237 EHC22_DOW_EnbSw "";
BA_ "GenSigSendType" SG_ 237 EHC22_ELK_EnbSw 1;
BA_ "sigSecLevel"  SG_ 237 EHC22_ELK_EnbSw "";
BA_ "GenSigSendType" SG_ 237 EHC22_AVM_EnbSw 1;
BA_ "sigSecLevel"  SG_ 237 EHC22_AVM_EnbSw "";
BA_ "GenSigSendType" SG_ 237 EHC22_HMA_EnbSw 1;
BA_ "sigSecLevel"  SG_ 237 EHC22_HMA_EnbSw "";
BA_ "GenSigSendType" SG_ 237 EHC22_BAV_EnbSw 1;
BA_ "sigSecLevel"  SG_ 237 EHC22_BAV_EnbSw "";
BA_ "GenSigSendType" SG_ 237 EHC22_LCK_EnbSw 1;
BA_ "sigSecLevel"  SG_ 237 EHC22_LCK_EnbSw "";
BA_ "GenSigSendType" SG_ 237 EHC22_ASLSw 1;
BA_ "sigSecLevel"  SG_ 237 EHC22_ASLSw "";
BA_ "GenSigSendType" SG_ 237 EHC22_Set_FcwSwt 1;
BA_ "sigSecLevel"  SG_ 237 EHC22_Set_FcwSwt "";
BA_ "GenSigSendType" SG_ 237 EHC22_Set_FCTA 1;
BA_ "sigSecLevel"  SG_ 237 EHC22_Set_FCTA "";
BA_ "GenSigSendType" SG_ 237 EHC22_Set_FCTB 1;
BA_ "sigSecLevel"  SG_ 237 EHC22_Set_FCTB "";
BA_ "GenSigSendType" SG_ 237 EHC22_Set_LDWLKALCKSen 1;
BA_ "sigSecLevel"  SG_ 237 EHC22_Set_LDWLKALCKSen "";
BA_ "GenSigSendType" SG_ 237 EHC22_Sw_LDWLKALCK 1;
BA_ "sigSecLevel"  SG_ 237 EHC22_Sw_LDWLKALCK "";
BA_ "GenSigSendType" SG_ 237 EHC22_St_LDWLKALCKSet 1;
BA_ "sigSecLevel"  SG_ 237 EHC22_St_LDWLKALCKSet "";
BA_ "GenSigSendType" SG_ 237 EHC22_NOAFct_EnbSw 1;
BA_ "sigSecLevel"  SG_ 237 EHC22_NOAFct_EnbSw "";
BA_ "GenSigSendType" SG_ 237 EHC22_SDA_EnbSw 1;
BA_ "sigSecLevel"  SG_ 237 EHC22_SDA_EnbSw "";
BA_ "GenSigSendType" SG_ 237 EHC22_Set_JA 1;
BA_ "sigSecLevel"  SG_ 237 EHC22_Set_JA "";
BA_ "GenSigSendType" SG_ 237 EHC22_CDCShowoffset 1;
BA_ "sigSecLevel"  SG_ 237 EHC22_CDCShowoffset "";
BA_ "GenSigSendType" SG_ 237 EHC22_Set_ELKSen 1;
BA_ "sigSecLevel"  SG_ 237 EHC22_Set_ELKSen "";
BA_ "GenMsgCycleTime" BO_ 661 100;
BA_ "VFrameFormat" BO_ 661 14;
BA_ "GenSigStartValue" SG_ 661 HPA_ObjLatDst1 255;
BA_ "sigSecLevel"  SG_ 661 HPA_ObjLatDst1 "";
BA_ "GenSigStartValue" SG_ 661 HPA_ObjLgtDst1 255;
BA_ "sigSecLevel"  SG_ 661 HPA_ObjLgtDst1 "";
BA_ "sigSecLevel"  SG_ 661 HPA_ObjTyp1 "";
BA_ "sigSecLevel"  SG_ 661 HPA_ObjMovmtDir1 "";
BA_ "GenSigStartValue" SG_ 661 HPA_ObjPosnAgl1 1023;
BA_ "sigSecLevel"  SG_ 661 HPA_ObjPosnAgl1 "";
BA_ "GenSigStartValue" SG_ 661 HPA_ObjLatDst2 255;
BA_ "sigSecLevel"  SG_ 661 HPA_ObjLatDst2 "";
BA_ "GenSigStartValue" SG_ 661 HPA_ObjLgtDst2 255;
BA_ "sigSecLevel"  SG_ 661 HPA_ObjLgtDst2 "";
BA_ "sigSecLevel"  SG_ 661 HPA_ObjTyp2 "";
BA_ "sigSecLevel"  SG_ 661 HPA_ObjMovmtDir2 "";
BA_ "GenSigStartValue" SG_ 661 HPA_ObjPosnAgl2 1023;
BA_ "sigSecLevel"  SG_ 661 HPA_ObjPosnAgl2 "";
BA_ "GenSigStartValue" SG_ 661 HPA_ObjLatDst3 255;
BA_ "sigSecLevel"  SG_ 661 HPA_ObjLatDst3 "";
BA_ "GenSigStartValue" SG_ 661 HPA_ObjLgtDst3 255;
BA_ "sigSecLevel"  SG_ 661 HPA_ObjLgtDst3 "";
BA_ "sigSecLevel"  SG_ 661 HPA_ObjTyp3 "";
BA_ "sigSecLevel"  SG_ 661 HPA_ObjMovmtDir3 "";
BA_ "GenSigStartValue" SG_ 661 HPA_ObjPosnAgl3 1023;
BA_ "sigSecLevel"  SG_ 661 HPA_ObjPosnAgl3 "";
BA_ "GenSigStartValue" SG_ 661 HPA_ObjLatDst4 255;
BA_ "sigSecLevel"  SG_ 661 HPA_ObjLatDst4 "";
BA_ "GenSigStartValue" SG_ 661 HPA_ObjLgtDst4 255;
BA_ "sigSecLevel"  SG_ 661 HPA_ObjLgtDst4 "";
BA_ "sigSecLevel"  SG_ 661 HPA_ObjTyp4 "";
BA_ "sigSecLevel"  SG_ 661 HPA_ObjMovmtDir4 "";
BA_ "GenSigStartValue" SG_ 661 HPA_ObjPosnAgl4 1023;
BA_ "sigSecLevel"  SG_ 661 HPA_ObjPosnAgl4 "";
BA_ "GenSigStartValue" SG_ 661 HPA_ObjLatDst5 255;
BA_ "sigSecLevel"  SG_ 661 HPA_ObjLatDst5 "";
BA_ "GenSigStartValue" SG_ 661 HPA_ObjLgtDst5 255;
BA_ "sigSecLevel"  SG_ 661 HPA_ObjLgtDst5 "";
BA_ "sigSecLevel"  SG_ 661 HPA_ObjTyp5 "";
BA_ "sigSecLevel"  SG_ 661 HPA_ObjMovmtDir5 "";
BA_ "GenSigStartValue" SG_ 661 HPA_ObjPosnAgl5 1023;
BA_ "sigSecLevel"  SG_ 661 HPA_ObjPosnAgl5 "";
BA_ "GenSigStartValue" SG_ 661 HPA_ObjLatDst6 255;
BA_ "sigSecLevel"  SG_ 661 HPA_ObjLatDst6 "";
BA_ "GenSigStartValue" SG_ 661 HPA_ObjLgtDst6 255;
BA_ "sigSecLevel"  SG_ 661 HPA_ObjLgtDst6 "";
BA_ "sigSecLevel"  SG_ 661 HPA_ObjTyp6 "";
BA_ "sigSecLevel"  SG_ 661 HPA_ObjMovmtDir6 "";
BA_ "GenSigStartValue" SG_ 661 HPA_ObjPosnAgl6 1023;
BA_ "sigSecLevel"  SG_ 661 HPA_ObjPosnAgl6 "";
BA_ "GenSigStartValue" SG_ 661 HPA_ObjLatDst7 255;
BA_ "sigSecLevel"  SG_ 661 HPA_ObjLatDst7 "";
BA_ "GenSigStartValue" SG_ 661 HPA_ObjLgtDst7 255;
BA_ "sigSecLevel"  SG_ 661 HPA_ObjLgtDst7 "";
BA_ "sigSecLevel"  SG_ 661 HPA_ObjTyp7 "";
BA_ "sigSecLevel"  SG_ 661 HPA_ObjMovmtDir7 "";
BA_ "GenSigStartValue" SG_ 661 HPA_ObjPosnAgl7 1023;
BA_ "sigSecLevel"  SG_ 661 HPA_ObjPosnAgl7 "";
BA_ "GenSigStartValue" SG_ 661 HPA_ObjLatDst8 255;
BA_ "sigSecLevel"  SG_ 661 HPA_ObjLatDst8 "";
BA_ "GenSigStartValue" SG_ 661 HPA_ObjLgtDst8 255;
BA_ "sigSecLevel"  SG_ 661 HPA_ObjLgtDst8 "";
BA_ "sigSecLevel"  SG_ 661 HPA_ObjTyp8 "";
BA_ "sigSecLevel"  SG_ 661 HPA_ObjMovmtDir8 "";
BA_ "GenSigStartValue" SG_ 661 HPA_ObjPosnAgl8 1023;
BA_ "sigSecLevel"  SG_ 661 HPA_ObjPosnAgl8 "";
BA_ "GenSigStartValue" SG_ 661 HPA_ObjLatDst9 255;
BA_ "sigSecLevel"  SG_ 661 HPA_ObjLatDst9 "";
BA_ "GenSigStartValue" SG_ 661 HPA_ObjLgtDst9 255;
BA_ "sigSecLevel"  SG_ 661 HPA_ObjLgtDst9 "";
BA_ "sigSecLevel"  SG_ 661 HPA_ObjTyp9 "";
BA_ "sigSecLevel"  SG_ 661 HPA_ObjMovmtDir9 "";
BA_ "GenSigStartValue" SG_ 661 HPA_ObjPosnAgl9 1023;
BA_ "sigSecLevel"  SG_ 661 HPA_ObjPosnAgl9 "";
BA_ "GenSigStartValue" SG_ 661 HPA_ObjLatDst10 255;
BA_ "sigSecLevel"  SG_ 661 HPA_ObjLatDst10 "";
BA_ "GenSigStartValue" SG_ 661 HPA_ObjLgtDst10 255;
BA_ "sigSecLevel"  SG_ 661 HPA_ObjLgtDst10 "";
BA_ "sigSecLevel"  SG_ 661 HPA_ObjTyp10 "";
BA_ "sigSecLevel"  SG_ 661 HPA_ObjMovmtDir10 "";
BA_ "GenSigStartValue" SG_ 661 HPA_ObjPosnAgl10 1023;
BA_ "sigSecLevel"  SG_ 661 HPA_ObjPosnAgl10 "";
BA_ "GenSigStartValue" SG_ 661 HPA_ObjLatDst11 255;
BA_ "sigSecLevel"  SG_ 661 HPA_ObjLatDst11 "";
BA_ "GenSigStartValue" SG_ 661 HPA_ObjLgtDst11 255;
BA_ "sigSecLevel"  SG_ 661 HPA_ObjLgtDst11 "";
BA_ "sigSecLevel"  SG_ 661 HPA_ObjTyp11 "";
BA_ "sigSecLevel"  SG_ 661 HPA_ObjMovmtDir11 "";
BA_ "GenSigStartValue" SG_ 661 HPA_ObjPosnAgl11 1023;
BA_ "sigSecLevel"  SG_ 661 HPA_ObjPosnAgl11 "";
BA_ "GenSigStartValue" SG_ 661 HPA_ObjLatDst12 255;
BA_ "sigSecLevel"  SG_ 661 HPA_ObjLatDst12 "";
BA_ "GenSigStartValue" SG_ 661 HPA_ObjLgtDst12 255;
BA_ "sigSecLevel"  SG_ 661 HPA_ObjLgtDst12 "";
BA_ "sigSecLevel"  SG_ 661 HPA_ObjTyp12 "";
BA_ "sigSecLevel"  SG_ 661 HPA_ObjMovmtDir12 "";
BA_ "GenSigStartValue" SG_ 661 HPA_ObjPosnAgl12 1023;
BA_ "sigSecLevel"  SG_ 661 HPA_ObjPosnAgl12 "";
BA_ "GenSigStartValue" SG_ 661 PasMinObjSts 255;
BA_ "sigSecLevel"  SG_ 661 PasMinObjSts "";
BA_ "sigSecLevel"  SG_ 661 ApaSlot1_Sts "";
BA_ "sigSecLevel"  SG_ 661 ApaSlot2_Sts "";
BA_ "sigSecLevel"  SG_ 661 ApaSlot3_Sts "";
BA_ "sigSecLevel"  SG_ 661 ApaSlot4_Sts "";
BA_ "sigSecLevel"  SG_ 661 ApaSlot5_Sts "";
BA_ "sigSecLevel"  SG_ 661 ApaSlot6_Sts "";
BA_ "sigSecLevel"  SG_ 661 ApaSlot7_Sts "";
BA_ "sigSecLevel"  SG_ 661 ApaSlot8_Sts "";
BA_ "sigSecLevel"  SG_ 661 ApaSlot9_Sts "";
BA_ "sigSecLevel"  SG_ 661 ApaSlot10_Sts "";
BA_ "sigSecLevel"  SG_ 661 ApaSlot11_Sts "";
BA_ "sigSecLevel"  SG_ 661 ApaSlot12_Sts "";
BA_ "GenMsgCycleTime" BO_ 1408 100;
BA_ "GenMsgCycleTimeFast" BO_ 1408 20;
BA_ "VFrameFormat" BO_ 1408 14;
BA_ "sigSecLevel"  SG_ 1408 CAPE2_St_KeyIN "";
BA_ "GenMsgCycleTime" BO_ 226 100;
BA_ "GenMsgCycleTimeFast" BO_ 226 20;
BA_ "GenMsgNrOfRepetition" BO_ 226 3;
BA_ "VFrameFormat" BO_ 226 14;
BA_ "GenSigSendType" SG_ 226 EHC25_Set_RecoverTracking 1;
BA_ "sigSecLevel"  SG_ 226 EHC25_Set_RecoverTracking "";
BA_ "GenSigSendType" SG_ 226 EHC25_Set_RestoreParking 1;
BA_ "sigSecLevel"  SG_ 226 EHC25_Set_RestoreParking "";
BA_ "sigSecLevel"  SG_ 226 EHC25_FastBackCar_Mode "";
BA_ "sigSecLevel"  SG_ 226 EHC25_Set_ViewSource "";
BA_ "GenSigSendType" SG_ 226 EHC25_Set_AEBOption 1;
BA_ "sigSecLevel"  SG_ 226 EHC25_Set_AEBOption "";
BA_ "sigSecLevel"  SG_ 226 EHC25_OPerTimeOutExit_Set "";
BA_ "GenSigSendType" SG_ 226 EHC25_Set_TLA 1;
BA_ "GenSigStartValue" SG_ 226 EHC25_Set_TLA 2;
BA_ "sigSecLevel"  SG_ 226 EHC25_Set_TLA "";
BA_ "GenSigSendType" SG_ 226 EHC25_Set_SLA 1;
BA_ "GenSigStartValue" SG_ 226 EHC25_Set_SLA 2;
BA_ "sigSecLevel"  SG_ 226 EHC25_Set_SLA "";
BA_ "GenSigSendType" SG_ 226 EHC25_Set_SLAWarn 1;
BA_ "GenSigStartValue" SG_ 226 EHC25_Set_SLAWarn 2;
BA_ "sigSecLevel"  SG_ 226 EHC25_Set_SLAWarn "";
BA_ "GenSigSendType" SG_ 226 EH25_Set_SLASpdLimOffs 1;
BA_ "sigSecLevel"  SG_ 226 EH25_Set_SLASpdLimOffs "";
BA_ "GenSigSendType" SG_ 226 EHC25_Set_ASL 1;
BA_ "GenSigStartValue" SG_ 226 EHC25_Set_ASL 2;
BA_ "sigSecLevel"  SG_ 226 EHC25_Set_ASL "";
BA_ "GenSigSendType" SG_ 226 EHC25_MODFunction_Set 1;
BA_ "sigSecLevel"  SG_ 226 EHC25_MODFunction_Set "";
BA_ "sigSecLevel"  SG_ 226 EHC25_Set_Color "";
BA_ "GenMsgCycleTime" BO_ 444 100;
BA_ "VFrameFormat" BO_ 444 14;
BA_ "sigSecLevel"  SG_ 444 ICC_N_SlotAngle "";
BA_ "sigSecLevel"  SG_ 444 ICC_N_CoorA_X "";
BA_ "sigSecLevel"  SG_ 444 ICC_ATSMode "";
BA_ "sigExplanation"  SG_ 444 ICC_ATSMode "apa";
BA_ "sigSecLevel"  SG_ 444 ICC_N_CoorA_Y "";
BA_ "sigSecLevel"  SG_ 444 ICC_ScrnAngle "";
BA_ "sigSecLevel"  SG_ 444 ICCAdasApaSocOffSwt "";
BA_ "sigConfig"  SG_ 444 ICCAdasApaSocOffSwt "B81";
BA_ "sigDespEng"  SG_ 444 ICC_AvapViewSource "车机界面状态信号反馈";
BA_ "sigSecLevel"  SG_ 444 ICC_AvapViewSource "";
BA_ "sigConfig"  SG_ 444 ICC_AvapViewSource "B81";
BA_ "sigSecLevel"  SG_ 444 ICC_AvapSysSts "";
BA_ "sigConfig"  SG_ 444 ICC_AvapSysSts "B81";
BA_ "sigSecLevel"  SG_ 444 ICCAvmCalibrationParameter "";
BA_ "sigConfig"  SG_ 444 ICCAvmCalibrationParameter "B81";
BA_ "sigSecLevel"  SG_ 444 ICCApaCalibrationReq "";
BA_ "sigConfig"  SG_ 444 ICCApaCalibrationReq "B81";
BA_ "NmMessage" BO_ 1099 1;
BA_ "GenMsgCycleTime" BO_ 1099 500;
BA_ "CANFD_BRS" BO_ 1099 0;
BA_ "sigSecLevel"  SG_ 1099 IDC_44B_NM_SrcAdr "";
BA_ "sigSecLevel"  SG_ 1099 IDC_44B_NM_Repeat "";
BA_ "sigSecLevel"  SG_ 1099 IDC_44B_NM_ActvWakeup "";
BA_ "sigSecLevel"  SG_ 1099 IDC_44B_NM_Wus "";
BA_ "sigSecLevel"  SG_ 1099 IDC_44B_NM_NMSts "";
BA_ "DiagState" BO_ 1804 1;
BA_ "DiagResponse" BO_ 1804 1;
BA_ "GenMsgSendType" BO_ 1804 1;
BA_ "VFrameFormat" BO_ 1804 14;
BA_ "DiagState" BO_ 1932 1;
BA_ "DiagResponse" BO_ 1932 1;
BA_ "GenMsgSendType" BO_ 1932 1;
BA_ "VFrameFormat" BO_ 1932 14;
BA_ "GenMsgCycleTime" BO_ 648 50;
BA_ "GenMsgCycleTimeFast" BO_ 648 20;
BA_ "GenMsgNrOfRepetition" BO_ 648 3;
BA_ "VFrameFormat" BO_ 648 14;
BA_ "GenSigSendType" SG_ 648 SWS_Cruise 4;
BA_ "sigSecLevel"  SG_ 648 SWS_Cruise "";
BA_ "GenSigSendType" SG_ 648 SWS_360 4;
BA_ "sigSecLevel"  SG_ 648 SWS_360 "";
BA_ "GenSigSendType" SG_ 648 SWS_AccTiGapPlus 4;
BA_ "sigSecLevel"  SG_ 648 SWS_AccTiGapPlus "";
BA_ "GenSigSendType" SG_ 648 SWS_AccTiGapMinus 4;
BA_ "sigSecLevel"  SG_ 648 SWS_AccTiGapMinus "";
BA_ "GenSigSendType" SG_ 648 SWS_LeRollUp 4;
BA_ "sigSecLevel"  SG_ 648 SWS_LeRollUp "";
BA_ "GenSigSendType" SG_ 648 SWS_LeRollDwn 4;
BA_ "sigSecLevel"  SG_ 648 SWS_LeRollDwn "";
BA_ "GenMsgCycleTime" BO_ 309 10;
BA_ "VFrameFormat" BO_ 309 14;
BA_ "sigSecLevel"  SG_ 309 ADC_APA1Chks "";
BA_ "sigSecLevel"  SG_ 309 ADC_APA1Cntr "";
BA_ "sigDespEng"  SG_ 309 APA_FuncMode "表征是激活的APA，还是RPA,MRA,HPA子功能";
BA_ "sigSecLevel"  SG_ 309 APA_FuncMode "";
BA_ "sigDespEng"  SG_ 309 APA_TqReqFlg "当有请扭请求时发0x1，没有请求时发0x0";
BA_ "sigSecLevel"  SG_ 309 APA_TqReqFlg "";
BA_ "sigDespEng"  SG_ 309 APA_LgtMtnCtrReq "表征APA是否对PBM和PDCU有控制需求";
BA_ "sigSecLevel"  SG_ 309 APA_LgtMtnCtrReq "";
BA_ "sigDespEng"  SG_ 309 APA_TqReqVld "请求扭矩大小的有效位";
BA_ "sigSecLevel"  SG_ 309 APA_TqReqVld "";
BA_ "sigDespEng"  SG_ 309 APA_RdyReqVld "泊车时会一直请求保持Ready";
BA_ "sigSecLevel"  SG_ 309 APA_RdyReqVld "";
BA_ "sigDespEng"  SG_ 309 APA_TqReq "请求的扭矩大小";
BA_ "sigSecLevel"  SG_ 309 APA_TqReq "";
BA_ "sigDespEng"  SG_ 309 APA_RdyReq "泊车时会一直请求保持Ready";
BA_ "sigSecLevel"  SG_ 309 APA_RdyReq "";
BA_ "sigDespEng"  SG_ 309 APA_GearCtrlEnable "有换挡需求时的， 换挡使能信号";
BA_ "sigSecLevel"  SG_ 309 APA_GearCtrlEnable "";
BA_ "sigDespEng"  SG_ 309 APA_TarGearReq "有换挡需求时的， 具体的目标档位信号";
BA_ "sigSecLevel"  SG_ 309 APA_TarGearReq "";
BA_ "sigDespEng"  SG_ 309 APA_TarGearReqVld "有换挡需求时的， 具体的目标档位信号的有效性";
BA_ "sigSecLevel"  SG_ 309 APA_TarGearReqVld "";
BA_ "sigDespEng"  SG_ 309 APA_AxReqEnable "当APA有制动请求时， 会给PBM发送减速度使能";
BA_ "sigSecLevel"  SG_ 309 APA_AxReqEnable "";
BA_ "sigDespEng"  SG_ 309 APA_AxReqVld "当APA有制动请求时， 会给PBM发送减速度大小有效位";
BA_ "sigSecLevel"  SG_ 309 APA_AxReqVld "";
BA_ "GenSigStartValue" SG_ 309 APA_AxReq 10000;
BA_ "sigDespEng"  SG_ 309 APA_AxReq "当APA有制动请求时， 会给PBM发送减速度大小有效位";
BA_ "sigSecLevel"  SG_ 309 APA_AxReq "";
BA_ "sigSecLevel"  SG_ 309 ADC_APA2Chks "";
BA_ "sigSecLevel"  SG_ 309 ADC_APA2Cntr "";
BA_ "sigDespEng"  SG_ 309 APA_SysFailSts "APA系统的故障信号，关联系统可参考此信号做DTC或降级";
BA_ "sigSecLevel"  SG_ 309 APA_SysFailSts "";
BA_ "sigDespEng"  SG_ 309 APA_DrvOffReq "当APA有起步需求时，会发送信号";
BA_ "sigSecLevel"  SG_ 309 APA_DrvOffReq "";
BA_ "sigDespEng"  SG_ 309 APA_VehStandstillReq "当APA有停车需求时，会发送信号";
BA_ "sigSecLevel"  SG_ 309 APA_VehStandstillReq "";
BA_ "sigDespEng"  SG_ 309 APA_CtrlEPBAux "当RPA有请求EPB拉起或释放时，会释放此信号";
BA_ "sigSecLevel"  SG_ 309 APA_CtrlEPBAux "";
BA_ "sigDespEng"  SG_ 309 APA_ControlEPB "当APA有请求EPB拉起或释放时，会释放此信号";
BA_ "sigSecLevel"  SG_ 309 APA_ControlEPB "";
BA_ "sigDespEng"  SG_ 309 APA_MEBTarAReq "当MEB功能激活时，会发出此信号，表示使能";
BA_ "sigSecLevel"  SG_ 309 APA_MEBTarAReq "";
BA_ "sigDespEng"  SG_ 309 APA_MEBTarAVld "当MEB功能激活时，会发出此信号，表示加减速度大小有效性";
BA_ "sigSecLevel"  SG_ 309 APA_MEBTarAVld "";
BA_ "sigDespEng"  SG_ 309 APA_MEBTarA "当MEB功能激活时，会发出此信号，表示加减速度大小";
BA_ "sigSecLevel"  SG_ 309 APA_MEBTarA "";
BA_ "sigDespEng"  SG_ 309 APA_PreFillReq "当APA有减速度请求时，会发出Prefill请求";
BA_ "sigSecLevel"  SG_ 309 APA_PreFillReq "";
BA_ "sigDespEng"  SG_ 309 APA_FuncMode_EPS "当APA想控制方向盘时发送此信号，APA不同的激活模式";
BA_ "sigSecLevel"  SG_ 309 APA_FuncMode_EPS "";
BA_ "sigDespEng"  SG_ 309 APA_BrkReqType "APA的制动分舒适制动和紧急制动，底盘可参考此信号做相关制动逻辑";
BA_ "sigSecLevel"  SG_ 309 APA_BrkReqType "";
BA_ "sigDespEng"  SG_ 309 APA_StrWhlAgReqActv "当APA想控制方向盘时发送此信号，使能位";
BA_ "sigSecLevel"  SG_ 309 APA_StrWhlAgReqActv "";
BA_ "sigDespEng"  SG_ 309 APA_DstToStop "APA轨迹规划上剩余的刹停距离，底盘可参考此信号做相关策略";
BA_ "sigSecLevel"  SG_ 309 APA_DstToStop "";
BA_ "sigSecLevel"  SG_ 309 ADC_APA3Chks "";
BA_ "sigSecLevel"  SG_ 309 ADC_APA3Cntr "";
BA_ "GenSigStartValue" SG_ 309 APA_StrWhlAgReq 12480;
BA_ "sigDespEng"  SG_ 309 APA_StrWhlAgReq "当APA想控制方向盘时发送此信号，APA请求的方向盘角度";
BA_ "sigSecLevel"  SG_ 309 APA_StrWhlAgReq "";
BA_ "sigDespEng"  SG_ 309 APA_StrWhlAgReqVld "当APA想控制方向盘时发送此信号，APA请求的方向盘角度有效位";
BA_ "sigSecLevel"  SG_ 309 APA_StrWhlAgReqVld "";
BA_ "sigDespEng"  SG_ 309 APA_ControlEPBVld "表征APA控制EPB的有效位。";
BA_ "sigSecLevel"  SG_ 309 APA_ControlEPBVld "";
BA_ "GenMsgCycleTime" BO_ 310 10;
BA_ "VFrameFormat" BO_ 310 14;
BA_ "sigSecLevel"  SG_ 310 ADC_ADAS1Chks "";
BA_ "sigSecLevel"  SG_ 310 ADC_ADAS1Cntr "";
BA_ "sigDespEng"  SG_ 310 ADAS_LgtMtnCtrReq "ADAS纵向控制状态，激活或不激活";
BA_ "sigSecLevel"  SG_ 310 ADAS_LgtMtnCtrReq "";
BA_ "sigDespEng"  SG_ 310 ADAS_LgtReqMode "ADAS纵向控制模式";
BA_ "sigSecLevel"  SG_ 310 ADAS_LgtReqMode "";
BA_ "sigDespEng"  SG_ 310 ADAS_TarTqReqEna "ADAS请求扭矩使能位，当有扭矩请求时发送";
BA_ "sigSecLevel"  SG_ 310 ADAS_TarTqReqEna "";
BA_ "sigDespEng"  SG_ 310 ADAS_TarTqReqVld "ADAS请求扭矩使能位，当有扭矩请求时发送扭矩值大小有效位";
BA_ "sigSecLevel"  SG_ 310 ADAS_TarTqReqVld "";
BA_ "sigDespEng"  SG_ 310 ADAS_AMAPRequest "加速度踏板防误踩功能激活使能信号";
BA_ "sigSecLevel"  SG_ 310 ADAS_AMAPRequest "";
BA_ "sigDespEng"  SG_ 310 ADAS_AMAPRequestvld "加速度踏板防误踩功能激活使能信号有效位";
BA_ "sigSecLevel"  SG_ 310 ADAS_AMAPRequestvld "";
BA_ "sigDespEng"  SG_ 310 ADAS_TarTqReq "ADAS请求扭矩使能位，当有扭矩请求时发送扭矩值大小";
BA_ "sigSecLevel"  SG_ 310 ADAS_TarTqReq "";
BA_ "sigDespEng"  SG_ 310 ADAS_GearCtrEnable "ADAS请求换挡使能信号";
BA_ "sigSecLevel"  SG_ 310 ADAS_GearCtrEnable "";
BA_ "sigDespEng"  SG_ 310 ADAS_TarGearReqVld "ADAS请求换挡，目标档位有效位";
BA_ "sigSecLevel"  SG_ 310 ADAS_TarGearReqVld "";
BA_ "sigDespEng"  SG_ 310 ADAS_SysFailSts "表征ADAS系统故障，其它系统可观测做DTC";
BA_ "sigSecLevel"  SG_ 310 ADAS_SysFailSts "";
BA_ "sigDespEng"  SG_ 310 ADAS_TarGearReq "ADAS请求换挡，目标档位";
BA_ "sigSecLevel"  SG_ 310 ADAS_TarGearReq "";
BA_ "sigDespEng"  SG_ 310 ADAS_TarAxReqEna "ADAS有减速度请求时，发送给底盘减速度使能位";
BA_ "sigSecLevel"  SG_ 310 ADAS_TarAxReqEna "";
BA_ "sigDespEng"  SG_ 310 ADAS_TarAxReqVld "ADAS有减速度请求时，发送给底盘减速度大小有效位";
BA_ "sigSecLevel"  SG_ 310 ADAS_TarAxReqVld "";
BA_ "sigDespEng"  SG_ 310 ADAS_DrvOffReq "ADAS起步时，发送此信号";
BA_ "sigSecLevel"  SG_ 310 ADAS_DrvOffReq "";
BA_ "GenSigStartValue" SG_ 310 ADAS_TarAxReq 10000;
BA_ "sigDespEng"  SG_ 310 ADAS_TarAxReq "ADAS有减速度请求时，发送给底盘减速度大小";
BA_ "sigSecLevel"  SG_ 310 ADAS_TarAxReq "";
BA_ "sigSecLevel"  SG_ 310 ADC_ADAS2Chks "";
BA_ "sigSecLevel"  SG_ 310 ADC_ADAS2Cntr "";
BA_ "sigDespEng"  SG_ 310 ADAS_DecelToStopReq "ADAS要刹停时，发送此信号";
BA_ "sigSecLevel"  SG_ 310 ADAS_DecelToStopReq "";
BA_ "sigDespEng"  SG_ 310 ADAS_TarAxUpperjerkLim "ADAS有减速度请求时，发送给底盘减速度大小，变化率上限，可参考";
BA_ "sigSecLevel"  SG_ 310 ADAS_TarAxUpperjerkLim "";
BA_ "sigDespEng"  SG_ 310 ADAS_TarAxLowerjerkLim "ADAS有减速度请求时，发送给底盘减速度大小，变化率下限，可参考";
BA_ "sigSecLevel"  SG_ 310 ADAS_TarAxLowerjerkLim "";
BA_ "sigDespEng"  SG_ 310 ADAS_Req_Prefill "AEB相关功能ABP请求信号";
BA_ "sigSecLevel"  SG_ 310 ADAS_Req_Prefill "";
BA_ "sigDespEng"  SG_ 310 ADAS_Req_ABA "AEB相关功能ABA请求信号";
BA_ "sigSecLevel"  SG_ 310 ADAS_Req_ABA "";
BA_ "sigDespEng"  SG_ 310 ADAS_Lvl_ABA "AEB相关功能ABA请求等级";
BA_ "sigSecLevel"  SG_ 310 ADAS_Lvl_ABA "";
BA_ "sigDespEng"  SG_ 310 ADAS_Req_AWB "AEB相关功能AWB请求信号";
BA_ "sigSecLevel"  SG_ 310 ADAS_Req_AWB "";
BA_ "sigDespEng"  SG_ 310 ADAS_Lvl_AWB "AEB相关功能AWB请求等级";
BA_ "sigSecLevel"  SG_ 310 ADAS_Lvl_AWB "";
BA_ "sigDespEng"  SG_ 310 ADAS_TarAReq_AEB "AEB相关功能AEB请求信号";
BA_ "sigSecLevel"  SG_ 310 ADAS_TarAReq_AEB "";
BA_ "sigDespEng"  SG_ 310 ADAS_Decel_AEB "AEB相关功能AEB请求减速度";
BA_ "sigSecLevel"  SG_ 310 ADAS_Decel_AEB "";
BA_ "sigDespEng"  SG_ 310 ADAS_DecelTyp_AEB "AEB相关功能AEB请求类型";
BA_ "sigSecLevel"  SG_ 310 ADAS_DecelTyp_AEB "";
BA_ "sigDespEng"  SG_ 310 ADAS_DecelVld_AEB "AEB相关功能AEB请求减速度有效位";
BA_ "sigSecLevel"  SG_ 310 ADAS_DecelVld_AEB "";
BA_ "sigDespEng"  SG_ 310 ADAS_Req_EPB "AEB相关功能EPB请求拉起";
BA_ "sigSecLevel"  SG_ 310 ADAS_Req_EPB "";
BA_ "sigDespEng"  SG_ 310 ADAS_LatMtnCtrlSts "ADAS横向控制状态，激活或不激活";
BA_ "sigSecLevel"  SG_ 310 ADAS_LatMtnCtrlSts "";
BA_ "sigSecLevel"  SG_ 310 ADC_ADAS3Chks "";
BA_ "sigSecLevel"  SG_ 310 ADC_ADAS3Cntr "";
BA_ "sigDespEng"  SG_ 310 ADAS_LatFuncMode "ADAS横向控制模式";
BA_ "sigSecLevel"  SG_ 310 ADAS_LatFuncMode "";
BA_ "sigDespEng"  SG_ 310 ADAS_PinionAgReqVld "ADAS横向控制下， 发送的方向盘转角有效位";
BA_ "sigSecLevel"  SG_ 310 ADAS_PinionAgReqVld "";
BA_ "sigDespEng"  SG_ 310 ADAS_PinionAgReq "ADAS横向控制下， 发送的方向盘转角";
BA_ "sigSecLevel"  SG_ 310 ADAS_PinionAgReq "";
BA_ "sigDespEng"  SG_ 310 ADAS_SteerAgDrvk "ADAS横向控制模式下，人驾共驾的比例值";
BA_ "sigSecLevel"  SG_ 310 ADAS_SteerAgDrvk "";
BA_ "GenSigStartValue" SG_ 310 ADAS_ExtMaxRPCTrq 1023;
BA_ "sigDespEng"  SG_ 310 ADAS_ExtMaxRPCTrq "ADAS横向控制模式下，人驾共驾时，EPS可执行的最大扭矩限值的上限值";
BA_ "sigSecLevel"  SG_ 310 ADAS_ExtMaxRPCTrq "";
BA_ "sigSecLevel"  SG_ 310 ADC_ADAS4Chks "";
BA_ "sigSecLevel"  SG_ 310 ADC_ADAS4Cntr "";
BA_ "GenSigStartValue" SG_ 310 ADAS_ExtMinRPCTrq 1023;
BA_ "sigDespEng"  SG_ 310 ADAS_ExtMinRPCTrq "ADAS横向控制模式下，人驾共驾时，EPS可执行的最大扭矩限值的下限值";
BA_ "sigSecLevel"  SG_ 310 ADAS_ExtMinRPCTrq "";
BA_ "sigDespEng"  SG_ 310 ADAS_Req_EPBVld "表征ADAS拉起EPB动作的有效性";
BA_ "sigSecLevel"  SG_ 310 ADAS_Req_EPBVld "";
BA_ "GenSigStartValue" SG_ 310 ADS_DrvTarTq_J6 32768;
BA_ "sigSecLevel"  SG_ 310 ADS_DrvTarTq_J6 "";
BA_ "sigConfig"  SG_ 310 ADS_DrvTarTq_J6 "B81";
BA_ "sigSecLevel"  SG_ 310 ADS_SteerAgCtrlEnaReq_J6 "";
BA_ "sigConfig"  SG_ 310 ADS_SteerAgCtrlEnaReq_J6 "B81";
BA_ "GenMsgCycleTime" BO_ 923 100;
BA_ "VFrameFormat" BO_ 923 14;
BA_ "sigDespEng"  SG_ 923 AVAP_RemViewSts "远程查看及车位推送远程查看功能状态信息(AVAP反馈)";
BA_ "sigSecLevel"  SG_ 923 AVAP_RemViewSts "";
BA_ "sigDespEng"  SG_ 923 AVAP_ViewSwtSts "远程查看及车位推送视角切换状态反馈";
BA_ "sigSecLevel"  SG_ 923 AVAP_ViewSwtSts "";
BA_ "sigDespEng"  SG_ 923 AVAP_MirrReq "远程查看及车位推送请求后视镜折叠展开";
BA_ "sigSecLevel"  SG_ 923 AVAP_MirrReq "";
BA_ "sigDespEng"  SG_ 923 AVAP_ScreenshotReq "远程查看及车位推送请求LVDS传输视频流截图";
BA_ "sigSecLevel"  SG_ 923 AVAP_ScreenshotReq "";
BA_ "sigDespEng"  SG_ 923 AVAP_LOCK_Req "离车即走泊入后，ADCU请求BDC下电、闭锁、升窗";
BA_ "sigSecLevel"  SG_ 923 AVAP_LOCK_Req "";
BA_ "sigSecLevel"  SG_ 923 AVAP_LOCK_ReqVal "";
BA_ "sigSecLevel"  SG_ 923 AVAP_TurnLightReq "";
BA_ "sigDespEng"  SG_ 923 AVAP_Lpa_Sts "LPA功能状态，用于判断完成时执行相关下电闭锁动作";
BA_ "sigSecLevel"  SG_ 923 AVAP_Lpa_Sts "";
BA_ "sigDespEng"  SG_ 923 APA_FuncMode_BDC "表征是激活的APA，还是RPA,MRA,HPA子功能";
BA_ "sigSecLevel"  SG_ 923 APA_FuncMode_BDC "";
BA_ "GenMsgCycleTime" BO_ 924 100;
BA_ "VFrameFormat" BO_ 924 14;
BA_ "sigDespEng"  SG_ 924 ADAS_LowHighBeamReq "ADAS中有智能远近光灯请求时会发送";
BA_ "sigSecLevel"  SG_ 924 ADAS_LowHighBeamReq "";
BA_ "sigDespEng"  SG_ 924 ADC_HAD_CoolfluidReq "HAD冷液需求";
BA_ "sigSecLevel"  SG_ 924 ADC_HAD_CoolfluidReq "";
BA_ "sigDespEng"  SG_ 924 ADAS_WarnReqRi "ADAS中有右侧外后视镜灯报警请求时会发送";
BA_ "sigSecLevel"  SG_ 924 ADAS_WarnReqRi "";
BA_ "sigDespEng"  SG_ 924 ADAS_WarnReqLe "ADAS中有左侧外后视镜灯报警请求时会发送";
BA_ "sigSecLevel"  SG_ 924 ADAS_WarnReqLe "";
BA_ "sigSecLevel"  SG_ 924 ADAS_HornReq "";
BA_ "sigSecLevel"  SG_ 924 ADAS_TurnLightReq "";
BA_ "sigSecLevel"  SG_ 924 ADAS_FrontWasherReq "";
BA_ "sigSecLevel"  SG_ 924 ADAS_FrontWiperReq "";
BA_ "sigDespEng"  SG_ 924 ADC_HAD_CoolingfluidflowRateReq "HAD冷却液流速请求";
BA_ "sigSecLevel"  SG_ 924 ADC_HAD_CoolingfluidflowRateReq "";
BA_ "GenMsgCycleTime" BO_ 311 20;
BA_ "VFrameFormat" BO_ 311 14;
BA_ "sigSecLevel"  SG_ 311 Pdcu0x137Chks1 "";
BA_ "sigConfig"  SG_ 311 Pdcu0x137Chks1 "B41VS J6M";
BA_ "sigExplanation"  SG_ 311 Pdcu0x137Chks1 "ADC";
BA_ "sigSecLevel"  SG_ 311 Pdcu0x137Cntr1 "";
BA_ "sigConfig"  SG_ 311 Pdcu0x137Cntr1 "B41VS J6M";
BA_ "sigExplanation"  SG_ 311 Pdcu0x137Cntr1 "ADC";
BA_ "sigDespEng"  SG_ 311 PDCU_PtTqAvl "VCU扭矩是否支持智能驾驶,当支持时才会激活纵向请求";
BA_ "sigSecLevel"  SG_ 311 PDCU_PtTqAvl "";
BA_ "sigConfig"  SG_ 311 PDCU_PtTqAvl "B41VS J6M";
BA_ "sigExplanation"  SG_ 311 PDCU_PtTqAvl "ADC";
BA_ "sigDespEng"  SG_ 311 PDCU_VehDrvMotMaxElecTqVld "VCU扭矩能够支持智能驾驶最大扭矩有效位";
BA_ "sigSecLevel"  SG_ 311 PDCU_VehDrvMotMaxElecTqVld "";
BA_ "sigConfig"  SG_ 311 PDCU_VehDrvMotMaxElecTqVld "B41VS J6M";
BA_ "sigExplanation"  SG_ 311 PDCU_VehDrvMotMaxElecTqVld "ADC";
BA_ "sigDespEng"  SG_ 311 PDCU_AVAPhandshakeSts "VCU是否响应APA的状态位";
BA_ "sigSecLevel"  SG_ 311 PDCU_AVAPhandshakeSts "";
BA_ "sigConfig"  SG_ 311 PDCU_AVAPhandshakeSts "B41VS J6M";
BA_ "sigExplanation"  SG_ 311 PDCU_AVAPhandshakeSts "ADC";
BA_ "sigDespEng"  SG_ 311 PDCU_GasPedalInhibition "加速踏板误作用反馈信号";
BA_ "sigSecLevel"  SG_ 311 PDCU_GasPedalInhibition "";
BA_ "sigConfig"  SG_ 311 PDCU_GasPedalInhibition "B41VS J6M";
BA_ "sigExplanation"  SG_ 311 PDCU_GasPedalInhibition "ADC";
BA_ "sigDespEng"  SG_ 311 PDCU_AVAPFltFb "VCU退出APA握手的原因信号";
BA_ "sigSecLevel"  SG_ 311 PDCU_AVAPFltFb "";
BA_ "sigConfig"  SG_ 311 PDCU_AVAPFltFb "B41VS J6M";
BA_ "sigExplanation"  SG_ 311 PDCU_AVAPFltFb "ADC";
BA_ "sigDespEng"  SG_ 311 PdcuApaLeverInterventionVld "APA泊车时，当驾驶员操作档位，发出此信号，档位干预状态有效位";
BA_ "sigSecLevel"  SG_ 311 PdcuApaLeverInterventionVld "";
BA_ "sigConfig"  SG_ 311 PdcuApaLeverInterventionVld "B41VS J6M";
BA_ "sigExplanation"  SG_ 311 PdcuApaLeverInterventionVld "ADC";
BA_ "sigDespEng"  SG_ 311 PDCU_LgtReqActiveSts "VCU是否响应ADAS的状态位";
BA_ "sigSecLevel"  SG_ 311 PDCU_LgtReqActiveSts "";
BA_ "sigConfig"  SG_ 311 PDCU_LgtReqActiveSts "B41VS J6M";
BA_ "sigExplanation"  SG_ 311 PDCU_LgtReqActiveSts "ADC";
BA_ "sigDespEng"  SG_ 311 PDCU_VehDrvMotMaxElecTq "VCU扭矩能够支持智能驾驶最大扭矩";
BA_ "sigSecLevel"  SG_ 311 PDCU_VehDrvMotMaxElecTq "";
BA_ "sigConfig"  SG_ 311 PDCU_VehDrvMotMaxElecTq "B41VS J6M";
BA_ "sigExplanation"  SG_ 311 PDCU_VehDrvMotMaxElecTq "ADC";
BA_ "sigDespEng"  SG_ 311 PDCU_ADLCFailureSts "VCU退出ADAS握手的原因信号";
BA_ "sigSecLevel"  SG_ 311 PDCU_ADLCFailureSts "";
BA_ "sigConfig"  SG_ 311 PDCU_ADLCFailureSts "B41VS J6M";
BA_ "sigExplanation"  SG_ 311 PDCU_ADLCFailureSts "ADC";
BA_ "GenMsgCycleTime" BO_ 833 10;
BA_ "VFrameFormat" BO_ 833 14;
BA_ "sigSecLevel"  SG_ 833 WCBS_N_EBRTrqACT "";
BA_ "sigConfig"  SG_ 833 WCBS_N_EBRTrqACT "B60VS";
BA_ "sigExplanation"  SG_ 833 WCBS_N_EBRTrqACT "pdcu";
BA_ "GenMsgCycleTime" BO_ 536 20;
BA_ "VFrameFormat" BO_ 536 14;
BA_ "sigSecLevel"  SG_ 536 WCBS_ESP7_ReLeSnsrFlt "";
BA_ "sigExplanation"  SG_ 536 WCBS_ESP7_ReLeSnsrFlt "EMS";
BA_ "sigSecLevel"  SG_ 536 WCBS_ESP7_ReRiSnsrFlt "";
BA_ "sigExplanation"  SG_ 536 WCBS_ESP7_ReRiSnsrFlt "EMS";
BA_ "sigSecLevel"  SG_ 536 WCBS_ESP7_FrntLeSnsrFlt "";
BA_ "sigExplanation"  SG_ 536 WCBS_ESP7_FrntLeSnsrFlt "EMS";
BA_ "sigSecLevel"  SG_ 536 WCBS_ESP7_FrntRiSnsrFlt "";
BA_ "sigExplanation"  SG_ 536 WCBS_ESP7_FrntRiSnsrFlt "EMS";
BA_ "sigSecLevel"  SG_ 536 WCBS_ESP7_BrakeTorqOn4Wheels "";
BA_ "sigExplanation"  SG_ 536 WCBS_ESP7_BrakeTorqOn4Wheels "pdcu";
BA_ "sigDespEng"  SG_ 536 IBS_VDCInfo "F03华为智驾";
BA_ "sigSecLevel"  SG_ 536 IBS_VDCInfo "";
BA_ "GenMsgCycleTime" BO_ 1583 1000;
BA_ "VFrameFormat" BO_ 1583 14;
BA_ "sigDespEng"  SG_ 1583 TBOX_CrtTi_Day "需要发出";
BA_ "sigSecLevel"  SG_ 1583 TBOX_CrtTi_Day "";
BA_ "sigConfig"  SG_ 1583 TBOX_CrtTi_Day "tsp";
BA_ "sigExplanation"  SG_ 1583 TBOX_CrtTi_Day "PDCU";
BA_ "sigDespEng"  SG_ 1583 TBOX_CrtTi_Hr "需要发出";
BA_ "sigSecLevel"  SG_ 1583 TBOX_CrtTi_Hr "";
BA_ "sigConfig"  SG_ 1583 TBOX_CrtTi_Hr "tsp";
BA_ "sigExplanation"  SG_ 1583 TBOX_CrtTi_Hr "PDCU";
BA_ "sigDespEng"  SG_ 1583 TBOX_CrtTi_Mins "需要发出";
BA_ "sigSecLevel"  SG_ 1583 TBOX_CrtTi_Mins "";
BA_ "sigConfig"  SG_ 1583 TBOX_CrtTi_Mins "tsp";
BA_ "sigExplanation"  SG_ 1583 TBOX_CrtTi_Mins "PDCU";
BA_ "sigDespEng"  SG_ 1583 TBOX_CrtTi_Yr "需要发出";
BA_ "sigSecLevel"  SG_ 1583 TBOX_CrtTi_Yr "";
BA_ "sigConfig"  SG_ 1583 TBOX_CrtTi_Yr "tsp";
BA_ "sigExplanation"  SG_ 1583 TBOX_CrtTi_Yr "PDCU";
BA_ "sigDespEng"  SG_ 1583 TBOX_CrtTi_Mth "需要发出";
BA_ "sigSecLevel"  SG_ 1583 TBOX_CrtTi_Mth "";
BA_ "sigConfig"  SG_ 1583 TBOX_CrtTi_Mth "tsp";
BA_ "sigExplanation"  SG_ 1583 TBOX_CrtTi_Mth "PDCU";
BA_ "sigDespEng"  SG_ 1583 TBOX_CrtTi_Sec "需要发出";
BA_ "sigSecLevel"  SG_ 1583 TBOX_CrtTi_Sec "";
BA_ "sigConfig"  SG_ 1583 TBOX_CrtTi_Sec "tsp";
BA_ "sigExplanation"  SG_ 1583 TBOX_CrtTi_Sec "PDCU";
BA_ "GenMsgCycleTime" BO_ 315 10;
BA_ "VFrameFormat" BO_ 315 14;
BA_ "GenSigStartValue" SG_ 315 EPS_SteerTorqueByADASReq 1023;
BA_ "sigSecLevel"  SG_ 315 EPS_SteerTorqueByADASReq "";
BA_ "sigConfig"  SG_ 315 EPS_SteerTorqueByADASReq "B81";
BA_ "sigSecLevel"  SG_ 315 EPS_SteerTorqueVldByADASReq "";
BA_ "sigConfig"  SG_ 315 EPS_SteerTorqueVldByADASReq "B81";
BA_ "sigSecLevel"  SG_ 315 EPS_SteerSnsrSts "";
BA_ "sigConfig"  SG_ 315 EPS_SteerSnsrSts "B81";
BA_ "sigSecLevel"  SG_ 315 EPS_DrvrSteerTqDir "";
BA_ "sigConfig"  SG_ 315 EPS_DrvrSteerTqDir "B81";
BA_ "sigSecLevel"  SG_ 315 EPS_SteerDrvrOvrd_J6 "";
BA_ "sigConfig"  SG_ 315 EPS_SteerDrvrOvrd_J6 "B81";
BA_ "GenMsgCycleTime" BO_ 410 10;
BA_ "VFrameFormat" BO_ 410 14;
BA_ "sigDespEng"  SG_ 410 Yrs1Chks "E2E";
BA_ "sigSecLevel"  SG_ 410 Yrs1Chks "";
BA_ "sigSecLevel"  SG_ 410 Yrs1Cntr "";
BA_ "GenSigStartValue" SG_ 410 LatAcce 2000;
BA_ "sigSecLevel"  SG_ 410 LatAcce "";
BA_ "GenSigStartValue" SG_ 410 LgtAcce 2000;
BA_ "sigSecLevel"  SG_ 410 LgtAcce "";
BA_ "GenSigStartValue" SG_ 410 YawRate 18000;
BA_ "sigSecLevel"  SG_ 410 YawRate "";
BA_ "sigSecLevel"  SG_ 410 LatSnsrSts "";
BA_ "sigSecLevel"  SG_ 410 LgtSnsrSts "";
BA_ "sigSecLevel"  SG_ 410 YawRateSnsrSts "";
BA_ "sigSecLevel"  SG_ 410 YawRateSnsrCalSts "";
BA_ "GenMsgCycleTime" BO_ 908 100;
BA_ "VFrameFormat" BO_ 908 14;
BA_ "sigDespEng"  SG_ 908 IDC0x38C1Chks "预留";
BA_ "sigSecLevel"  SG_ 908 IDC0x38C1Chks "";
BA_ "sigDespEng"  SG_ 908 IDC0x38C1Cntr "预留";
BA_ "sigSecLevel"  SG_ 908 IDC0x38C1Cntr "";
BA_ "sigDespEng"  SG_ 908 LeftFrontUssSts "车机根据状态提示故障符号";
BA_ "sigSecLevel"  SG_ 908 LeftFrontUssSts "";
BA_ "sigDespEng"  SG_ 908 FrontLeftUssSts "车机根据状态提示故障符号";
BA_ "sigSecLevel"  SG_ 908 FrontLeftUssSts "";
BA_ "sigDespEng"  SG_ 908 FrontLeftCenterUssSts "车机根据状态提示故障符号";
BA_ "sigSecLevel"  SG_ 908 FrontLeftCenterUssSts "";
BA_ "sigDespEng"  SG_ 908 FrontRightCenterUssSts "车机根据状态提示故障符号";
BA_ "sigSecLevel"  SG_ 908 FrontRightCenterUssSts "";
BA_ "sigDespEng"  SG_ 908 FrontRightUssSts "车机根据状态提示故障符号";
BA_ "sigSecLevel"  SG_ 908 FrontRightUssSts "";
BA_ "sigDespEng"  SG_ 908 RightFrontUssSts "车机根据状态提示故障符号";
BA_ "sigSecLevel"  SG_ 908 RightFrontUssSts "";
BA_ "sigDespEng"  SG_ 908 LeftBackUssSts "车机根据状态提示故障符号";
BA_ "sigSecLevel"  SG_ 908 LeftBackUssSts "";
BA_ "sigDespEng"  SG_ 908 BackLeftUssSts "车机根据状态提示故障符号";
BA_ "sigSecLevel"  SG_ 908 BackLeftUssSts "";
BA_ "sigDespEng"  SG_ 908 BackLeftCenterUssSts "车机根据状态提示故障符号";
BA_ "sigSecLevel"  SG_ 908 BackLeftCenterUssSts "";
BA_ "sigDespEng"  SG_ 908 BackRightCenterUssSts "车机根据状态提示故障符号";
BA_ "sigSecLevel"  SG_ 908 BackRightCenterUssSts "";
BA_ "sigDespEng"  SG_ 908 BackRightUssSts "车机根据状态提示故障符号";
BA_ "sigSecLevel"  SG_ 908 BackRightUssSts "";
BA_ "sigDespEng"  SG_ 908 RightBacktUssSts "车机根据状态提示故障符号";
BA_ "sigSecLevel"  SG_ 908 RightBacktUssSts "";
BA_ "sigDespEng"  SG_ 908 IDC0x38C2Chks "预留";
BA_ "sigSecLevel"  SG_ 908 IDC0x38C2Chks "";
BA_ "sigDespEng"  SG_ 908 IDC0x38C2Cntr "预留";
BA_ "sigSecLevel"  SG_ 908 IDC0x38C2Cntr "";
BA_ "sigDespEng"  SG_ 908 PAS_FL_Distance "车机根据状态渲染雷达墙";
BA_ "sigSecLevel"  SG_ 908 PAS_FL_Distance "";
BA_ "sigDespEng"  SG_ 908 PAS_FML_Distance "车机根据状态渲染雷达墙";
BA_ "sigSecLevel"  SG_ 908 PAS_FML_Distance "";
BA_ "sigDespEng"  SG_ 908 PAS_FMR_Distance "车机根据状态渲染雷达墙";
BA_ "sigSecLevel"  SG_ 908 PAS_FMR_Distance "";
BA_ "sigDespEng"  SG_ 908 PAS_FR_Distance "车机根据状态渲染雷达墙";
BA_ "sigSecLevel"  SG_ 908 PAS_FR_Distance "";
BA_ "sigDespEng"  SG_ 908 SDW_LSF1_Distance "车机根据状态渲染雷达墙";
BA_ "sigSecLevel"  SG_ 908 SDW_LSF1_Distance "";
BA_ "sigDespEng"  SG_ 908 SDW_LSF2_Distance "车机根据状态渲染雷达墙";
BA_ "sigSecLevel"  SG_ 908 SDW_LSF2_Distance "";
BA_ "sigDespEng"  SG_ 908 SDW_LSR2_Distance "车机根据状态渲染雷达墙";
BA_ "sigSecLevel"  SG_ 908 SDW_LSR2_Distance "";
BA_ "sigDespEng"  SG_ 908 SDW_LSR1_Distance "车机根据状态渲染雷达墙";
BA_ "sigSecLevel"  SG_ 908 SDW_LSR1_Distance "";
BA_ "sigDespEng"  SG_ 908 SDW_RSF1_Distance "车机根据状态渲染雷达墙";
BA_ "sigSecLevel"  SG_ 908 SDW_RSF1_Distance "";
BA_ "sigDespEng"  SG_ 908 SDW_RSF2_Distance "车机根据状态渲染雷达墙";
BA_ "sigSecLevel"  SG_ 908 SDW_RSF2_Distance "";
BA_ "sigDespEng"  SG_ 908 SDW_RSR2_Distance "车机根据状态渲染雷达墙";
BA_ "sigSecLevel"  SG_ 908 SDW_RSR2_Distance "";
BA_ "sigDespEng"  SG_ 908 SDW_RSR1_Distance "车机根据状态渲染雷达墙";
BA_ "sigSecLevel"  SG_ 908 SDW_RSR1_Distance "";
BA_ "sigDespEng"  SG_ 908 PAS_RL_Distance "车机根据状态渲染雷达墙";
BA_ "sigSecLevel"  SG_ 908 PAS_RL_Distance "";
BA_ "sigDespEng"  SG_ 908 PAS_RML_Distance "车机根据状态渲染雷达墙";
BA_ "sigSecLevel"  SG_ 908 PAS_RML_Distance "";
BA_ "sigDespEng"  SG_ 908 PAS_RMR_Distance "车机根据状态渲染雷达墙";
BA_ "sigSecLevel"  SG_ 908 PAS_RMR_Distance "";
BA_ "sigDespEng"  SG_ 908 PAS_RR_Distance "车机根据状态渲染雷达墙";
BA_ "sigSecLevel"  SG_ 908 PAS_RR_Distance "";
BA_ "sigDespEng"  SG_ 908 IDC0x38C3Chks "预留";
BA_ "sigSecLevel"  SG_ 908 IDC0x38C3Chks "";
BA_ "sigDespEng"  SG_ 908 IDC0x38C3Cntr "预留";
BA_ "sigSecLevel"  SG_ 908 IDC0x38C3Cntr "";
BA_ "sigSecLevel"  SG_ 908 ApaCalibrationParameter "";
BA_ "sigSecLevel"  SG_ 908 ApaFactoryCalibrationSts "";
BA_ "sigSecLevel"  SG_ 908 ApaFactoryCalibFailureRsn "";
BA_ "sigSecLevel"  SG_ 908 ApaAfterSalesCalibrationSts "";
BA_ "sigSecLevel"  SG_ 908 ApaAfterSalesCalibStsProgress "";
BA_ "sigSecLevel"  SG_ 908 ApaAfterSalesCalibFailureRsn "";
VAL_ 659 APASlot_1_source 4 "自定义车位" 3 "融合车位" 2 "视觉车位" 1 "空间车位" 0 "无效" ;
VAL_ 659 APASlot__1_Direction 2 "右方车位" 1 "左方车位" 0 "无效" ;
VAL_ 659 APASlot_2_source 4 "自定义车位" 3 "融合车位" 2 "视觉车位" 1 "空间车位" 0 "无效" ;
VAL_ 659 APASlot_3_source 4 "自定义车位" 3 "融合车位" 2 "视觉车位" 1 "空间车位" 0 "无效" ;
VAL_ 659 APASlot__2_Direction 2 "右方车位" 1 "左方车位" 0 "无效" ;
VAL_ 659 APASlot_4_source 4 "自定义车位" 3 "融合车位" 2 "视觉车位" 1 "空间车位" 0 "无效" ;
VAL_ 659 APASlot_5_source 4 "自定义车位" 3 "融合车位" 2 "视觉车位" 1 "空间车位" 0 "无效" ;
VAL_ 659 APASlot__3_Direction 2 "右方车位" 1 "左方车位" 0 "无效" ;
VAL_ 659 APASlot_6_source 4 "自定义车位" 3 "融合车位" 2 "视觉车位" 1 "空间车位" 0 "无效" ;
VAL_ 659 APASlot_7_source 4 "自定义车位" 3 "融合车位" 2 "视觉车位" 1 "空间车位" 0 "无效" ;
VAL_ 659 APASlot__4_Direction 2 "右方车位" 1 "左方车位" 0 "无效" ;
VAL_ 659 APASlot_8_source 4 "自定义车位" 3 "融合车位" 2 "视觉车位" 1 "空间车位" 0 "无效" ;
VAL_ 659 APASlot_9_source 4 "自定义车位" 3 "融合车位" 2 "视觉车位" 1 "空间车位" 0 "无效" ;
VAL_ 659 APASlot__5_Direction 2 "右方车位" 1 "左方车位" 0 "无效" ;
VAL_ 659 APASlot_10_source 4 "自定义车位" 3 "融合车位" 2 "视觉车位" 1 "空间车位" 0 "无效" ;
VAL_ 659 APASlot_11_source 4 "自定义车位" 3 "融合车位" 2 "视觉车位" 1 "空间车位" 0 "无效" ;
VAL_ 659 APASlot__6_Direction 2 "右方车位" 1 "左方车位" 0 "无效" ;
VAL_ 659 APASlot_12_source 4 "自定义车位" 3 "融合车位" 2 "视觉车位" 1 "空间车位" 0 "无效" ;
VAL_ 659 APASlot__7_Direction 2 "右方车位" 1 "左方车位" 0 "无效" ;
VAL_ 659 APASlot__8_Direction 2 "右方车位" 1 "左方车位" 0 "无效" ;
VAL_ 659 APASlot__9_Direction 2 "右方车位" 1 "左方车位" 0 "无效" ;
VAL_ 659 APASlot__10_Direction 2 "右方车位" 1 "左方车位" 0 "无效" ;
VAL_ 659 APASlot__11_Direction 2 "右方车位" 1 "左方车位" 0 "无效" ;
VAL_ 659 APASlot__12_Direction 2 "右方车位" 1 "左方车位" 0 "无效" ;
VAL_ 659 APASlot__13_Direction 2 "右方车位" 1 "左方车位" 0 "无效" ;
VAL_ 659 APASlot__14_Direction 2 "右方车位" 1 "左方车位" 0 "无效" ;
VAL_ 659 APASlot__1_Type 3 "斜向车位" 2 "垂直车位" 1 "水平车位" 0 "无效" ;
VAL_ 659 APASlot__2_Type 3 "斜向车位" 2 "垂直车位" 1 "水平车位" 0 "无效" ;
VAL_ 659 APASlot__3_Type 3 "斜向车位" 2 "垂直车位" 1 "水平车位" 0 "无效" ;
VAL_ 659 APASlot__4_Type 3 "斜向车位" 2 "垂直车位" 1 "水平车位" 0 "无效" ;
VAL_ 659 APASlot__5_Type 3 "斜向车位" 2 "垂直车位" 1 "水平车位" 0 "无效" ;
VAL_ 659 APASlot__6_Type 3 "斜向车位" 2 "垂直车位" 1 "水平车位" 0 "无效" ;
VAL_ 659 APASlot__7_Type 3 "斜向车位" 2 "垂直车位" 1 "水平车位" 0 "无效" ;
VAL_ 659 APASlot__8_Type 3 "斜向车位" 2 "垂直车位" 1 "水平车位" 0 "无效" ;
VAL_ 659 APASlot__9_Type 3 "斜向车位" 2 "垂直车位" 1 "水平车位" 0 "无效" ;
VAL_ 659 APASlot__10_Type 3 "斜向车位" 2 "垂直车位" 1 "水平车位" 0 "无效" ;
VAL_ 659 APASlot__11_Type 3 "斜向车位" 2 "垂直车位" 1 "水平车位" 0 "无效" ;
VAL_ 659 APASlot__12_Type 3 "斜向车位" 2 "垂直车位" 1 "水平车位" 0 "无效" ;
VAL_ 659 SlotTarg_ID 255 "目标车位ID为 255" 3 "目标车位ID为 3" 2 "目标车位ID为 2" 1 "目标车位ID为 1" 0 "无效" ;
VAL_ 659 Slot1_ID 255 "目标车位ID为 255" 3 "目标车位ID为 3" 2 "目标车位ID为 2" 1 "目标车位ID为 1" 0 "无效" ;
VAL_ 659 Slot2_ID 255 "目标车位ID为 255" 3 "目标车位ID为 3" 2 "目标车位ID为 2" 1 "目标车位ID为 1" 0 "无效" ;
VAL_ 659 Slot3_ID 255 "目标车位ID为 255" 3 "目标车位ID为 3" 2 "目标车位ID为 2" 1 "目标车位ID为 1" 0 "无效" ;
VAL_ 659 Slot4_ID 255 "目标车位ID为 255" 3 "目标车位ID为 3" 2 "目标车位ID为 2" 1 "目标车位ID为 1" 0 "无效" ;
VAL_ 659 Slot5_ID 255 "目标车位ID为 255" 3 "目标车位ID为 3" 2 "目标车位ID为 2" 1 "目标车位ID为 1" 0 "无效" ;
VAL_ 659 Slot6_ID 255 "目标车位ID为 255" 3 "目标车位ID为 3" 2 "目标车位ID为 2" 1 "目标车位ID为 1" 0 "无效" ;
VAL_ 659 Slot7_ID 255 "目标车位ID为 255" 3 "目标车位ID为 3" 2 "目标车位ID为 2" 1 "目标车位ID为 1" 0 "无效" ;
VAL_ 659 Slot8_ID 255 "目标车位ID为 255" 3 "目标车位ID为 3" 2 "目标车位ID为 2" 1 "目标车位ID为 1" 0 "无效" ;
VAL_ 659 Slot9_ID 255 "目标车位ID为 255" 3 "目标车位ID为 3" 2 "目标车位ID为 2" 1 "目标车位ID为 1" 0 "无效" ;
VAL_ 659 Slot10_ID 255 "目标车位ID为 255" 3 "目标车位ID为 3" 2 "目标车位ID为 2" 1 "目标车位ID为 1" 0 "无效" ;
VAL_ 659 Slot11_ID 255 "目标车位ID为 255" 3 "目标车位ID为 3" 2 "目标车位ID为 2" 1 "目标车位ID为 1" 0 "无效" ;
VAL_ 659 Slot12_ID 255 "目标车位ID为 255" 3 "目标车位ID为 3" 2 "目标车位ID为 2" 1 "目标车位ID为 1" 0 "无效" ;
VAL_ 659 SlotTargACoorX 255 "Invalid" ;
VAL_ 659 SlotTargACoorY 255 "Invalid" ;
VAL_ 659 SlotTargBCoorX 255 "Invalid" ;
VAL_ 659 SlotTargBCoorY 255 "Invalid" ;
VAL_ 659 SlotTargCCoorX 255 "Invalid" ;
VAL_ 659 SlotTargCCoorY 255 "Invalid" ;
VAL_ 659 SlotTargDCoorX 255 "Invalid" ;
VAL_ 659 SlotTargDCoorY 255 "Invalid" ;
VAL_ 659 Slot1ACoorX 255 "Invalid" ;
VAL_ 659 Slot1ACoorY 255 "Invalid" ;
VAL_ 659 Slot1BCoorX 255 "Invalid" ;
VAL_ 659 Slot1BCoorY 255 "Invalid" ;
VAL_ 659 Slot1CCoorX 255 "Invalid" ;
VAL_ 659 Slot1CCoorY 255 "Invalid" ;
VAL_ 659 Slot1DCoorX 255 "Invalid" ;
VAL_ 659 Slot1DCoorY 255 "Invalid" ;
VAL_ 659 Slot2ACoorX 255 "Invalid" ;
VAL_ 659 Slot2ACoorY 255 "Invalid" ;
VAL_ 659 Slot2BCoorX 255 "Invalid" ;
VAL_ 659 Slot2BCoorY 255 "Invalid" ;
VAL_ 659 Slot2CCoorX 255 "Invalid" ;
VAL_ 659 Slot2CCoorY 255 "Invalid" ;
VAL_ 659 Slot2DCoorX 255 "Invalid" ;
VAL_ 659 Slot2DCoorY 255 "Invalid" ;
VAL_ 659 Slot3ACoorX 255 "Invalid" ;
VAL_ 659 Slot3ACoorY 255 "Invalid" ;
VAL_ 659 Slot3BCoorX 255 "Invalid" ;
VAL_ 659 Slot3BCoorY 255 "Invalid" ;
VAL_ 659 Slot3CCoorX 255 "Invalid" ;
VAL_ 659 Slot3CCoorY 255 "Invalid" ;
VAL_ 659 Slot3DCoorX 255 "Invalid" ;
VAL_ 659 Slot3DCoorY 255 "Invalid" ;
VAL_ 659 Slot4ACoorX 255 "Invalid" ;
VAL_ 659 Slot4ACoorY 255 "Invalid" ;
VAL_ 659 Slot4BCoorX 255 "Invalid" ;
VAL_ 659 Slot4BCoorY 255 "Invalid" ;
VAL_ 659 Slot4CCoorX 255 "Invalid" ;
VAL_ 659 Slot4CCoorY 255 "Invalid" ;
VAL_ 659 Slot4DCoorX 255 "Invalid" ;
VAL_ 659 Slot4DCoorY 255 "Invalid" ;
VAL_ 660 Slot5ACoorX 255 "Invalid" ;
VAL_ 660 Slot5ACoorY 255 "Invalid" ;
VAL_ 660 Slot5BCoorX 255 "Invalid" ;
VAL_ 660 Slot5BCoorY 255 "Invalid" ;
VAL_ 660 Slot5CCoorX 255 "Invalid" ;
VAL_ 660 Slot5CCoorY 255 "Invalid" ;
VAL_ 660 Slot5DCoorX 255 "Invalid" ;
VAL_ 660 Slot5DCoorY 255 "Invalid" ;
VAL_ 660 Slot6ACoorX 255 "Invalid" ;
VAL_ 660 Slot6ACoorY 255 "Invalid" ;
VAL_ 660 Slot6BCoorX 255 "Invalid" ;
VAL_ 660 Slot6BCoorY 255 "Invalid" ;
VAL_ 660 Slot6CCoorX 255 "Invalid" ;
VAL_ 660 Slot6CCoorY 255 "Invalid" ;
VAL_ 660 Slot6DCoorX 255 "Invalid" ;
VAL_ 660 Slot6DCoorY 255 "Invalid" ;
VAL_ 660 Slot7ACoorX 255 "Invalid" ;
VAL_ 660 Slot7ACoorY 255 "Invalid" ;
VAL_ 660 Slot7BCoorX 255 "Invalid" ;
VAL_ 660 Slot7BCoorY 255 "Invalid" ;
VAL_ 660 Slot7CCoorX 255 "Invalid" ;
VAL_ 660 Slot7CCoorY 255 "Invalid" ;
VAL_ 660 Slot7DCoorX 255 "Invalid" ;
VAL_ 660 Slot7DCoorY 255 "Invalid" ;
VAL_ 660 Slot8ACoorX 255 "Invalid" ;
VAL_ 660 Slot8ACoorY 255 "Invalid" ;
VAL_ 660 Slot8BCoorX 255 "Invalid" ;
VAL_ 660 Slot8BCoorY 255 "Invalid" ;
VAL_ 660 Slot8CCoorX 255 "Invalid" ;
VAL_ 660 Slot8CCoorY 255 "Invalid" ;
VAL_ 660 Slot8DCoorX 255 "Invalid" ;
VAL_ 660 Slot8DCoorY 255 "Invalid" ;
VAL_ 660 Slot9ACoorX 255 "Invalid" ;
VAL_ 660 Slot9ACoorY 255 "Invalid" ;
VAL_ 660 Slot9BCoorX 255 "Invalid" ;
VAL_ 660 Slot9BCoorY 255 "Invalid" ;
VAL_ 660 Slot9CCoorX 255 "Invalid" ;
VAL_ 660 Slot9CCoorY 255 "Invalid" ;
VAL_ 660 Slot9DCoorX 255 "Invalid" ;
VAL_ 660 Slot9DCoorY 255 "Invalid" ;
VAL_ 660 Slot10ACoorX 255 "Invalid" ;
VAL_ 660 Slot10ACoorY 255 "Invalid" ;
VAL_ 660 Slot10BCoorX 255 "Invalid" ;
VAL_ 660 Slot10BCoorY 255 "Invalid" ;
VAL_ 660 Slot10CCoorX 255 "Invalid" ;
VAL_ 660 Slot10CCoorY 255 "Invalid" ;
VAL_ 660 Slot10DCoorX 255 "Invalid" ;
VAL_ 660 Slot10DCoorY 255 "Invalid" ;
VAL_ 660 Slot11ACoorX 255 "Invalid" ;
VAL_ 660 Slot11ACoorY 255 "Invalid" ;
VAL_ 660 Slot11BCoorX 255 "Invalid" ;
VAL_ 660 Slot11BCoorY 255 "Invalid" ;
VAL_ 660 Slot11CCoorX 255 "Invalid" ;
VAL_ 660 Slot11CCoorY 255 "Invalid" ;
VAL_ 660 Slot11DCoorX 255 "Invalid" ;
VAL_ 660 Slot11DCoorY 255 "Invalid" ;
VAL_ 660 Slot12ACoorX 255 "Invalid" ;
VAL_ 660 Slot12ACoorY 255 "Invalid" ;
VAL_ 660 Slot12BCoorX 255 "Invalid" ;
VAL_ 660 Slot12BCoorY 255 "Invalid" ;
VAL_ 660 Slot12CCoorX 255 "Invalid" ;
VAL_ 660 Slot12CCoorY 255 "Invalid" ;
VAL_ 660 Slot12DCoorX 255 "Invalid" ;
VAL_ 660 Slot12DCoorY 255 "Invalid" ;
VAL_ 920 AVM3_St_BuzzerAlarmPattern 5 "Invalid(Reserved)" 4 "Buzzer ON at 1Hz" 3 "Buzzer ON at 2Hz" 2 "Buzzer ON at 4Hz" 1 "Buzzer ON" 0 "Buzzer OFF" ;
VAL_ 920 AvmDispReq 7 "Reserved" 6 "Reserved" 5 "CCO Source" 4 "HPA Source" 3 "Tracking Source" 2 "APA Source" 1 "AVM Source" 0 "Initial" ;
VAL_ 920 ObstclViewSts 3 "Invalid" 2 "OFF" 1 "ON" 0 "Inactive" ;
VAL_ 920 AvmTrigByObstclSts 3 "Invalid" 2 "OFF" 1 "ON" 0 "Inactive" ;
VAL_ 920 OvlDispSts 3 "Invalid" 2 "OFF" 1 "ON" 0 "Inactive" ;
VAL_ 920 AvmViewModSts 3 "Invalid" 2 "3D(default)" 1 "2D" 0 "Inactive" ;
VAL_ 920 AvmViewMod 31 "Reserved" 30 "Reserved" 29 "Reserved" 28 "Reserved" 27 "Reserved" 26 "Reserved" 25 "Reserved" 24 "Reserved" 23 "Driver view-3D" 22 "Top view-3D" 21 "Rear-Right view-3D" 20 "Rear-Left view-3D" 19 "Front-Right view-3D" 18 "Front-Left view-3D" 17 "Right view-3D" 16 "Left view-3D" 15 "Rear view-3D" 14 "Front view-3D" 13 "EOL/Test-view-2D" 12 "Aerial View-2D" 11 "View of both sides of the body-2D" 10 "Zoom in rear view-2D" 9 "Zoom in front view-2D" 8 "Rear wide_angle view-2D" 7 "Front wide_angle view-2D" 6 "Rear wheel view-2D" 5 "Front wheel view-2D" 4 "Right view-2D" 3 "Left view-2D" 2 "Rear view-2D" 1 "Front view-2D" 0 "Inactive" ;
VAL_ 920 AvmChasLctSts 7 "Invalid" 6 "Reserved" 5 "Reserved" 4 "Reserved" 3 "Lucent" 2 "Translucent (Reserved)" 1 "Not Lucent" 0 "Inactive" ;
VAL_ 920 AvmRoadCalSts 3 "Invalid" 2 "OFF" 1 "ON" 0 "Inactive" ;
VAL_ 920 AvmRoadCalProgsSts 7 "Reserved" 6 "Reserved" 5 "Reserved" 4 "Avm Road Calibration failed" 3 "Avm Road Calibration success" 2 "Avm Road Calibration active" 1 "Avm Road Calibration start" 0 "Inactive" ;
VAL_ 920 EolCalSts 6 "道路标定过程中超速 Road_Calibiration_over_speed" 5 "进入标定失败车门打开Enter_Calibration_fault_door_open" 4 "进入标定失败摄像头故障Enter_Calibration_fault_camera" 3 "标定失败 Calibration_False" 2 "标定成功 Calibration_Sucessful" 1 "正在标定 Calibrating" 0 "当前无标定动作 No action" ;
VAL_ 920 ApaSentiWarningMsg 7 "Invalid" 6 "reserved" 5 "reserved" 4 "person/object approach detected，lv3" 3 "person/object approach detected，lv2" 2 "person/object approach detected，lv1" 1 "normal" 0 "Initialize" ;
VAL_ 920 ApaSentiModSts 3 "Invalid" 2 "Active" 1 "Not active" 0 "Initialize" ;
VAL_ 921 PasSysSts 15 "Invalid" 14 "Reserved" 13 "Reserved" 12 "Reserved" 11 "Reserved" 10 "Reserved" 9 "Reserved" 8 "Pas Side RR sensor Error" 7 "Pas Side RF sensor Error" 6 "Pas Side LR sensor Error" 5 "Pas Side LF sensor Error" 4 "Pas Rear Sensor Error" 3 "Pas Front Sensor Error" 2 "Pas System Error" 1 "active" 0 "Off" ;
VAL_ 921 PasLoSpdAutoSts 3 "Invalid" 2 "OFF" 1 "ON" 0 "Inactive" ;
VAL_ 921 PasSwSts 3 "Invalid" 2 "OFF" 1 "ON" 0 "Inactive" ;
VAL_ 921 PasReMLeRegnObjSts 15 "reserved" 14 "Error" 13 "reserved" 12 "reserved" 11 "reserved" 10 "Zone 10" 9 "Zone 9" 8 "Zone 8" 7 "Zone 7" 6 "Zone 6" 5 "Zone 5" 4 "Zone 4" 3 "Zone 3" 2 "Zone 2" 1 "Zone 1" 0 "No Object" ;
VAL_ 921 PasReLeRegnObjSts 15 "reserved" 14 "Error" 13 "reserved" 12 "reserved" 11 "reserved" 10 "Zone 10" 9 "Zone 9" 8 "Zone 8" 7 "Zone 7" 6 "Zone 6" 5 "Zone 5" 4 "Zone 4" 3 "Zone 3" 2 "Zone 2" 1 "Zone 1" 0 "No Object" ;
VAL_ 921 PasFrntLeRegnObjSts 15 "reserved" 14 "Error" 13 "reserved" 12 "reserved" 11 "reserved" 10 "Zone 10" 9 "Zone 9" 8 "Zone 8" 7 "Zone 7" 6 "Zone 6" 5 "Zone 5" 4 "Zone 4" 3 "Zone 3" 2 "Zone 2" 1 "Zone 1" 0 "No Object" ;
VAL_ 921 PasReRiRegnObjSts 15 "reserved" 14 "Error" 13 "reserved" 12 "reserved" 11 "reserved" 10 "Zone 10" 9 "Zone 9" 8 "Zone 8" 7 "Zone 7" 6 "Zone 6" 5 "Zone 5" 4 "Zone 4" 3 "Zone 3" 2 "Zone 2" 1 "Zone 1" 0 "No Object" ;
VAL_ 921 PasFrntRiRegnObjSts 15 "reserved" 14 "Error" 13 "reserved" 12 "reserved" 11 "reserved" 10 "Zone 10" 9 "Zone 9" 8 "Zone 8" 7 "Zone 7" 6 "Zone 6" 5 "Zone 5" 4 "Zone 4" 3 "Zone 3" 2 "Zone 2" 1 "Zone 1" 0 "No Object" ;
VAL_ 921 PasFrntMLeRegnObjSts 15 "reserved" 14 "Error" 13 "reserved" 12 "reserved" 11 "reserved" 10 "Zone 10" 9 "Zone 9" 8 "Zone 8" 7 "Zone 7" 6 "Zone 6" 5 "Zone 5" 4 "Zone 4" 3 "Zone 3" 2 "Zone 2" 1 "Zone 1" 0 "No Object" ;
VAL_ 921 PasReMRiRegnObjSts 15 "reserved" 14 "Error" 13 "reserved" 12 "reserved" 11 "reserved" 10 "Zone 10" 9 "Zone 9" 8 "Zone 8" 7 "Zone 7" 6 "Zone 6" 5 "Zone 5" 4 "Zone 4" 3 "Zone 3" 2 "Zone 2" 1 "Zone 1" 0 "No Object" ;
VAL_ 921 PasHumResp 15 "reversed" 14 "reversed" 13 "reversed" 12 "reversed" 11 "reversed" 10 "reversed" 9 "reversed" 8 "reversed" 7 "reversed" 6 "reversed" 5 "reversed" 4 "can not close pas when the car is in R gear" 3 "can not open pas when parking brake is on" 2 "can not open pas when the car is in P gear" 1 "can not open pas when v is higher than 15km/h" 0 "No remindering" ;
VAL_ 921 PasFrntMRiRegnObjSts 15 "reserved" 14 "Error" 13 "reserved" 12 "reserved" 11 "reserved" 10 "Zone 10" 9 "Zone 9" 8 "Zone 8" 7 "Zone 7" 6 "Zone 6" 5 "Zone 5" 4 "Zone 4" 3 "Zone 3" 2 "Zone 2" 1 "Zone 1" 0 "No Object" ;
VAL_ 661 HPA_ObjTyp1 15 "Reserved" 14 "Unknow" 13 "Static object" 12 "Van/Mpv" 11 "Cyclelist" 10 "Tricycle" 9 "Pickup" 8 "Water horse" 7 "Cone pail" 6 "bus" 5 "SUV" 4 "Pedestrian" 3 "Motorcycle" 2 "Truck" 1 "Car" 0 "No object" ;
VAL_ 661 HPA_ObjMovmtDir1 3 "Backward" 2 "Forward" 1 "Static" 0 "Unknown" ;
VAL_ 661 HPA_ObjTyp2 15 "Reserved" 14 "Unknow" 13 "Static object" 12 "Van/Mpv" 11 "Cyclelist" 10 "Tricycle" 9 "Pickup" 8 "Water horse" 7 "Cone pail" 6 "bus" 5 "SUV" 4 "Pedestrian" 3 "Motorcycle" 2 "Truck" 1 "Car" 0 "No object" ;
VAL_ 661 HPA_ObjMovmtDir2 3 "Backward" 2 "Forward" 1 "Static" 0 "Unknown" ;
VAL_ 661 HPA_ObjTyp3 15 "Reserved" 14 "Unknow" 13 "Static object" 12 "Van/Mpv" 11 "Cyclelist" 10 "Tricycle" 9 "Pickup" 8 "Water horse" 7 "Cone pail" 6 "bus" 5 "SUV" 4 "Pedestrian" 3 "Motorcycle" 2 "Truck" 1 "Car" 0 "No object" ;
VAL_ 661 HPA_ObjMovmtDir3 3 "Backward" 2 "Forward" 1 "Static" 0 "Unknown" ;
VAL_ 661 HPA_ObjTyp4 15 "Reserved" 14 "Unknow" 13 "Static object" 12 "Van/Mpv" 11 "Cyclelist" 10 "Tricycle" 9 "Pickup" 8 "Water horse" 7 "Cone pail" 6 "bus" 5 "SUV" 4 "Pedestrian" 3 "Motorcycle" 2 "Truck" 1 "Car" 0 "No object" ;
VAL_ 661 HPA_ObjMovmtDir4 3 "Backward" 2 "Forward" 1 "Static" 0 "Unknown" ;
VAL_ 661 HPA_ObjTyp5 15 "Reserved" 14 "Unknow" 13 "Static object" 12 "Van/Mpv" 11 "Cyclelist" 10 "Tricycle" 9 "Pickup" 8 "Water horse" 7 "Cone pail" 6 "bus" 5 "SUV" 4 "Pedestrian" 3 "Motorcycle" 2 "Truck" 1 "Car" 0 "No object" ;
VAL_ 661 HPA_ObjMovmtDir5 3 "Backward" 2 "Forward" 1 "Static" 0 "Unknown" ;
VAL_ 661 HPA_ObjTyp6 15 "Reserved" 14 "Unknow" 13 "Static object" 12 "Van/Mpv" 11 "Cyclelist" 10 "Tricycle" 9 "Pickup" 8 "Water horse" 7 "Cone pail" 6 "bus" 5 "SUV" 4 "Pedestrian" 3 "Motorcycle" 2 "Truck" 1 "Car" 0 "No object" ;
VAL_ 661 HPA_ObjMovmtDir6 3 "Backward" 2 "Forward" 1 "Static" 0 "Unknown" ;
VAL_ 661 HPA_ObjTyp7 15 "Reserved" 14 "Unknow" 13 "Static object" 12 "Van/Mpv" 11 "Cyclelist" 10 "Tricycle" 9 "Pickup" 8 "Water horse" 7 "Cone pail" 6 "bus" 5 "SUV" 4 "Pedestrian" 3 "Motorcycle" 2 "Truck" 1 "Car" 0 "No object" ;
VAL_ 661 HPA_ObjMovmtDir7 3 "Backward" 2 "Forward" 1 "Static" 0 "Unknown" ;
VAL_ 661 HPA_ObjTyp8 15 "Reserved" 14 "Unknow" 13 "Static object" 12 "Van/Mpv" 11 "Cyclelist" 10 "Tricycle" 9 "Pickup" 8 "Water horse" 7 "Cone pail" 6 "bus" 5 "SUV" 4 "Pedestrian" 3 "Motorcycle" 2 "Truck" 1 "Car" 0 "No object" ;
VAL_ 661 HPA_ObjMovmtDir8 3 "Backward" 2 "Forward" 1 "Static" 0 "Unknown" ;
VAL_ 661 HPA_ObjTyp9 15 "Reserved" 14 "Unknow" 13 "Static object" 12 "Van/Mpv" 11 "Cyclelist" 10 "Tricycle" 9 "Pickup" 8 "Water horse" 7 "Cone pail" 6 "bus" 5 "SUV" 4 "Pedestrian" 3 "Motorcycle" 2 "Truck" 1 "Car" 0 "No object" ;
VAL_ 661 HPA_ObjMovmtDir9 3 "Backward" 2 "Forward" 1 "Static" 0 "Unknown" ;
VAL_ 661 HPA_ObjTyp10 15 "Reserved" 14 "Unknow" 13 "Static object" 12 "Van/Mpv" 11 "Cyclelist" 10 "Tricycle" 9 "Pickup" 8 "Water horse" 7 "Cone pail" 6 "bus" 5 "SUV" 4 "Pedestrian" 3 "Motorcycle" 2 "Truck" 1 "Car" 0 "No object" ;
VAL_ 661 HPA_ObjMovmtDir10 3 "Backward" 2 "Forward" 1 "Static" 0 "Unknown" ;
VAL_ 661 HPA_ObjTyp11 15 "Reserved" 14 "Unknow" 13 "Static object" 12 "Van/Mpv" 11 "Cyclelist" 10 "Tricycle" 9 "Pickup" 8 "Water horse" 7 "Cone pail" 6 "bus" 5 "SUV" 4 "Pedestrian" 3 "Motorcycle" 2 "Truck" 1 "Car" 0 "No object" ;
VAL_ 661 HPA_ObjMovmtDir11 3 "Backward" 2 "Forward" 1 "Static" 0 "Unknown" ;
VAL_ 661 HPA_ObjTyp12 15 "Reserved" 14 "Unknow" 13 "Static object" 12 "Van/Mpv" 11 "Cyclelist" 10 "Tricycle" 9 "Pickup" 8 "Water horse" 7 "Cone pail" 6 "bus" 5 "SUV" 4 "Pedestrian" 3 "Motorcycle" 2 "Truck" 1 "Car" 0 "No object" ;
VAL_ 661 HPA_ObjMovmtDir12 3 "Backward" 2 "Forward" 1 "Static" 0 "Unknown" ;
VAL_ 661 ApaSlot1_Sts 7 "Reserved" 6 "Reserved" 5 "Occupied by Looks" 4 "Occupied by cone barrel" 3 "Occupied by vehicles" 2 "Valid" 1 "Invalid" 0 "None" ;
VAL_ 661 ApaSlot2_Sts 7 "Reserved" 6 "Reserved" 5 "Occupied by Looks" 4 "Occupied by cone barrel" 3 "Occupied by vehicles" 2 "Valid" 1 "Invalid" 0 "None" ;
VAL_ 661 ApaSlot3_Sts 7 "Reserved" 6 "Reserved" 5 "Occupied by Looks" 4 "Occupied by cone barrel" 3 "Occupied by vehicles" 2 "Valid" 1 "Invalid" 0 "None" ;
VAL_ 661 ApaSlot4_Sts 7 "Reserved" 6 "Reserved" 5 "Occupied by Looks" 4 "Occupied by cone barrel" 3 "Occupied by vehicles" 2 "Valid" 1 "Invalid" 0 "None" ;
VAL_ 661 ApaSlot5_Sts 7 "Reserved" 6 "Reserved" 5 "Occupied by Looks" 4 "Occupied by cone barrel" 3 "Occupied by vehicles" 2 "Valid" 1 "Invalid" 0 "None" ;
VAL_ 661 ApaSlot6_Sts 7 "Reserved" 6 "Reserved" 5 "Occupied by Looks" 4 "Occupied by cone barrel" 3 "Occupied by vehicles" 2 "Valid" 1 "Invalid" 0 "None" ;
VAL_ 661 ApaSlot7_Sts 7 "Reserved" 6 "Reserved" 5 "Occupied by Looks" 4 "Occupied by cone barrel" 3 "Occupied by vehicles" 2 "Valid" 1 "Invalid" 0 "None" ;
VAL_ 661 ApaSlot8_Sts 7 "Reserved" 6 "Reserved" 5 "Occupied by Looks" 4 "Occupied by cone barrel" 3 "Occupied by vehicles" 2 "Valid" 1 "Invalid" 0 "None" ;
VAL_ 661 ApaSlot9_Sts 7 "Reserved" 6 "Reserved" 5 "Occupied by Looks" 4 "Occupied by cone barrel" 3 "Occupied by vehicles" 2 "Valid" 1 "Invalid" 0 "None" ;
VAL_ 661 ApaSlot10_Sts 7 "Reserved" 6 "Reserved" 5 "Occupied by Looks" 4 "Occupied by cone barrel" 3 "Occupied by vehicles" 2 "Valid" 1 "Invalid" 0 "None" ;
VAL_ 661 ApaSlot11_Sts 7 "Reserved" 6 "Reserved" 5 "Occupied by Looks" 4 "Occupied by cone barrel" 3 "Occupied by vehicles" 2 "Valid" 1 "Invalid" 0 "None" ;
VAL_ 661 ApaSlot12_Sts 7 "Reserved" 6 "Reserved" 5 "Occupied by Looks" 4 "Occupied by cone barrel" 3 "Occupied by vehicles" 2 "Valid" 1 "Invalid" 0 "None" ;
VAL_ 1099 IDC_44B_NM_Repeat 1 "该报文发送节点请求其他节点进入重复报文状态Repeat Message State requested" 0 "该报文节点未请求其他节点进入重复报文状态Repeat Message State not requested" ;
VAL_ 1099 IDC_44B_NM_ActvWakeup 1 "该报文发送节点主动唤醒网络Node has woken up the network(active Wakeup)" 0 "该报文发送节点未主动唤醒网络(被其他节点唤醒)Node has not woken up the network(passive wakeup)" ;
VAL_ 1099 IDC_44B_NM_Wus 2 "KL15On" 1 "WakedUpByNetwork" 0 "NoWakeUpSource" ;
VAL_ 1099 IDC_44B_NM_NMSts 1 "NotInRepMsgSt" 0 "InRepMsgSt" ;
VAL_ 309 APA_FuncMode 7 "Reserved" 6 "LPA" 5 "AEA" 4 "HPA" 3 "MRA" 2 "RPA" 1 "APA" 0 "None" ;
VAL_ 309 APA_TqReqFlg 1 "Request" 0 "No Request" ;
VAL_ 309 APA_LgtMtnCtrReq 3 "Park" 2 "Not Available" 1 "Pilot" 0 "Not Request" ;
VAL_ 309 APA_TqReqVld 1 "Valid" 0 "Invalid" ;
VAL_ 309 APA_RdyReqVld 1 "Valid" 0 "Invalid" ;
VAL_ 309 APA_RdyReq 3 "请求维持Ready" 2 "请求下Ready" 1 "请求上Ready" 0 "None" ;
VAL_ 309 APA_GearCtrlEnable 3 "Reversed" 2 "Active" 1 "Request" 0 "No Request" ;
VAL_ 309 APA_TarGearReq 7 "Reversed" 6 "Reversed" 5 "Reversed" 4 "Target Shift D" 3 "Target Shift N" 2 "Target Shift R" 1 "Target Shift P" 0 "No Request" ;
VAL_ 309 APA_TarGearReqVld 1 "Valid" 0 "Invalid" ;
VAL_ 309 APA_AxReqEnable 1 "Enable" 0 "Not Enable" ;
VAL_ 309 APA_AxReqVld 1 "Valid" 0 "Invalid" ;
VAL_ 309 APA_SysFailSts 1 "fault present" 0 "No fault present" ;
VAL_ 309 APA_DrvOffReq 1 "Request" 0 "Not Request" ;
VAL_ 309 APA_VehStandstillReq 1 "Request" 0 "Not Request" ;
VAL_ 309 APA_CtrlEPBAux 1 "Request" 0 "No Request" ;
VAL_ 309 APA_ControlEPB 3 "Reserved" 2 "Request clamp" 1 "Request release" 0 "No Request" ;
VAL_ 309 APA_MEBTarAReq 1 "Enable" 0 "Not Enable" ;
VAL_ 309 APA_MEBTarAVld 1 "Valid" 0 "Invalid" ;
VAL_ 309 APA_PreFillReq 1 "Request" 0 "No Request" ;
VAL_ 309 APA_FuncMode_EPS 7 "Reserved" 6 "Reserved" 5 "Reserved" 4 "HPA" 3 "MRA" 2 "RPA" 0 "None 0x1: APA" ;
VAL_ 309 APA_BrkReqType 3 "Reserved" 2 "Emergency brake" 1 "Comfortable brake" 0 "No Request" ;
VAL_ 309 APA_StrWhlAgReqActv 3 "Reserved" 2 "Active" 1 "Request" 0 "No Request" ;
VAL_ 309 APA_StrWhlAgReqVld 3 "Reserved" 2 "Invalid" 1 "Valid" 0 "Initializing" ;
VAL_ 309 APA_ControlEPBVld 1 "Valid" 0 "Invalid" ;
VAL_ 310 ADAS_LgtMtnCtrReq 3 "Park" 2 "Not Available" 1 "Pilot" 0 "Not Request" ;
VAL_ 310 ADAS_LgtReqMode 3 "reserved" 2 "ADAS_l3" 1 "ADAS_l12" 0 "None" ;
VAL_ 310 ADAS_TarTqReqEna 1 "Enable" 0 "Not Enable" ;
VAL_ 310 ADAS_TarTqReqVld 1 "Valid" 0 "Invalid" ;
VAL_ 310 ADAS_AMAPRequest 1 "Request" 0 "No request" ;
VAL_ 310 ADAS_AMAPRequestvld 1 "Valid" 0 "Invalid" ;
VAL_ 310 ADAS_GearCtrEnable 3 "Reversed" 2 "Active" 1 "Request" 0 "No Request" ;
VAL_ 310 ADAS_TarGearReqVld 1 "Valid" 0 "Invalid" ;
VAL_ 310 ADAS_SysFailSts 1 "Available" 0 "Not available" ;
VAL_ 310 ADAS_TarGearReq 7 "Reversed" 6 "Reversed" 5 "Reversed" 4 "Target Shift D" 3 "Target Shift N" 2 "Target Shift R" 1 "Target Shift P" 0 "No Request" ;
VAL_ 310 ADAS_TarAxReqEna 1 "Enable" 0 "Not Enable" ;
VAL_ 310 ADAS_TarAxReqVld 1 "Valid" 0 "Invalid" ;
VAL_ 310 ADAS_DrvOffReq 1 "Request" 0 "No Request" ;
VAL_ 310 ADAS_DecelToStopReq 1 "Request" 0 "No Request" ;
VAL_ 310 ADAS_Req_Prefill 1 "Request" 0 "Not Request" ;
VAL_ 310 ADAS_Req_ABA 1 "Request" 0 "Not Request" ;
VAL_ 310 ADAS_Lvl_ABA 3 "level 3；" 2 "level 2；" 1 "level 1；" 0 "level 0；" ;
VAL_ 310 ADAS_Req_AWB 1 "Request" 0 "Not Request" ;
VAL_ 310 ADAS_Lvl_AWB 7 "Reserved" 6 "Reserved" 5 "Reserved" 4 "Level 4" 3 "Level 3" 2 "Level 2" 1 "Level 1" 0 "No Request" ;
VAL_ 310 ADAS_TarAReq_AEB 1 "Request 有要求" 0 "No Request 无要求" ;
VAL_ 310 ADAS_DecelTyp_AEB 15 "Reserved" 14 "Reserved" 13 "Reserved" 12 "Reserved" 11 "Reserved" 10 "Reserved" 9 "Reserved" 8 "Reserved" 7 "Reserved" 6 "RCTB" 5 "FCTB" 4 "EBA" 3 "AEB~CYCLIsT" 2 "AEB~VRU" 1 "AEB" 0 "Dedault" ;
VAL_ 310 ADAS_DecelVld_AEB 1 "Valid" 0 "Invalid" ;
VAL_ 310 ADAS_Req_EPB 3 "reserved." 2 "release" 1 "lock" 0 "No request" ;
VAL_ 310 ADAS_LatMtnCtrlSts 1 "Active" 0 "Not active" ;
VAL_ 310 ADAS_LatFuncMode 3 "Reserved" 2 "ESS/AES" 1 "LKA/RDP/ELK" 0 "None" ;
VAL_ 310 ADAS_PinionAgReqVld 3 "Reserved" 2 "Valid" 1 "Invalid" 0 "Initializing" ;
VAL_ 310 ADAS_Req_EPBVld 1 "Valid" 0 "Invalid" ;
VAL_ 310 ADS_DrvTarTq_J6 65535 "Invalid" ;
VAL_ 310 ADS_SteerAgCtrlEnaReq_J6 1 "Active" 0 "Not Active" ;
VAL_ 923 AVAP_RemViewSts 15 "reserved" 14 "reserved" 13 "reserved" 12 "reserved" 11 "reserved" 10 "reserved" 9 "reserved" 8 "reserved" 7 "reserved" 6 "reserved" 5 "reserved" 4 "功能异常-AVAP控制器内部异常" 3 "功能异常-后视镜异常" 2 "功能异常-摄像头异常" 1 "功能正常" 0 "初始值；" ;
VAL_ 923 AVAP_ViewSwtSts 15 "reserved" 14 "reserved" 13 "reserved" 12 "reserved" 11 "reserved" 10 "AVM 3D画面（俯视）" 9 "AVM 3D画面（右视）" 8 "AVM 3D画面（左视）" 7 "AVM 3D画面（后视）" 6 "AVM 3D画面（前视）" 5 "鱼眼（四路拼接）" 4 "鱼眼（右视）" 3 "鱼眼（左视）" 2 "鱼眼（后视）" 1 "鱼眼（前视）" 0 "初始值" ;
VAL_ 923 AVAP_MirrReq 3 "reserved" 2 "unfold请求展开" 1 "fold请求关闭" 0 "初始值" ;
VAL_ 923 AVAP_ScreenshotReq 3 "reserved" 2 "有俯视图和后视图" 1 "仅有俯视图" 0 "初始值" ;
VAL_ 923 AVAP_LOCK_Req 1 "Enable" 0 "Disable" ;
VAL_ 923 AVAP_LOCK_ReqVal 1 "Request" 0 "No Request" ;
VAL_ 923 AVAP_TurnLightReq 7 "Reserved" 6 "Reserved" 5 "Reserved" 4 "Activate hazard light" 3 "Activate right turn light" 2 "Activate left turn light" 1 "Deactivate turn light" 0 "No Request" ;
VAL_ 923 AVAP_Lpa_Sts 9 "BackgroundSearching" 8 "Undo" 7 "Pause" 6 "Terminate" 5 "Failure" 4 "Completed" 3 "Guidance active" 2 "Searching" 1 "Standby" 0 "Off" ;
VAL_ 923 APA_FuncMode_BDC 7 "Reserved" 6 "LPA" 5 "AEA" 4 "HPA" 3 "MRA" 2 "RPA" 1 "APA" 0 "None" ;
VAL_ 924 ADAS_LowHighBeamReq 7 "Reserved" 6 "Reserved" 5 "Reserved" 4 "Reserved" 3 "Activate high beam light" 2 "Activate low beam light" 1 "Deactivate beam light" 0 "No Request" ;
VAL_ 924 ADC_HAD_CoolfluidReq 1 "Request" 0 "No Request" ;
VAL_ 924 ADAS_WarnReqRi 3 "Reserved" 2 "Warning level2" 1 "Warning level1" 0 "No Request" ;
VAL_ 924 ADAS_WarnReqLe 3 "Reserved" 2 "Warning level2" 1 "Warning level1" 0 "No Request" ;
VAL_ 924 ADAS_HornReq 3 "Reserved" 2 "Reserved" 1 "Activate horn" 0 "No Request" ;
VAL_ 924 ADAS_TurnLightReq 7 "Reserved" 6 "Reserved" 5 "Reserved" 4 "Activate hazard light" 3 "Activate right turn light" 2 "Activate left turn light" 1 "Deactivate turn light" 0 "No Request" ;
VAL_ 924 ADAS_FrontWasherReq 1 "Activate low speed wiper" 0 "No Request" ;
VAL_ 924 ADAS_FrontWiperReq 3 "Activate high speed wiper" 2 "Activate low speed wiper" 1 "Deactivate wiper" 0 "No Request" ;
VAL_ 924 ADC_HAD_CoolingfluidflowRateReq 15 "Invalid" 14 "3.5L/min" 13 "3.25L/min" 12 "3.0L/min" 11 "2.75L/min" 10 "2.5L/min" 9 "2.25L/min" 8 "2.0L/min" 7 "1.75L/min" 6 "1.5L/min" 5 "1.25L/min" 4 "1.0L/min" 3 "0.75L/min" 2 "0.5L/min" 1 "0.25L/min" 0 "0.0L/min" ;
VAL_ 908 LeftFrontUssSts 3 "reserved" 2 "failure" 1 "Blockage" 0 "Normal" ;
VAL_ 908 FrontLeftUssSts 3 "reserved" 2 "failure" 1 "Blockage" 0 "Normal" ;
VAL_ 908 FrontLeftCenterUssSts 3 "reserved" 2 "failure" 1 "Blockage" 0 "Normal" ;
VAL_ 908 FrontRightCenterUssSts 3 "reserved" 2 "failure" 1 "Blockage" 0 "Normal" ;
VAL_ 908 FrontRightUssSts 3 "reserved" 2 "failure" 1 "Blockage" 0 "Normal" ;
VAL_ 908 RightFrontUssSts 3 "reserved" 2 "failure" 1 "Blockage" 0 "Normal" ;
VAL_ 908 LeftBackUssSts 3 "reserved" 2 "failure" 1 "Blockage" 0 "Normal" ;
VAL_ 908 BackLeftUssSts 3 "reserved" 2 "failure" 1 "Blockage" 0 "Normal" ;
VAL_ 908 BackLeftCenterUssSts 3 "reserved" 2 "failure" 1 "Blockage" 0 "Normal" ;
VAL_ 908 BackRightCenterUssSts 3 "reserved" 2 "failure" 1 "Blockage" 0 "Normal" ;
VAL_ 908 BackRightUssSts 3 "reserved" 2 "failure" 1 "Blockage" 0 "Normal" ;
VAL_ 908 RightBacktUssSts 3 "reserved" 2 "failure" 1 "Blockage" 0 "Normal" ;
VAL_ 908 PAS_FL_Distance 7 "Reserved" 6 "Reserved" 5 "Reserved" 4 "Green" 3 "Green" 2 "Yellow" 1 "Red" 0 "None" ;
VAL_ 908 PAS_FML_Distance 7 "Reserved" 6 "Reserved" 5 "Reserved" 4 "Green" 3 "Green" 2 "Yellow" 1 "Red" 0 "None" ;
VAL_ 908 PAS_FMR_Distance 7 "Reserved" 6 "Reserved" 5 "Reserved" 4 "Green" 3 "Green" 2 "Yellow" 1 "Red" 0 "None" ;
VAL_ 908 PAS_FR_Distance 7 "Reserved" 6 "Reserved" 5 "Reserved" 4 "Green" 3 "Green" 2 "Yellow" 1 "Red" 0 "None" ;
VAL_ 908 SDW_LSF1_Distance 7 "Reserved" 6 "Reserved" 5 "Reserved" 4 "Green" 3 "Green" 2 "Yellow" 1 "Red" 0 "None" ;
VAL_ 908 SDW_LSF2_Distance 7 "Reserved" 6 "Reserved" 5 "Reserved" 4 "Green" 3 "Green" 2 "Yellow" 1 "Red" 0 "None" ;
VAL_ 908 SDW_LSR2_Distance 7 "Reserved" 6 "Reserved" 5 "Reserved" 4 "Green" 3 "Green" 2 "Yellow" 1 "Red" 0 "None" ;
VAL_ 908 SDW_LSR1_Distance 7 "Reserved" 6 "Reserved" 5 "Reserved" 4 "Green" 3 "Green" 2 "Yellow" 1 "Red" 0 "None" ;
VAL_ 908 SDW_RSF1_Distance 7 "Reserved" 6 "Reserved" 5 "Reserved" 4 "Green" 3 "Green" 2 "Yellow" 1 "Red" 0 "None" ;
VAL_ 908 SDW_RSF2_Distance 7 "Reserved" 6 "Reserved" 5 "Reserved" 4 "Green" 3 "Green" 2 "Yellow" 1 "Red" 0 "None" ;
VAL_ 908 SDW_RSR2_Distance 7 "Reserved" 6 "Reserved" 5 "Reserved" 4 "Green" 3 "Green" 2 "Yellow" 1 "Red" 0 "None" ;
VAL_ 908 SDW_RSR1_Distance 7 "Reserved" 6 "Reserved" 5 "Reserved" 4 "Green" 3 "Green" 2 "Yellow" 1 "Red" 0 "None" ;
VAL_ 908 PAS_RL_Distance 7 "Reserved" 6 "Reserved" 5 "Reserved" 4 "Green" 3 "Green" 2 "Yellow" 1 "Red" 0 "None" ;
VAL_ 908 PAS_RML_Distance 7 "Reserved" 6 "Reserved" 5 "Reserved" 4 "Green" 3 "Green" 2 "Yellow" 1 "Red" 0 "None" ;
VAL_ 908 PAS_RMR_Distance 7 "Reserved" 6 "Reserved" 5 "Reserved" 4 "Green" 3 "Green" 2 "Yellow" 1 "Red" 0 "None" ;
VAL_ 908 PAS_RR_Distance 7 "Reserved" 6 "Reserved" 5 "Reserved" 4 "Green" 3 "Green" 2 "Yellow" 1 "Red" 0 "None" ;
VAL_ 908 ApaCalibrationParameter 1 "Completed" 0 "Int" ;
VAL_ 908 ApaFactoryCalibrationSts 3 "标定失败" 2 "标定成功" 1 "标定中" 0 "NONE" ;
VAL_ 908 ApaFactoryCalibFailureRsn 255 "Reserved" 254 "Reserved" 253 "Reserved" 252 "Reserved" 251 "Reserved" 250 "Reserved" 249 "Reserved" 248 "Reserved" 247 "Reserved" 246 "Reserved" 245 "Reserved" 244 "Reserved" 243 "Reserved" 242 "Reserved" 241 "Reserved" 240 "Reserved" 239 "Reserved" 238 "Reserved" 237 "Reserved" 236 "Reserved" 235 "Reserved" 234 "Reserved" 233 "Reserved" 232 "Reserved" 231 "Reserved" 230 "Reserved" 229 "Reserved" 228 "Reserved" 227 "Reserved" 226 "Reserved" 225 "Reserved" 224 "Reserved" 223 "Reserved" 222 "Reserved" 221 "Reserved" 220 "Reserved" 219 "Reserved" 218 "Reserved" 217 "Reserved" 216 "Reserved" 215 "Reserved" 214 "Reserved" 213 "Reserved" 212 "Reserved" 211 "Reserved" 210 "Reserved" 209 "Reserved" 208 "Reserved" 207 "Reserved" 206 "Reserved" 205 "Reserved" 204 "Reserved" 203 "Reserved" 202 "Reserved" 201 "Reserved" 200 "Reserved" 199 "Reserved" 198 "Reserved" 197 "Reserved" 196 "Reserved" 195 "Reserved" 194 "Reserved" 193 "Reserved" 192 "Reserved" 191 "Reserved" 190 "Reserved" 189 "Reserved" 188 "Reserved" 187 "Reserved" 186 "Reserved" 185 "Reserved" 184 "Reserved" 183 "Reserved" 182 "Reserved" 181 "Reserved" 180 "Reserved" 179 "Reserved" 178 "Reserved" 177 "Reserved" 176 "Reserved" 175 "Reserved" 174 "Reserved" 173 "Reserved" 172 "Reserved" 171 "Reserved" 170 "Reserved" 169 "Reserved" 168 "Reserved" 167 "Reserved" 166 "Reserved" 165 "Reserved" 164 "Reserved" 163 "Reserved" 162 "Reserved" 161 "Reserved" 160 "Reserved" 159 "Reserved" 158 "Reserved" 157 "Reserved" 156 "Reserved" 155 "Reserved" 154 "Reserved" 153 "Reserved" 152 "Reserved" 151 "Reserved" 150 "Reserved" 149 "Reserved" 148 "Reserved" 147 "Reserved" 146 "Reserved" 145 "Reserved" 144 "Reserved" 143 "Reserved" 142 "Reserved" 141 "Reserved" 140 "Reserved" 139 "Reserved" 138 "Reserved" 137 "Reserved" 136 "Reserved" 135 "Reserved" 134 "Reserved" 133 "Reserved" 132 "Reserved" 131 "Reserved" 130 "Reserved" 129 "Reserved" 128 "Reserved" 127 "Reserved" 126 "Reserved" 125 "Reserved" 124 "Reserved" 123 "Reserved" 122 "Reserved" 121 "Reserved" 120 "Reserved" 119 "Reserved" 118 "Reserved" 117 "Reserved" 116 "Reserved" 115 "Reserved" 114 "Reserved" 113 "Reserved" 112 "Reserved" 111 "Reserved" 110 "Reserved" 109 "Reserved" 108 "Reserved" 107 "Reserved" 106 "Reserved" 105 "Reserved" 104 "Reserved" 103 "Reserved" 102 "Reserved" 101 "Reserved" 100 "Reserved" 99 "Reserved" 98 "Reserved" 97 "Reserved" 96 "Reserved" 95 "Reserved" 94 "Reserved" 93 "Reserved" 92 "Reserved" 91 "Reserved" 90 "Reserved" 89 "Reserved" 88 "Reserved" 87 "Reserved" 86 "Reserved" 85 "Reserved" 84 "Reserved" 83 "Reserved" 82 "Reserved" 81 "Reserved" 80 "Reserved" 79 "Cord49" 78 "Cord49" 77 "Cord49" 76 "Cord49" 75 "Cord49" 74 "Cord49" 73 "Cord49" 72 "Cord48" 71 "Cord47" 70 "Cord46" 69 "Cord45" 68 "Cord44" 67 "Cord43" 66 "Cord42" 65 "Cord41" 64 "None" 63 "Cord39" 62 "Cord39" 61 "Cord39" 60 "Cord39" 59 "Cord39" 58 "Cord39" 57 "Cord39" 56 "Cord38" 55 "Cord37" 54 "Cord36" 53 "Cord35" 52 "Cord34" 51 "Cord33" 50 "Cord32" 49 "Cord31" 48 "NONE" 47 "Cord29" 46 "Cord29" 45 "Cord29" 44 "Cord29" 43 "Cord29" 42 "Cord29" 41 "Cord29" 40 "Cord28" 39 "Cord27" 38 "Cord26" 37 "Cord25" 36 "Cord24" 35 "Cord23" 34 "Cord22" 33 "Cord21" 32 "NONE" 31 "Cord19" 30 "Cord19" 29 "Cord19" 28 "Cord19" 27 "Cord19" 26 "Cord19" 25 "Cord19" 24 "Cord18" 23 "Cord17" 22 "Cord16" 21 "Cord15" 20 "Cord14" 19 "Cord13" 18 "Cord12" 17 "Cord11" 16 "NONE" 15 "NONE" 14 "NONE" 13 "NONE" 12 "NONE" 11 "NONE" 10 "NONE" 9 "NONE" 8 "NONE" 7 "NONE" 6 "NONE" 5 "NONE" 4 "NONE" 3 "NONE" 2 "NONE" 1 "Cord1" 0 "NONE" ;
VAL_ 908 ApaAfterSalesCalibrationSts 3 "标定失败" 2 "标定成功" 1 "标定中" 0 "NONE" ;
VAL_ 908 ApaAfterSalesCalibFailureRsn 255 "Reserved" 254 "Reserved" 253 "Reserved" 252 "Reserved" 251 "Reserved" 250 "Reserved" 249 "Reserved" 248 "Reserved" 247 "Reserved" 246 "Reserved" 245 "Reserved" 244 "Reserved" 243 "Reserved" 242 "Reserved" 241 "Reserved" 240 "Reserved" 239 "Reserved" 238 "Reserved" 237 "Reserved" 236 "Reserved" 235 "Reserved" 234 "Reserved" 233 "Reserved" 232 "Reserved" 231 "Reserved" 230 "Reserved" 229 "Reserved" 228 "Reserved" 227 "Reserved" 226 "Reserved" 225 "Reserved" 224 "Reserved" 223 "Reserved" 222 "Reserved" 221 "Reserved" 220 "Reserved" 219 "Reserved" 218 "Reserved" 217 "Reserved" 216 "Reserved" 215 "Reserved" 214 "Reserved" 213 "Reserved" 212 "Reserved" 211 "Reserved" 210 "Reserved" 209 "Reserved" 208 "Reserved" 207 "Reserved" 206 "Reserved" 205 "Reserved" 204 "Reserved" 203 "Reserved" 202 "Reserved" 201 "Reserved" 200 "Reserved" 199 "Reserved" 198 "Reserved" 197 "Reserved" 196 "Reserved" 195 "Reserved" 194 "Reserved" 193 "Reserved" 192 "Reserved" 191 "Reserved" 190 "Reserved" 189 "Reserved" 188 "Reserved" 187 "Reserved" 186 "Reserved" 185 "Reserved" 184 "Reserved" 183 "Reserved" 182 "Reserved" 181 "Reserved" 180 "Reserved" 179 "Reserved" 178 "Reserved" 177 "Reserved" 176 "Reserved" 175 "Reserved" 174 "Reserved" 173 "Reserved" 172 "Reserved" 171 "Reserved" 170 "Reserved" 169 "Reserved" 168 "Reserved" 167 "Reserved" 166 "Reserved" 165 "Reserved" 164 "Reserved" 163 "Reserved" 162 "Reserved" 161 "Reserved" 160 "Reserved" 159 "Reserved" 158 "Reserved" 157 "Reserved" 156 "Reserved" 155 "Reserved" 154 "Reserved" 153 "Reserved" 152 "Reserved" 151 "Reserved" 150 "Reserved" 149 "Reserved" 148 "Reserved" 147 "Reserved" 146 "Reserved" 145 "Reserved" 144 "Reserved" 143 "Reserved" 142 "Reserved" 141 "Reserved" 140 "Reserved" 139 "Reserved" 138 "Reserved" 137 "Reserved" 136 "Reserved" 135 "Reserved" 134 "Reserved" 133 "Reserved" 132 "Reserved" 131 "Reserved" 130 "Reserved" 129 "Reserved" 128 "Reserved" 127 "Reserved" 126 "Reserved" 125 "Reserved" 124 "Reserved" 123 "Reserved" 122 "Reserved" 121 "Reserved" 120 "Reserved" 119 "Reserved" 118 "Reserved" 117 "Reserved" 116 "Reserved" 115 "Reserved" 114 "Reserved" 113 "Reserved" 112 "Reserved" 111 "Reserved" 110 "Reserved" 109 "Reserved" 108 "Reserved" 107 "Reserved" 106 "Reserved" 105 "Reserved" 104 "Reserved" 103 "Reserved" 102 "Reserved" 101 "Reserved" 100 "Reserved" 99 "Reserved" 98 "Reserved" 97 "Reserved" 96 "Reserved" 95 "Reserved" 94 "Reserved" 93 "Reserved" 92 "Reserved" 91 "Reserved" 90 "Reserved" 89 "Reserved" 88 "Reserved" 87 "Reserved" 86 "Reserved" 85 "Reserved" 84 "Reserved" 83 "Reserved" 82 "Reserved" 81 "Reserved" 80 "Reserved" 79 "Cord47" 78 "Cord47" 77 "Cord47" 76 "Cord47" 75 "Cord47" 74 "Cord47" 73 "Cord47" 72 "Cord47" 71 "Cord47" 70 "Cord46" 69 "Cord45" 68 "Cord44" 67 "Cord43" 66 "Cord42" 65 "Cord41" 64 "NONE" 63 "Cord37" 62 "Cord37" 61 "Cord37" 60 "Cord37" 59 "Cord37" 58 "Cord37" 57 "Cord37" 56 "Cord37" 55 "Cord37" 54 "Cord36" 53 "Cord35" 52 "Cord34" 51 "Cord33" 50 "Cord32" 49 "Cord31" 48 "NONE" 47 "Cord27" 46 "Cord27" 45 "Cord27" 44 "Cord27" 43 "Cord27" 42 "Cord27" 41 "Cord27" 40 "Cord27" 39 "Cord27" 38 "Cord26" 37 "Cord25" 36 "Cord24" 35 "Cord23" 34 "Cord22" 33 "Cord21" 32 "NONE" 31 "Cord17" 30 "Cord17" 29 "Cord17" 28 "Cord17" 27 "Cord17" 26 "Cord17" 25 "Cord17" 24 "Cord17" 23 "Cord17" 22 "Cord16" 21 "Cord15" 20 "Cord14" 19 "Cord13" 18 "Cord12" 17 "Cord11" 16 "NONE" 15 "NONE" 14 "NONE" 13 "NONE" 12 "NONE" 11 "NONE" 10 "NONE" 9 "NONE" 8 "NONE" 7 "NONE" 6 "NONE" 5 "Cord5" 4 "Cord4" 3 "Cord3" 2 "Cord2" 1 "Cord1" 0 "NONE" ;
VAL_ 442 ApaParkModSet 7 "Invalid" 6 "Reserved" 5 "Reserved" 4 "Reserved" 3 "Customer Select Slot" 2 "Park out" 1 "Park in" 0 "Inactive" ;
VAL_ 442 ApaSwt 3 "Invalid" 2 "APA OFF" 1 "APA ON" 0 "Inactive" ;
VAL_ 442 ApaParkInSlotSet 7 "Invalid" 6 "Reserved" 5 "Reserved" 4 "Reserved" 3 "Slant parking" 2 "Vertical parking" 1 "Transverse parking" 0 "Inactive" ;
VAL_ 442 ApaParkOutDirSet 15 "Invalid" 14 "Reserved" 13 "Reserved" 12 "Reserved" 11 "Reserved" 10 "Reserved" 9 "Reserved" 8 "Vertical Trunk Right" 7 "Vertical Trunk Left" 6 "Vertical Head Right" 5 "Vertical Head Left" 4 "Vertical Backward" 3 "Vertical forward" 2 "Half Vehicle Right" 1 "Half Vehicle Left" 0 "Inactive" ;
VAL_ 442 ApaTragParkSwt 3 "Invalid" 2 "Off" 1 "On" 0 "Inactive" ;
VAL_ 442 ApaVoicBrdtSwt 3 "Invalid" 2 "Off" 1 "On" 0 "Inactive" ;
VAL_ 442 ApaParkStrtSet 7 "Invalid" 6 "Selected Slot Parking In" 5 "Comfirmation" 4 "Tracking Parking In" 3 "Auto Parking Out" 2 "Remote Parking" 1 "Auto Parking In" 0 "Inactive" ;
VAL_ 442 ApaPathSet 3 "Invalid" 2 "Vehicle tail" 1 "Vehicle head" 0 "Inactive" ;
VAL_ 442 SlotAutoSearchSwt 3 "Invalid" 2 "OFF" 1 "ON" 0 "Inactive" ;
VAL_ 442 ApaModSet 3 "Invalid" 2 "Fast" 1 "Standard" 0 "Inactive" ;
VAL_ 442 ApaDispSwt 3 "Invalid" 2 "OFF" 1 "On" 0 "Inactive" ;
VAL_ 442 RpaDstSet 7 "Invalid" 6 "Reserved" 5 "Reserved" 4 "Reserved" 3 "8m" 2 "5m" 1 "3m" 0 "Inactive" ;
VAL_ 442 ApaTouchScrnCmd 15 "Invalid" 14 "Reserved" 13 "Reserved" 12 "Reserved" 11 "Reserved" 10 "Reserved" 9 "Reserved" 8 "Reserved" 7 "Reserved" 6 "Reserved" 5 "Reserved" 4 "Reserved" 3 "Screen release" 2 "Screen hold" 1 "Screen Touched" 0 "Inactive" ;
VAL_ 442 ScrnCoordX 2047 "Invalid" ;
VAL_ 442 ScrnCoordY 2047 "Invalid" ;
VAL_ 504 BleDrvrMtnIndcn 3 "Reserved" 2 "no signal" 1 "motioning" 0 "no motion" ;
VAL_ 504 BleRpaStrtFlg 1 "start" 0 "no start（default）" ;
VAL_ 504 BlePrkgInTypReq 3 "Reserved" 2 "Vertical" 1 "Parallel" 0 "Inactive" ;
VAL_ 504 BleBluStsFlg 3 "Reserved" 2 "fault" 1 "connect" 0 "no connect（default）" ;
VAL_ 504 BleRpaOnFlg 3 "Reserved" 2 "PARK OUT ON" 1 "PARK IN ON" 0 "OFF" ;
VAL_ 504 BleParkAbortReq 1 "Request" 0 "No request" ;
VAL_ 504 BleParkAuthentStrtReq 1 "Request" 0 "No request" ;
VAL_ 504 BleLastStep 1 "click last step" 0 "No click" ;
VAL_ 504 BleNextStep 1 "click next step" 0 "No click" ;
VAL_ 504 BleParkoutModSel 15 "Invalid" 14 "Reserved" 13 "Reserved" 12 "Reserved" 11 "Reserved" 10 "Reserved" 9 "Reserved" 8 "Vertical Trunk Right" 7 "Vertical Trunk Left" 6 "Vertical Head Right" 5 "Vertical Head Left" 4 "Backward" 3 "Forward" 2 "Half Vehicle Right" 1 "Half Vehicle Left" 0 "Inactive" ;
VAL_ 504 BleBdcRpaModReq 3 "Reserved" 2 "Rpa mode out" 1 "Rpa mode in" 0 "Inactive" ;
VAL_ 822 BleStrtEng 1 "Acitve" 0 "Inactive" ;
VAL_ 822 BleBtSts 3 "Reserved" 2 "fault" 1 "Connect" 0 "No Connect" ;
VAL_ 823 BleSysSts 1 "Error" 0 "No error" ;
VAL_ 443 HumNaviCtryRoadTyp 15 "Invalid" 14 "Reserved" 13 "Reserved" 12 "Reserved" 11 "Reserved" 10 "Reserved" 9 "Reserved" 8 "Reserved" 7 "Unknown" 6 "Limit<=10kph" 5 "10<limit<=30kph" 4 "30<limit<=50kph" 3 "50<limit<=70kph" 2 "Limit>70kph" 1 "Highway" 0 "Initializing Reserved" ;
VAL_ 443 ICC_NaviSpdLimit 14 "120Kph" 13 "110Kph" 12 "100Kph" 11 "90Kph" 10 "80Kph" 9 "70Kph" 8 "60Kph" 7 "50Kph" 6 "40Kph" 5 "30Kph" 4 "20Kph" 3 "15Kph" 2 "10Kph" 1 "5Kph" 0 "Not Recognised未识别" ;
VAL_ 443 ICC_HDwarning 1 "Fault" 0 "No Fault" ;
VAL_ 443 HumNaviSpdLimSts 7 "Invalid" 6 "Reserved" 5 "Reserved" 4 "Unknown" 3 "Plural data exsits" 2 "No limit" 1 "Exists (data available)" 0 "reserved" ;
VAL_ 443 HU_NavSpeedLimitType 3 "Interval Velocity" 2 "Road Camera" 1 "Speed-Limit Sign" 0 "Unknown" ;
VAL_ 443 HU_RampInfo 2 "reserved" 1 "匝道" 0 "unknown" ;
VAL_ 443 HumNaviSpdLimUnit 7 "Invalid" 6 "Reserved" 5 "Reserved" 4 "Reserved" 3 "Unknown" 2 "km/h" 1 "miles/h" 0 "reserved" ;
VAL_ 443 ICC_HD_TsrSignMisc 31 "reserved" 30 "reserved" 29 "reserved" 28 "reserved" 27 "reserved" 26 "reserved" 25 "reserved" 24 "reserved" 23 "reserved" 22 "reserved" 21 "reserved" 20 "Warn Merger右侧车辆汇入" 19 "Warn Workers前方道路施 工" 18 "Warn Kids注意儿童" 17 "Warn Pedestrian Cross注意行人通过" 16 "One way street" 15 "Prohibit parking" 14 "Motorway end高速出口（reserved）" 13 "Motorway start高速入口（reserved）" 12 "yield sign让行标志" 11 "stop sign停车瞭望标志" 10 "prohibiting long parking禁止长时停车" 9 "prohibiting standing and parking禁止临时及长时停车" 8 "prohibiting motor vehicle entering禁止机动车通行(reserved)" 7 "No passing禁止通行" 6 "No entry禁止驶入" 5 "prohibiting U-turning禁止掉头" 4 "prohibiting turning right禁止右转" 3 "prohibiting turning left禁止左转" 2 "end of no overtaking解除禁止超车" 1 "no overtaking禁止超车" 0 "default（No display）" ;
VAL_ 443 HU_RampSpdLim 255 "Invalid" ;
VAL_ 443 ApaSlotSet 255 "选择车位ID 255" 3 "选择车位ID 3" 2 "选择车位ID 2" 1 "选择车位ID 1" 0 "无效" ;
VAL_ 443 ICC_ApaExamStatus 3 "Invalid" 2 "No Pass" 1 "Pass" 0 "Default" ;
VAL_ 443 ICC_AdasExamStatus 3 "Invalid" 2 "No Pass" 1 "Pass" 0 "Default" ;
VAL_ 537 IPC8_F_VehicleSpeedIndi 1 "Invalid" 0 "Valid" ;
VAL_ 537 IPC8_IcmDispSpdUnitTyp 3 "Invalid" 2 "MPH" 1 "KMH" 0 "reserved" ;
VAL_ 537 IPC8_AccFailFb 7 "Invalid" 6 "Reserved" 5 "Reserved" 4 "not defined" 3 "irreversible error" 2 "reversible error" 1 "No error" 0 "reserved" ;
VAL_ 537 IPC8_IcmDispFail 15 "Invalid" 14 "Reserved" 13 "Reserved" 12 "Reserved" 11 "Reserved" 10 "Reserved" 9 "Reserved" 8 "Reserved" 7 "Reserved" 6 "Reserved" 5 "Undefined" 4 "Can Timeout" 3 "Severe Cluster Error" 2 "Simple Cluster Error" 1 "No Cluster Error" 0 "reserved" ;
VAL_ 858 BCM12_St_VehicleMode 7 "Rerserved" 6 "Gallery Mode" 5 "Test Mode（预留）" 4 "Crash Mode（预留）" 3 "Transport Mode" 2 "Factory Mode（default）" 1 "Normal Mode" 0 "initialization" ;
VAL_ 529 TIM1_St_TIMSt 1 "Active" 0 "Not active" ;
VAL_ 529 TIM1_St_TrailerLightsFaultSt 1 "Fault" 0 "Normal" ;
VAL_ 529 TIM1_St_SoftSwMemory 1 "active" 0 "inactive" ;
VAL_ 529 TIM1_St_SoftSwMemoryNew 3 "reserved" 2 "active mode2）" 1 "active mode1" 0 "inactive（对应off mode反馈）" ;
VAL_ 225 EHC12_St_AVMSaleCalibration 3 "取消标定 Calibration Cancel" 2 "开始标定 Start Calibration" 1 "进入标定 Calibration Confirm" 0 "NONE" ;
VAL_ 225 EHC24_ParkingPlaceConfirm 1 "Confirm" 0 "none" ;
VAL_ 225 AvmViewSet 31 "Reserved" 30 "Reserved" 29 "Reserved" 28 "Reserved" 27 "Reserved" 26 "Reserved" 25 "Rock Mode" 24 "Worm Mode" 23 "Driver view-3D" 22 "Top view-3D" 21 "Rear-Right view-3D" 20 "Rear-Left view-3D" 19 "Front-Right view-3D" 18 "Front-Left view-3D" 17 "Right view-3D" 16 "Left view-3D" 15 "Rear view-3D" 14 "Front view-3D" 13 "EOL/Test-view-2D" 12 "Aerial View-2D" 11 "View of both sides of the body-2D" 10 "Zoom in rear view-2D" 9 "Zoom in front view-2D" 8 "Rear wide_angle view-2D" 7 "Front wide_angle view-2D" 6 "Rear wheel view-2D" 5 "Front wheel view-2D" 4 "Right view-2D" 3 "Left view-2D" 2 "Rear view-2D" 1 "Front view-2D" 0 "Inactive" ;
VAL_ 225 AvmViewModSet 3 "Invalid" 2 "3D" 1 "2D" 0 "Inactive" ;
VAL_ 225 OvlyDispSwt 3 "Invalid" 2 "OFF" 1 "ON" 0 "Inactive" ;
VAL_ 225 ObstclViewSwt 3 "Invalid" 2 "OFF" 1 "ON" 0 "Inactive" ;
VAL_ 225 AvmTrigByObstclSwt 3 "Invalid" 2 "OFF" 1 "ON" 0 "Inactive" ;
VAL_ 225 AvmSwt 3 "Invalid" 2 "AVM OFF" 1 "AVM ON" 0 "Inactive" ;
VAL_ 225 PasSwt 3 "Invalid" 2 "PAS OFF" 1 "PAS ON" 0 "Inactive" ;
VAL_ 225 EHC24_ExitButton 1 "Active" 0 "Inactive" ;
VAL_ 225 EHC12_Set_RestoreSetting 1 "Request" 0 "No request" ;
VAL_ 225 AvmVehLctSet 7 "Invalid" 6 "Reserved" 5 "Reserved" 4 "Reserved" 3 "Lucent" 2 "Translucent" 1 "Not Lucent" 0 "Inactive" ;
VAL_ 225 EHC24_AVM_WormMode_Set 1 "ON" 0 "OFF" ;
VAL_ 225 EHCV24_AVM_RockMode_Set 1 "ON" 0 "OFF" ;
VAL_ 225 AvmChasLctSet 7 "Invalid" 6 "Reserved" 5 "Reserved" 4 "Reserved" 3 "Lucent" 2 "Translucent（Reserved）" 1 "Not Lucent" 0 "Inactive" ;
VAL_ 225 AvmRoadCalSwt 3 "Invalid" 2 "OFF" 1 "ON" 0 "Inactive" ;
VAL_ 225 EHC12_St_SoftwareUpdate 1 "execute updating" 0 "none" ;
VAL_ 225 EHC12_St_AVMRoadCalibration 2 "取消标定 Calibration Cancel" 1 "进入标定 Calibration Confirm" 0 "NONE" ;
VAL_ 225 EHC12_St_AVMFactoryCalibration 2 "取消标定 Calibration Cancel" 1 "进入标定 Calibration Confirm" 0 "NONE" ;
VAL_ 237 EHC22_NOA_ALCRequest_confirm 3 "Invalid" 2 "OFF" 1 "ON" 0 "Inactive" ;
VAL_ 237 EHC22_NOA_ALC_TYPE 3 "sport" 2 "normal" 1 "comfort" 0 "Inactive" ;
VAL_ 237 EHC22_NOA_ALC_soundnotification 3 "Invalid" 2 "sound" 1 "no sound" 0 "Inactive" ;
VAL_ 237 EHC22_HWA_EnbSw 3 "Invalid" 2 "OFF" 1 "ON" 0 "Inactive" ;
VAL_ 237 EHC22_TJA_ICA_EnbSw 3 "Invalid" 2 "OFF" 1 "ON" 0 "Inactive" ;
VAL_ 237 EHC22_IntelligentCornering_EnbSw 3 "Invalid" 2 "OFF" 1 "ON" 0 "Inactive" ;
VAL_ 237 EHC22_ESS_EnbSw 3 "Invalid" 2 "OFF" 1 "ON" 0 "Inactive" ;
VAL_ 237 EHC22_LKA_EnbSw 3 "Invalid" 2 "OFF" 1 "ON" 0 "Inactive" ;
VAL_ 237 EHC22_LDW_EnbSw 3 "Invalid" 2 "OFF" 1 "ON" 0 "Inactive" ;
VAL_ 237 EHC22_BSD_LCA_EnbSw 3 "Invalid" 2 "OFF" 1 "ON" 0 "Inactive" ;
VAL_ 237 EHC22_DOW_EnbSw 3 "Invalid" 2 "OFF" 1 "ON" 0 "Inactive" ;
VAL_ 237 EHC22_ELK_EnbSw 3 "Invalid" 2 "OFF" 1 "ON" 0 "Inactive" ;
VAL_ 237 EHC22_AVM_EnbSw 3 "Invalid" 2 "OFF" 1 "ON" 0 "Inactive" ;
VAL_ 237 EHC22_HMA_EnbSw 3 "Invalid" 2 "OFF" 1 "ON" 0 "Inactive" ;
VAL_ 237 EHC22_BAV_EnbSw 3 "Invalid" 2 "OFF" 1 "ON" 0 "Inactive" ;
VAL_ 237 EHC22_LCK_EnbSw 3 "Invalid" 2 "OFF" 1 "ON" 0 "Inactive" ;
VAL_ 237 EHC22_ASLSw 3 "Invalid" 2 "OFF" 1 "ON" 0 "Inactive" ;
VAL_ 237 EHC22_Set_FcwSwt 3 "Invalid" 2 "OFF" 1 "ON" 0 "Inactive" ;
VAL_ 237 EHC22_Set_FCTA 3 "Invalid" 2 "OFF" 1 "ON" 0 "Inactive" ;
VAL_ 237 EHC22_Set_FCTB 3 "Invalid" 2 "OFF" 1 "ON" 0 "Inactive" ;
VAL_ 237 EHC22_Set_LDWLKALCKSen 3 "HighSensitivity" 2 "MiddleSensitivity" 1 "LowSensitivity" 0 "no information；仅灵敏度调节菜单变灰" ;
VAL_ 237 EHC22_Sw_LDWLKALCK 3 "Invalid；（无效，维持上一个点火周期）" 2 "Off；" 1 "On；" 0 "Inactive；（上电默认状态，维持上一个点火周期）" ;
VAL_ 237 EHC22_St_LDWLKALCKSet 4 "LCK Enable(预留)；" 3 "reserved(预留)；" 2 "LKA Enable；" 1 "LDW Enable；" 0 "Inacitve；" ;
VAL_ 237 EHC22_NOAFct_EnbSw 3 "Invalid" 2 "OFF" 1 "ON" 0 "Inactive" ;
VAL_ 237 EHC22_SDA_EnbSw 3 "Invalid" 2 "OFF" 1 "ON" 0 "Inactive" ;
VAL_ 237 EHC22_Set_JA 3 "Invalid" 2 "off" 1 "on" 0 "inactive" ;
VAL_ 237 EHC22_CDCShowoffset 3 "reserved" 2 "Invalid" 1 "OFF" 0 "Inactive" ;
VAL_ 237 EHC22_Set_ELKSen 2 "HighSensitivity" 1 "LowSensitivity" 0 "Not selecte" ;
VAL_ 226 EHC25_Set_RecoverTracking 2 "取消 Cancel" 1 "确定 Confirm" 0 "No request" ;
VAL_ 226 EHC25_Set_RestoreParking 2 "取消 Cancel" 1 "确定 Confirm" 0 "No request" ;
VAL_ 226 EHC25_FastBackCar_Mode 1 "EHC处于普通倒车模式 normal back car" 0 "EHC处于快速倒车模式 fast back car" ;
VAL_ 226 EHC25_Set_ViewSource 7 "Reserved" 6 "Reserved" 5 "CCO Source" 4 "HPA Source" 3 "Tracking Source" 2 "APA Source" 1 "AVM Source" 0 "Initial" ;
VAL_ 226 EHC25_Set_AEBOption 4 "OFF" 3 "HighSensitivity" 2 "MiddleSensitivity" 1 "LowSensitivity" 0 "Not active" ;
VAL_ 226 EHC25_OPerTimeOutExit_Set 7 "Invalid" 6 "Reserved" 5 "Reserved" 4 "Reserved" 3 "No Exit" 2 "1min" 1 "30s" 0 "Inactive" ;
VAL_ 226 EHC25_Set_TLA 3 "Reserved" 2 "Not active" 1 "ON" 0 "Off" ;
VAL_ 226 EHC25_Set_SLA 3 "Reserved" 2 "Not active" 1 "ON" 0 "Off" ;
VAL_ 226 EHC25_Set_SLAWarn 3 "Reserved" 2 "Not active" 1 "ON" 0 "Off" ;
VAL_ 226 EHC25_Set_ASL 3 "Reserved" 2 "Not active" 1 "ON" 0 "Off" ;
VAL_ 226 EHC25_MODFunction_Set 3 "Invalid" 2 "Off" 1 "ON" 0 "Inactive" ;
VAL_ 226 EHC25_Set_Color 6 "未来灰光亮版EG33" 5 "丛林绿 EH09" 4 "谧夜蓝 EE28" 3 "极夜黑 EK03" 2 "迷雾蓝 EE47" 1 "苍石绿 EH35" 0 "雪域白EC19" ;
VAL_ 444 ICC_N_SlotAngle 4095 "Invalid" ;
VAL_ 444 ICC_N_CoorA_X 2047 "Invalid" ;
VAL_ 444 ICC_ATSMode 2 "OFF" 1 "ON" 0 "invalid" ;
VAL_ 444 ICC_N_CoorA_Y 2047 "Invalid" ;
VAL_ 444 ICC_ScrnAngle 511 "Invalid" ;
VAL_ 444 ICCAdasApaSocOffSwt 3 "Invalid" 2 "Off" 1 "On" 0 "Inactive" ;
VAL_ 444 ICC_AvapViewSource 7 "预留" 6 "预留" 5 "预留" 4 "预留" 3 "预留" 2 "开启-泊车辅助" 1 "开启-全景" 0 "关闭" ;
VAL_ 444 ICC_AvapSysSts 7 "预留" 6 "预留" 5 "预留" 4 "IDC通信丢失" 3 "视频流故障" 2 "全景系统故障" 1 "功能正常" 0 "Int" ;
VAL_ 444 ICCAvmCalibrationParameter 1 "Completed" 0 "Int" ;
VAL_ 444 ICCApaCalibrationReq 3 "Calibration Cancel" 2 "After-sales Calibration" 1 "Factory Calibration" 0 "NONE" ;
VAL_ 648 SWS_Cruise 1 "active" 0 "Inactive" ;
VAL_ 648 SWS_360 1 "active" 0 "Inactive" ;
VAL_ 648 SWS_AccTiGapPlus 1 "active" 0 "Inactive" ;
VAL_ 648 SWS_AccTiGapMinus 1 "active" 0 "Inactive" ;
VAL_ 648 SWS_LeRollUp 7 "焦点向上7单位" 6 "焦点向上6单位" 5 "焦点向上5单位" 4 "焦点向上4单位" 3 "焦点向上3单位" 2 "焦点向上2单位" 1 "焦点向上1单位" 0 "No Pressed未按" ;
VAL_ 648 SWS_LeRollDwn 7 "焦点向下7单位" 6 "焦点向下6单位" 5 "焦点向下5单位" 4 "焦点向下4单位" 3 "焦点向下3单位" 2 "焦点向下2单位" 1 "焦点向下1单位" 0 "No Pressed未按" ;
VAL_ 311 PDCU_PtTqAvl 7 "reserved" 6 "reserved" 5 "reserved" 4 "reserved" 3 "Failure" 2 "Available degrade" 1 "Available for control" 0 "Not available" ;
VAL_ 311 PDCU_VehDrvMotMaxElecTqVld 1 "Valid" 0 "Invalid" ;
VAL_ 311 PDCU_AVAPhandshakeSts 7 "reserved" 6 "reserved" 5 "reserved" 4 "Active_HPA" 3 "Active_MRA" 2 "Active_RPA" 1 "Active_APA" 0 "Not Active" ;
VAL_ 311 PDCU_GasPedalInhibition 1 "Inhibit" 0 "No inhibition" ;
VAL_ 311 PDCU_AVAPFltFb 7 "reserved" 6 "reserved" 5 "error5" 4 "error4" 3 "trigger without secure" 2 "Message Error" 1 "too high speed" 0 "No error" ;
VAL_ 311 PdcuApaLeverInterventionVld 3 "Reserved" 2 "Invalid" 1 "Valid" 0 "Initializing" ;
VAL_ 311 PDCU_LgtReqActiveSts 3 "Reserved" 2 "Active l3" 1 "Active l12" 0 "Not active" ;
VAL_ 311 PDCU_ADLCFailureSts 7 "reserved" 6 "reserved" 5 "error5" 4 "error4" 3 "error3" 2 "error2" 1 "error1" 0 "No error" ;
VAL_ 833 WCBS_N_EBRTrqACT 8191 "Invalid" ;
VAL_ 536 WCBS_ESP7_ReLeSnsrFlt 7 "Reserved" 6 "Reserved" 5 "Reserved" 4 "Signal Not Plausible" 3 "Open Circuit" 2 "Short Circuit to Ground" 1 "Short Circuit to Battery" 0 "No ERROR" ;
VAL_ 536 WCBS_ESP7_ReRiSnsrFlt 7 "Reserved" 6 "Reserved" 5 "Reserved" 4 "Signal Not Plausible" 3 "Open Circuit" 2 "Short Circuit to Ground" 1 "Short Circuit to Battery" 0 "No ERROR" ;
VAL_ 536 WCBS_ESP7_FrntLeSnsrFlt 7 "Reserved" 6 "Reserved" 5 "Reserved" 4 "Signal Not Plausible" 3 "Open Circuit" 2 "Short Circuit to Ground" 1 "Short Circuit to Battery" 0 "No ERROR" ;
VAL_ 536 WCBS_ESP7_FrntRiSnsrFlt 7 "Reserved" 6 "Reserved" 5 "Reserved" 4 "Signal Not Plausible" 3 "Open Circuit" 2 "Short Circuit to Ground" 1 "Short Circuit to Battery" 0 "No ERROR" ;
VAL_ 536 WCBS_ESP7_BrakeTorqOn4Wheels 16383 "Invalid" ;
VAL_ 536 IBS_VDCInfo 1 "Active" 0 "Not Active" ;
VAL_ 1583 TBOX_CrtTi_Day 30 "Day31" 0 "Day1" ;
VAL_ 1583 TBOX_CrtTi_Hr 23 "Hour 23" 0 "Hour 0" ;
VAL_ 1583 TBOX_CrtTi_Mins 59 "Mintue 59" 0 "Mintue 0" ;
VAL_ 1583 TBOX_CrtTi_Yr 255 "Year2270" 0 "Year 2015" ;
VAL_ 1583 TBOX_CrtTi_Mth 11 "December" 0 "January" ;
VAL_ 1583 TBOX_CrtTi_Sec 59 "Second 59" 0 "Second 0" ;
VAL_ 315 EPS_SteerTorqueVldByADASReq 1 "Valid" 0 "Invalid" ;
VAL_ 315 EPS_SteerSnsrSts 1 "Failure" 0 "Not Failure" ;
VAL_ 315 EPS_DrvrSteerTqDir 1 "Negative" 0 "Positive" ;
VAL_ 315 EPS_SteerDrvrOvrd_J6 1 "Override" 0 "Not override" ;
VAL_ 410 LatAcce 4095 "Invalid" ;
VAL_ 410 LgtAcce 4095 "Invalid" ;
VAL_ 410 YawRate 65535 "Invalid" ;
VAL_ 410 LatSnsrSts 3 "Reserved" 2 "Invalid" 1 "Valid" 0 "Initializing" ;
VAL_ 410 LgtSnsrSts 3 "Reserved" 2 "Invalid" 1 "Valid" 0 "Initializing" ;
VAL_ 410 YawRateSnsrSts 3 "Reserved" 2 "Invalid" 1 "Valid" 0 "Initializing" ;
VAL_ 410 YawRateSnsrCalSts 1 "Sensor Calibrated" 0 "Sensor Not Calibrated" ;
